VERSION ""

NS_ :

BS_:

BU_: PowertrainControlModule AtmosphericSensor SafetyRestraintSystem2 Aftertreatment_2_GasOutlet Aftertreatment_2_GasIntake DieselParticulateFilterControl Turbocharger SafetyRestraintSystem1 CabDisplay2 Aftertreatment_1_GasOutlet Aftertreatment_1_GasIntake OnBoardDataLogger OffBoardDiagnosticTool2 OffBoardDiagnosticTool1 FileServer ParkingBrakeController SeatController2 FanDriveController SteeringColumnUnit CommunicationUnitRadio CommunicationUnitSatellite CommunicationUnitCellular PropulsionBatteryCharger ChassisController2 ChassisController1 EngineValveControl AuxiliaryHeater2 AuxiliaryHeater1 ClutchUnit RampControl InformationSystem1 SuspensionSystemController2 OilSensor VehicleDynamicStability ExhaustEmissionController TransmissionDisplay2 TransmissionDisplay1 ClimateControl2 WaterPumpController RearAxleSteeringController LightingOperatorControl SeatController1 IgnitionController2 IgnitionController1 TirePressureController CabController2 CabController1 PneumaticSystemController SuspensionSystemController1 HydraulicPumpController EnduranceBrakingSystem RetarderExhaustEngine2 OnBoardDiagnosticUnit HeadwayController RetarderExhaustEngine1 CabDisplay1 ManagementComputer VirtualTerminal OffVehicleGateway PowerTakeOffFront HitchControl AuxiliaryValveControl BodyController TractorTrailerBridge1 StarterSystem ElectricalSystem VehicleSecurity VehicleNavigation AerodynamicControl ElectricalChargingSystem ClimateControl1 TripRecorder InstrumentCluster SuspensionDriveAxle2 SuspensionDriveAxle1 SuspensionSteerAxle SteeringController FuelSystem CruiseControl RetarderDriveline RetarderEngine BrakesDriveAxle2 BrakesDriveAxle1 BrakesSystemController BrakesSteerAxle AxleDrive2 AxleDrive1 AxleSteering PowerTakeOff ShiftConsoleSecondary ShiftConsolePrimary Transmission2 Transmission1 Engine2 Engine1

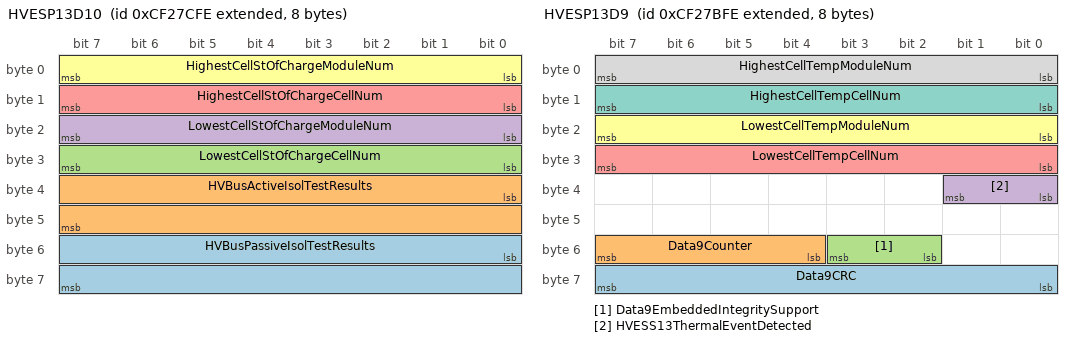
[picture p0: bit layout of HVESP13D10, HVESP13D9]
BO_ 2364701950 HVESP13D10: 8 Vector__XXX
 SG_ HVBusPassiveIsolTestResults : 48|16@1+ (0.1,0) [0|6425.5] "Ohm/V" Vector__XXX
 SG_ HVBusActiveIsolTestResults : 32|16@1+ (0.1,0) [0|6425.5] "Ohm/V" Vector__XXX
 SG_ LowestCellStOfChargeCellNum : 24|8@1+ (1,0) [0|250] "" Vector__XXX
 SG_ LowestCellStOfChargeModuleNum : 16|8@1+ (1,0) [0|250] "" Vector__XXX
 SG_ HighestCellStOfChargeCellNum : 8|8@1+ (1,0) [0|250] "" Vector__XXX
 SG_ HighestCellStOfChargeModuleNum : 0|8@1+ (1,0) [0|250] "" Vector__XXX

BO_ 2364701694 HVESP13D9: 8 Vector__XXX
 SG_ Data9CRC : 56|8@1+ (1,0) [0|255] "" Vector__XXX
 SG_ Data9Counter : 52|4@1+ (1,0) [0|15] "" Vector__XXX
 SG_ Data9EmbeddedIntegritySupport : 50|2@1+ (1,0) [0|3] "" Vector__XXX
 SG_ HVESS13ThermalEventDetected : 32|2@1+ (1,0) [0|3] "" Vector__XXX
 SG_ LowestCellTempCellNum : 24|8@1+ (1,0) [0|250] "" Vector__XXX
 SG_ LowestCellTempModuleNum : 16|8@1+ (1,0) [0|250] "" Vector__XXX
 SG_ HighestCellTempCellNum : 8|8@1+ (1,0) [0|250] "" Vector__XXX
 SG_ HighestCellTempModuleNum : 0|8@1+ (1,0) [0|250] "" Vector__XXX

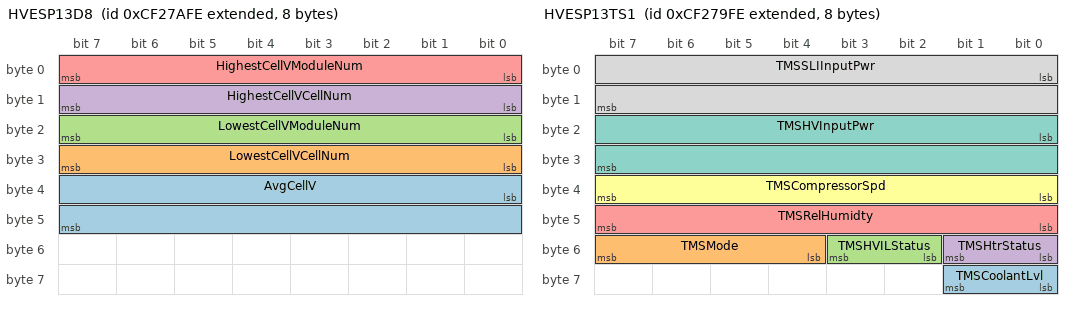
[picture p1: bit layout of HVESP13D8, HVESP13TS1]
BO_ 2364701438 HVESP13D8: 8 Vector__XXX
 SG_ AvgCellV : 32|16@1+ (0.001,0) [0|64.255] "V" Vector__XXX
 SG_ LowestCellVCellNum : 24|8@1+ (1,0) [0|250] "" Vector__XXX
 SG_ LowestCellVModuleNum : 16|8@1+ (1,0) [0|250] "" Vector__XXX
 SG_ HighestCellVCellNum : 8|8@1+ (1,0) [0|250] "" Vector__XXX
 SG_ HighestCellVModuleNum : 0|8@1+ (1,0) [0|250] "" Vector__XXX

BO_ 2364701182 HVESP13TS1: 8 Vector__XXX
 SG_ TMSCoolantLvl : 56|2@1+ (1,0) [0|3] "" Vector__XXX
 SG_ TMSMode : 52|4@1+ (1,0) [0|15] "" Vector__XXX
 SG_ TMSHVILStatus : 50|2@1+ (1,0) [0|3] "" Vector__XXX
 SG_ TMSHtrStatus : 48|2@1+ (1,0) [0|3] "" Vector__XXX
 SG_ TMSRelHumidty : 40|8@1+ (0.4,0) [0|100] "%" Vector__XXX
 SG_ TMSCompressorSpd : 32|8@1+ (32,0) [0|8000] "rpm" Vector__XXX
 SG_ TMSHVInputPwr : 16|16@1+ (0.5,0) [0|32127.5] "W" Vector__XXX
 SG_ TMSSLIInputPwr : 0|16@1+ (0.5,0) [0|32127.5] "W" Vector__XXX

BO_ 2364700926 HVESP13MS1: 8 Vector__XXX
 SG_ Module32OperationalStatus : 62|2@1+ (1,0) [0|3] "" Vector__XXX
 SG_ Module31OperationalStatus : 60|2@1+ (1,0) [0|3] "" Vector__XXX
 SG_ Module30OperationalStatus : 58|2@1+ (1,0) [0|3] "" Vector__XXX
 SG_ Module29OperationalStatus : 56|2@1+ (1,0) [0|3] "" Vector__XXX
 SG_ Module28OperationalStatus : 54|2@1+ (1,0) [0|3] "" Vector__XXX
 SG_ Module27OperationalStatus : 52|2@1+ (1,0) [0|3] "" Vector__XXX
 SG_ Module26OperationalStatus : 50|2@1+ (1,0) [0|3] "" Vector__XXX
 SG_ Module25OperationalStatus : 48|2@1+ (1,0) [0|3] "" Vector__XXX
 SG_ Module24OperationalStatus : 46|2@1+ (1,0) [0|3] "" Vector__XXX
 SG_ Module23OperationalStatus : 44|2@1+ (1,0) [0|3] "" Vector__XXX
 SG_ Module22OperationalStatus : 42|2@1+ (1,0) [0|3] "" Vector__XXX
 SG_ Module21OperationalStatus : 40|2@1+ (1,0) [0|3] "" Vector__XXX
 SG_ Module20OperationalStatus : 38|2@1+ (1,0) [0|3] "" Vector__XXX
 SG_ Module19OperationalStatus : 36|2@1+ (1,0) [0|3] "" Vector__XXX
 SG_ Module18OperationalStatus : 34|2@1+ (1,0) [0|3] "" Vector__XXX
 SG_ Module17OperationalStatus : 32|2@1+ (1,0) [0|3] "" Vector__XXX
 SG_ Module16OperationalStatus : 30|2@1+ (1,0) [0|3] "" Vector__XXX
 SG_ Module15OperationalStatus : 28|2@1+ (1,0) [0|3] "" Vector__XXX
 SG_ Module14OperationalStatus : 26|2@1+ (1,0) [0|3] "" Vector__XXX
 SG_ Module13OperationalStatus : 24|2@1+ (1,0) [0|3] "" Vector__XXX
 SG_ Module12OperationalStatus : 22|2@1+ (1,0) [0|3] "" Vector__XXX
 SG_ Module11OperationalStatus : 20|2@1+ (1,0) [0|3] "" Vector__XXX
 SG_ Module10OperationalStatus : 18|2@1+ (1,0) [0|3] "" Vector__XXX
 SG_ Module9OperationalStatus : 16|2@1+ (1,0) [0|3] "" Vector__XXX
 SG_ Module8OperationalStatus : 14|2@1+ (1,0) [0|3] "" Vector__XXX
 SG_ Module7OperationalStatus : 12|2@1+ (1,0) [0|3] "" Vector__XXX
 SG_ Module6OperationalStatus : 10|2@1+ (1,0) [0|3] "" Vector__XXX
 SG_ Module5OperationalStatus : 8|2@1+ (1,0) [0|3] "" Vector__XXX
 SG_ Module4OperationalStatus : 6|2@1+ (1,0) [0|3] "" Vector__XXX
 SG_ Module3OperationalStatus : 4|2@1+ (1,0) [0|3] "" Vector__XXX
 SG_ Module2OperationalStatus : 2|2@1+ (1,0) [0|3] "" Vector__XXX
 SG_ Module1OperationalStatus : 0|2@1+ (1,0) [0|3] "" Vector__XXX

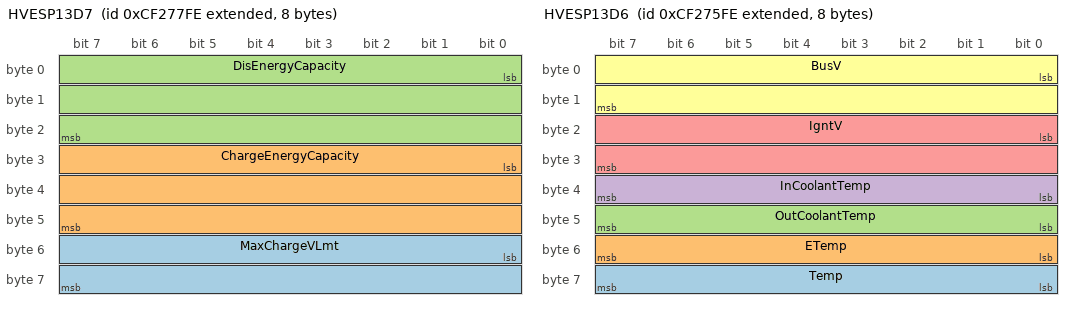
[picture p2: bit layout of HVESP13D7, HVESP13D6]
BO_ 2364700670 HVESP13D7: 8 Vector__XXX
 SG_ MaxChargeVLmt : 48|16@1+ (0.05,0) [0|3212.75] "V" Vector__XXX
 SG_ ChargeEnergyCapacity : 24|24@1+ (0.001,0) [0|16449.535] "kWh" Vector__XXX
 SG_ DisEnergyCapacity : 0|24@1+ (0.001,0) [0|16449.535] "kWh" Vector__XXX

BO_ 2364700414 HVESP13S1: 8 Vector__XXX
 SG_ Status1CRC : 56|8@1+ (1,0) [0|255] "" Vector__XXX
 SG_ Status1Counter : 52|4@1+ (1,0) [0|15] "" Vector__XXX
 SG_ OperationalStatus : 44|4@1+ (1,0) [0|15] "" Vector__XXX
 SG_ HVBusConnectionStatus : 40|4@1+ (1,0) [0|15] "" Vector__XXX
 SG_ InternalChargerStatus : 32|2@1+ (1,0) [0|3] "" Vector__XXX
 SG_ CellBalancingActive : 30|2@1+ (1,0) [0|3] "" Vector__XXX
 SG_ CellBalanceStatus : 28|2@1+ (1,0) [0|3] "" Vector__XXX
 SG_ StOfChargeStatus : 24|4@1+ (1,0) [0|15] "" Vector__XXX
 SG_ InertiaSwStatus : 22|2@1+ (1,0) [0|3] "" Vector__XXX
 SG_ HVILStatus : 20|2@1+ (1,0) [0|3] "" Vector__XXX
 SG_ HVBusPassiveIsolTestStatus : 16|4@1+ (1,0) [0|15] "" Vector__XXX
 SG_ HVBusActiveIsolTestStatus : 12|4@1+ (1,0) [0|15] "" Vector__XXX
 SG_ CenterOfPackContactorSt : 10|2@1+ (1,0) [0|3] "" Vector__XXX
 SG_ HVBusPreChargeRelaySt : 8|2@1+ (1,0) [0|3] "" Vector__XXX
 SG_ HVBusDisconnectForewarning : 4|4@1+ (1,0) [0|15] "" Vector__XXX
 SG_ HVBusContactorSt15602 : 2|2@1+ (1,0) [0|3] "" Vector__XXX
 SG_ HVBusContactorSt : 0|2@1+ (1,0) [0|3] "" Vector__XXX

BO_ 2364700158 HVESP13D6: 8 Vector__XXX
 SG_ Temp : 56|8@1+ (1,-40) [-40|210] "°C" Vector__XXX
 SG_ ETemp : 48|8@1+ (1,-40) [-40|210] "°C" Vector__XXX
 SG_ OutCoolantTemp : 40|8@1+ (1,-40) [-40|210] "°C" Vector__XXX
 SG_ InCoolantTemp : 32|8@1+ (1,-40) [-40|210] "°C" Vector__XXX
 SG_ IgntV : 16|16@1+ (0.01,0) [0|642.55] "V" Vector__XXX
 SG_ BusV : 0|16@1+ (0.05,0) [0|3212.75] "V" Vector__XXX

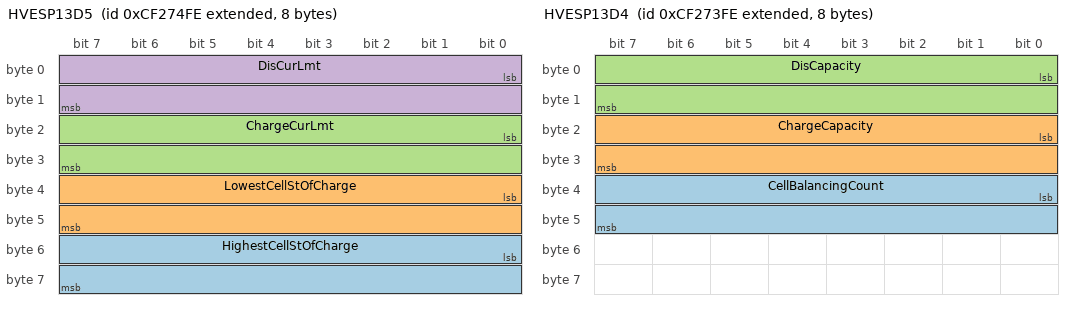
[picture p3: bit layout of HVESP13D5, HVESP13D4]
BO_ 2364699902 HVESP13D5: 8 Vector__XXX
 SG_ HighestCellStOfCharge : 48|16@1+ (0.0015625,0) [0|100.3984375] "%" Vector__XXX
 SG_ LowestCellStOfCharge : 32|16@1+ (0.0015625,0) [0|100.3984375] "%" Vector__XXX
 SG_ ChargeCurLmt : 16|16@1+ (0.05,-1600) [0|1612.75] "A" Vector__XXX
 SG_ DisCurLmt : 0|16@1+ (0.05,-1600) [-1600|0] "A" Vector__XXX

BO_ 2364699646 HVESP13D4: 8 Vector__XXX
 SG_ CellBalancingCount : 32|16@1+ (1,0) [0|64255] "" Vector__XXX
 SG_ ChargeCapacity : 16|16@1+ (0.01,0) [0|642.55] "Ah" Vector__XXX
 SG_ DisCapacity : 0|16@1+ (0.01,0) [0|642.55] "Ah" Vector__XXX

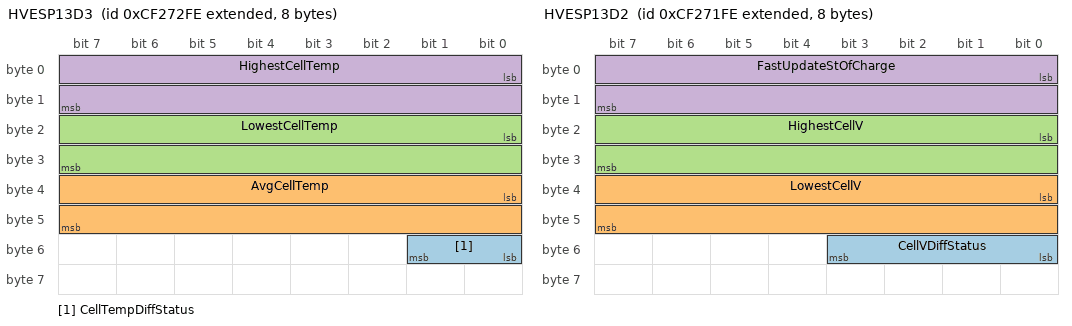
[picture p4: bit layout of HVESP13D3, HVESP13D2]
BO_ 2364699390 HVESP13D3: 8 Vector__XXX
 SG_ CellTempDiffStatus : 48|2@1+ (1,0) [0|3] "" Vector__XXX
 SG_ AvgCellTemp : 32|16@1+ (0.03125,-273) [-273|1734.96875] "°C" Vector__XXX
 SG_ LowestCellTemp : 16|16@1+ (0.03125,-273) [-273|1734.96875] "°C" Vector__XXX
 SG_ HighestCellTemp : 0|16@1+ (0.03125,-273) [-273|1734.96875] "°C" Vector__XXX

BO_ 2364699134 HVESP13D2: 8 Vector__XXX
 SG_ CellVDiffStatus : 48|4@1+ (1,0) [0|15] "" Vector__XXX
 SG_ LowestCellV : 32|16@1+ (0.001,0) [0|64.255] "V" Vector__XXX
 SG_ HighestCellV : 16|16@1+ (0.001,0) [0|64.255] "V" Vector__XXX
 SG_ FastUpdateStOfCharge : 0|16@1+ (0.0015625,0) [0|100.3984375] "%" Vector__XXX

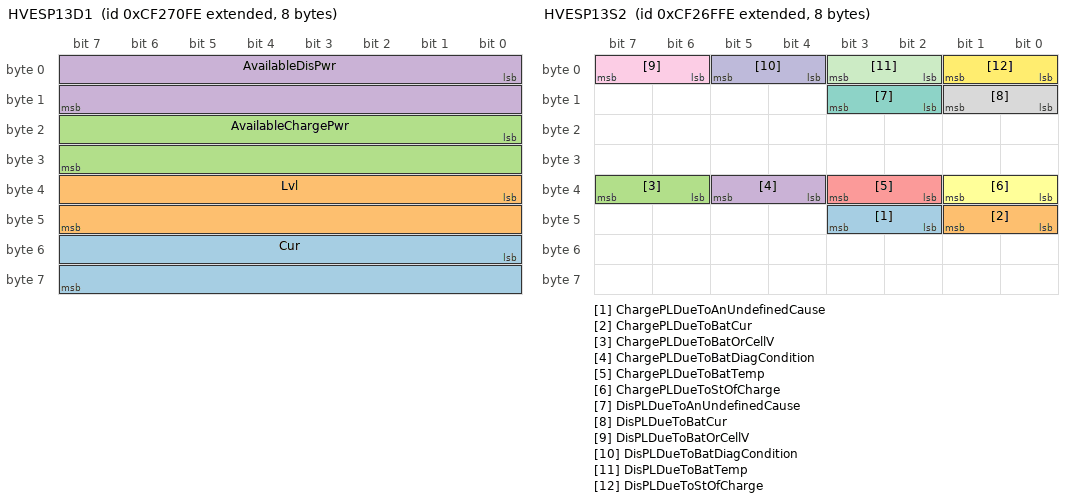
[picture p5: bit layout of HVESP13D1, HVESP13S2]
BO_ 2364698878 HVESP13D1: 8 Vector__XXX
 SG_ Cur : 48|16@1+ (0.05,-1600) [-1600|1612.75] "A" Vector__XXX
 SG_ Lvl : 32|16@1+ (0.05,0) [0|3212.75] "V" Vector__XXX
 SG_ AvailableChargePwr : 16|16@1+ (0.05,0) [0|3212.75] "kW" Vector__XXX
 SG_ AvailableDisPwr : 0|16@1+ (0.05,0) [0|3212.75] "kW" Vector__XXX

BO_ 2364698622 HVESP13S2: 8 Vector__XXX
 SG_ ChargePLDueToAnUndefinedCause : 42|2@1+ (1,0) [0|3] "" Vector__XXX
 SG_ ChargePLDueToBatCur : 40|2@1+ (1,0) [0|3] "" Vector__XXX
 SG_ ChargePLDueToBatOrCellV : 38|2@1+ (1,0) [0|3] "" Vector__XXX
 SG_ ChargePLDueToBatDiagCondition : 36|2@1+ (1,0) [0|3] "" Vector__XXX
 SG_ ChargePLDueToBatTemp : 34|2@1+ (1,0) [0|3] "" Vector__XXX
 SG_ ChargePLDueToStOfCharge : 32|2@1+ (1,0) [0|3] "" Vector__XXX
 SG_ DisPLDueToAnUndefinedCause : 10|2@1+ (1,0) [0|3] "" Vector__XXX
 SG_ DisPLDueToBatCur : 8|2@1+ (1,0) [0|3] "" Vector__XXX
 SG_ DisPLDueToBatOrCellV : 6|2@1+ (1,0) [0|3] "" Vector__XXX
 SG_ DisPLDueToBatDiagCondition : 4|2@1+ (1,0) [0|3] "" Vector__XXX
 SG_ DisPLDueToBatTemp : 2|2@1+ (1,0) [0|3] "" Vector__XXX
 SG_ DisPLDueToStOfCharge : 0|2@1+ (1,0) [0|3] "" Vector__XXX

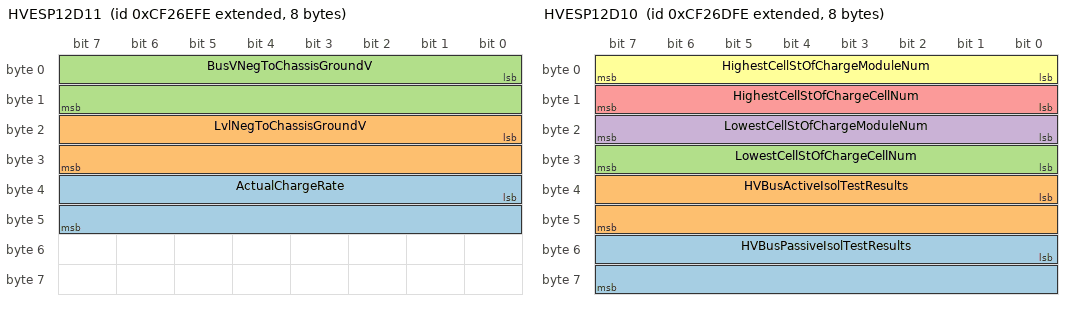
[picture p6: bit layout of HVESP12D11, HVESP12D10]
BO_ 2364698366 HVESP12D11: 8 Vector__XXX
 SG_ ActualChargeRate : 32|16@1+ (0.05,0) [0|3212.75] "kW" Vector__XXX
 SG_ LvlNegToChassisGroundV : 16|16@1+ (0.05,0) [0|3212.75] "V" Vector__XXX
 SG_ BusVNegToChassisGroundV : 0|16@1+ (0.05,0) [0|3212.75] "V" Vector__XXX

BO_ 2364698110 HVESP12D10: 8 Vector__XXX
 SG_ HVBusPassiveIsolTestResults : 48|16@1+ (0.1,0) [0|6425.5] "Ohm/V" Vector__XXX
 SG_ HVBusActiveIsolTestResults : 32|16@1+ (0.1,0) [0|6425.5] "Ohm/V" Vector__XXX
 SG_ LowestCellStOfChargeCellNum : 24|8@1+ (1,0) [0|250] "" Vector__XXX
 SG_ LowestCellStOfChargeModuleNum : 16|8@1+ (1,0) [0|250] "" Vector__XXX
 SG_ HighestCellStOfChargeCellNum : 8|8@1+ (1,0) [0|250] "" Vector__XXX
 SG_ HighestCellStOfChargeModuleNum : 0|8@1+ (1,0) [0|250] "" Vector__XXX

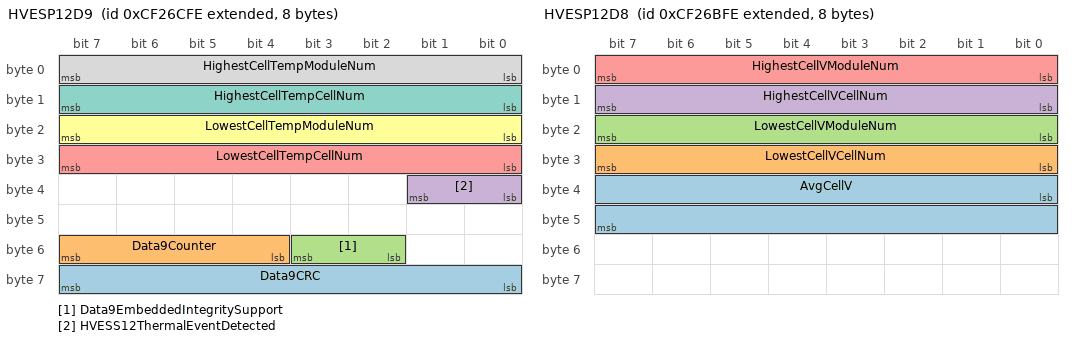
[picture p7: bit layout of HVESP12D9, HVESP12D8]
BO_ 2364697854 HVESP12D9: 8 Vector__XXX
 SG_ Data9CRC : 56|8@1+ (1,0) [0|255] "" Vector__XXX
 SG_ Data9Counter : 52|4@1+ (1,0) [0|15] "" Vector__XXX
 SG_ Data9EmbeddedIntegritySupport : 50|2@1+ (1,0) [0|3] "" Vector__XXX
 SG_ HVESS12ThermalEventDetected : 32|2@1+ (1,0) [0|3] "" Vector__XXX
 SG_ LowestCellTempCellNum : 24|8@1+ (1,0) [0|250] "" Vector__XXX
 SG_ LowestCellTempModuleNum : 16|8@1+ (1,0) [0|250] "" Vector__XXX
 SG_ HighestCellTempCellNum : 8|8@1+ (1,0) [0|250] "" Vector__XXX
 SG_ HighestCellTempModuleNum : 0|8@1+ (1,0) [0|250] "" Vector__XXX

BO_ 2364697598 HVESP12D8: 8 Vector__XXX
 SG_ AvgCellV : 32|16@1+ (0.001,0) [0|64.255] "V" Vector__XXX
 SG_ LowestCellVCellNum : 24|8@1+ (1,0) [0|250] "" Vector__XXX
 SG_ LowestCellVModuleNum : 16|8@1+ (1,0) [0|250] "" Vector__XXX
 SG_ HighestCellVCellNum : 8|8@1+ (1,0) [0|250] "" Vector__XXX
 SG_ HighestCellVModuleNum : 0|8@1+ (1,0) [0|250] "" Vector__XXX

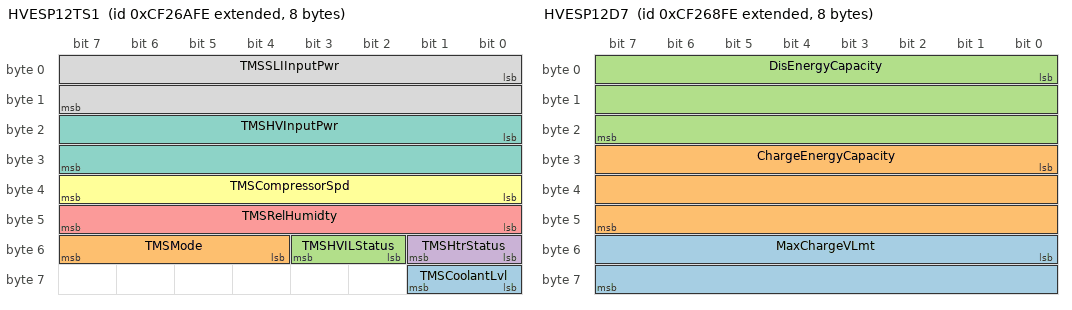
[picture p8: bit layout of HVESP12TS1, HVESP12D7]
BO_ 2364697342 HVESP12TS1: 8 Vector__XXX
 SG_ TMSCoolantLvl : 56|2@1+ (1,0) [0|3] "" Vector__XXX
 SG_ TMSMode : 52|4@1+ (1,0) [0|15] "" Vector__XXX
 SG_ TMSHVILStatus : 50|2@1+ (1,0) [0|3] "" Vector__XXX
 SG_ TMSHtrStatus : 48|2@1+ (1,0) [0|3] "" Vector__XXX
 SG_ TMSRelHumidty : 40|8@1+ (0.4,0) [0|100] "%" Vector__XXX
 SG_ TMSCompressorSpd : 32|8@1+ (32,0) [0|8000] "rpm" Vector__XXX
 SG_ TMSHVInputPwr : 16|16@1+ (0.5,0) [0|32127.5] "W" Vector__XXX
 SG_ TMSSLIInputPwr : 0|16@1+ (0.5,0) [0|32127.5] "W" Vector__XXX

BO_ 2364697086 HVESP12MS1: 8 Vector__XXX
 SG_ Module32OperationalStatus : 62|2@1+ (1,0) [0|3] "" Vector__XXX
 SG_ Module31OperationalStatus : 60|2@1+ (1,0) [0|3] "" Vector__XXX
 SG_ Module30OperationalStatus : 58|2@1+ (1,0) [0|3] "" Vector__XXX
 SG_ Module29OperationalStatus : 56|2@1+ (1,0) [0|3] "" Vector__XXX
 SG_ Module28OperationalStatus : 54|2@1+ (1,0) [0|3] "" Vector__XXX
 SG_ Module27OperationalStatus : 52|2@1+ (1,0) [0|3] "" Vector__XXX
 SG_ Module26OperationalStatus : 50|2@1+ (1,0) [0|3] "" Vector__XXX
 SG_ Module25OperationalStatus : 48|2@1+ (1,0) [0|3] "" Vector__XXX
 SG_ Module24OperationalStatus : 46|2@1+ (1,0) [0|3] "" Vector__XXX
 SG_ Module23OperationalStatus : 44|2@1+ (1,0) [0|3] "" Vector__XXX
 SG_ Module22OperationalStatus : 42|2@1+ (1,0) [0|3] "" Vector__XXX
 SG_ Module21OperationalStatus : 40|2@1+ (1,0) [0|3] "" Vector__XXX
 SG_ Module20OperationalStatus : 38|2@1+ (1,0) [0|3] "" Vector__XXX
 SG_ Module19OperationalStatus : 36|2@1+ (1,0) [0|3] "" Vector__XXX
 SG_ Module18OperationalStatus : 34|2@1+ (1,0) [0|3] "" Vector__XXX
 SG_ Module17OperationalStatus : 32|2@1+ (1,0) [0|3] "" Vector__XXX
 SG_ Module16OperationalStatus : 30|2@1+ (1,0) [0|3] "" Vector__XXX
 SG_ Module15OperationalStatus : 28|2@1+ (1,0) [0|3] "" Vector__XXX
 SG_ Module14OperationalStatus : 26|2@1+ (1,0) [0|3] "" Vector__XXX
 SG_ Module13OperationalStatus : 24|2@1+ (1,0) [0|3] "" Vector__XXX
 SG_ Module12OperationalStatus : 22|2@1+ (1,0) [0|3] "" Vector__XXX
 SG_ Module11OperationalStatus : 20|2@1+ (1,0) [0|3] "" Vector__XXX
 SG_ Module10OperationalStatus : 18|2@1+ (1,0) [0|3] "" Vector__XXX
 SG_ Module9OperationalStatus : 16|2@1+ (1,0) [0|3] "" Vector__XXX
 SG_ Module8OperationalStatus : 14|2@1+ (1,0) [0|3] "" Vector__XXX
 SG_ Module7OperationalStatus : 12|2@1+ (1,0) [0|3] "" Vector__XXX
 SG_ Module6OperationalStatus : 10|2@1+ (1,0) [0|3] "" Vector__XXX
 SG_ Module5OperationalStatus : 8|2@1+ (1,0) [0|3] "" Vector__XXX
 SG_ Module4OperationalStatus : 6|2@1+ (1,0) [0|3] "" Vector__XXX
 SG_ Module3OperationalStatus : 4|2@1+ (1,0) [0|3] "" Vector__XXX
 SG_ Module2OperationalStatus : 2|2@1+ (1,0) [0|3] "" Vector__XXX
 SG_ Module1OperationalStatus : 0|2@1+ (1,0) [0|3] "" Vector__XXX

BO_ 2364696830 HVESP12D7: 8 Vector__XXX
 SG_ MaxChargeVLmt : 48|16@1+ (0.05,0) [0|3212.75] "V" Vector__XXX
 SG_ ChargeEnergyCapacity : 24|24@1+ (0.001,0) [0|16449.535] "kWh" Vector__XXX
 SG_ DisEnergyCapacity : 0|24@1+ (0.001,0) [0|16449.535] "kWh" Vector__XXX

BO_ 2364696574 HVESP12S1: 8 Vector__XXX
 SG_ Status1CRC : 56|8@1+ (1,0) [0|255] "" Vector__XXX
 SG_ Status1Counter : 52|4@1+ (1,0) [0|15] "" Vector__XXX
 SG_ OperationalStatus : 44|4@1+ (1,0) [0|15] "" Vector__XXX
 SG_ HVBusConnectionStatus : 40|4@1+ (1,0) [0|15] "" Vector__XXX
 SG_ InternalChargerStatus : 32|2@1+ (1,0) [0|3] "" Vector__XXX
 SG_ CellBalancingActive : 30|2@1+ (1,0) [0|3] "" Vector__XXX
 SG_ CellBalanceStatus : 28|2@1+ (1,0) [0|3] "" Vector__XXX
 SG_ StOfChargeStatus : 24|4@1+ (1,0) [0|15] "" Vector__XXX
 SG_ InertiaSwStatus : 22|2@1+ (1,0) [0|3] "" Vector__XXX
 SG_ HVILStatus : 20|2@1+ (1,0) [0|3] "" Vector__XXX
 SG_ HVBusPassiveIsolTestStatus : 16|4@1+ (1,0) [0|15] "" Vector__XXX
 SG_ HVBusActiveIsolTestStatus : 12|4@1+ (1,0) [0|15] "" Vector__XXX
 SG_ CenterOfPackContactorSt : 10|2@1+ (1,0) [0|3] "" Vector__XXX
 SG_ HVBusPreChargeRelaySt : 8|2@1+ (1,0) [0|3] "" Vector__XXX
 SG_ HVBusDisconnectForewarning : 4|4@1+ (1,0) [0|15] "" Vector__XXX
 SG_ HVBusContactorSt15460 : 2|2@1+ (1,0) [0|3] "" Vector__XXX
 SG_ HVBusContactorSt : 0|2@1+ (1,0) [0|3] "" Vector__XXX

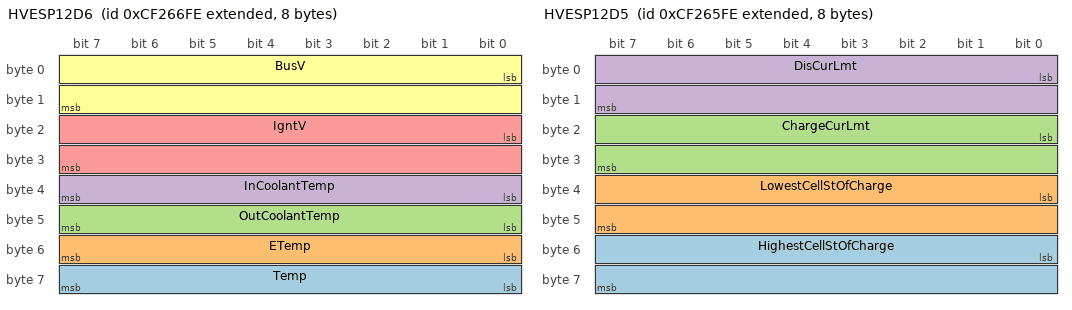
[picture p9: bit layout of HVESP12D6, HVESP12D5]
BO_ 2364696318 HVESP12D6: 8 Vector__XXX
 SG_ Temp : 56|8@1+ (1,-40) [-40|210] "°C" Vector__XXX
 SG_ ETemp : 48|8@1+ (1,-40) [-40|210] "°C" Vector__XXX
 SG_ OutCoolantTemp : 40|8@1+ (1,-40) [-40|210] "°C" Vector__XXX
 SG_ InCoolantTemp : 32|8@1+ (1,-40) [-40|210] "°C" Vector__XXX
 SG_ IgntV : 16|16@1+ (0.01,0) [0|642.55] "V" Vector__XXX
 SG_ BusV : 0|16@1+ (0.05,0) [0|3212.75] "V" Vector__XXX

BO_ 2364696062 HVESP12D5: 8 Vector__XXX
 SG_ HighestCellStOfCharge : 48|16@1+ (0.0015625,0) [0|100.3984375] "%" Vector__XXX
 SG_ LowestCellStOfCharge : 32|16@1+ (0.0015625,0) [0|100.3984375] "%" Vector__XXX
 SG_ ChargeCurLmt : 16|16@1+ (0.05,-1600) [0|1612.75] "A" Vector__XXX
 SG_ DisCurLmt : 0|16@1+ (0.05,-1600) [-1600|0] "A" Vector__XXX

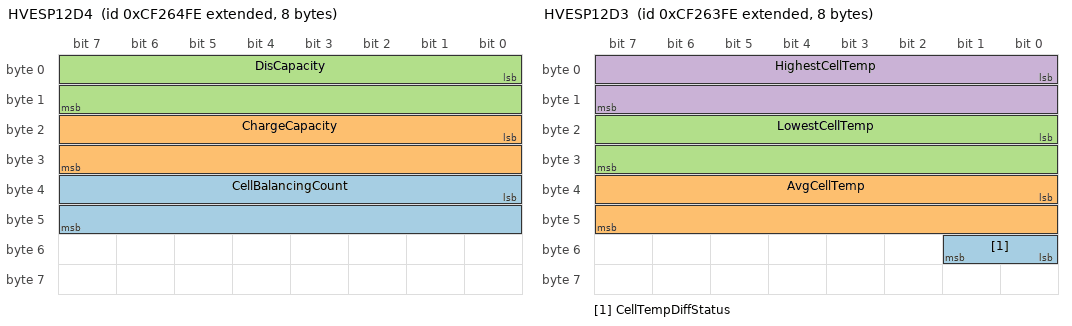
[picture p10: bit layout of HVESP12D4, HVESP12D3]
BO_ 2364695806 HVESP12D4: 8 Vector__XXX
 SG_ CellBalancingCount : 32|16@1+ (1,0) [0|64255] "" Vector__XXX
 SG_ ChargeCapacity : 16|16@1+ (0.01,0) [0|642.55] "Ah" Vector__XXX
 SG_ DisCapacity : 0|16@1+ (0.01,0) [0|642.55] "Ah" Vector__XXX

BO_ 2364695550 HVESP12D3: 8 Vector__XXX
 SG_ CellTempDiffStatus : 48|2@1+ (1,0) [0|3] "" Vector__XXX
 SG_ AvgCellTemp : 32|16@1+ (0.03125,-273) [-273|1734.96875] "°C" Vector__XXX
 SG_ LowestCellTemp : 16|16@1+ (0.03125,-273) [-273|1734.96875] "°C" Vector__XXX
 SG_ HighestCellTemp : 0|16@1+ (0.03125,-273) [-273|1734.96875] "°C" Vector__XXX

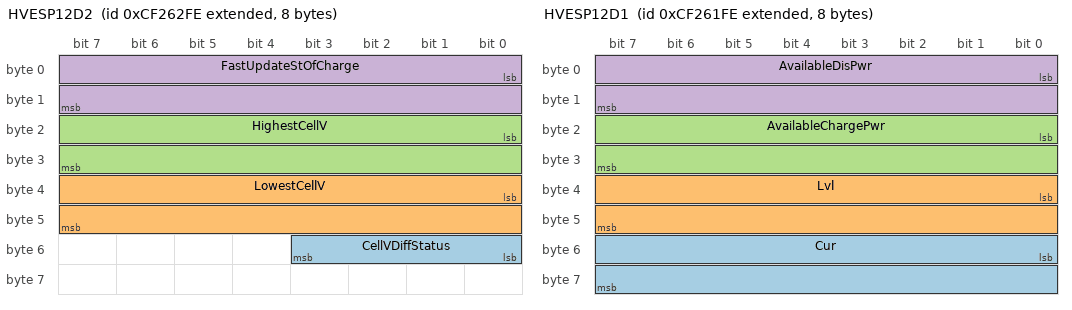
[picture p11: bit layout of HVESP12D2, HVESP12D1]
BO_ 2364695294 HVESP12D2: 8 Vector__XXX
 SG_ CellVDiffStatus : 48|4@1+ (1,0) [0|15] "" Vector__XXX
 SG_ LowestCellV : 32|16@1+ (0.001,0) [0|64.255] "V" Vector__XXX
 SG_ HighestCellV : 16|16@1+ (0.001,0) [0|64.255] "V" Vector__XXX
 SG_ FastUpdateStOfCharge : 0|16@1+ (0.0015625,0) [0|100.3984375] "%" Vector__XXX

BO_ 2364695038 HVESP12D1: 8 Vector__XXX
 SG_ Cur : 48|16@1+ (0.05,-1600) [-1600|1612.75] "A" Vector__XXX
 SG_ Lvl : 32|16@1+ (0.05,0) [0|3212.75] "V" Vector__XXX
 SG_ AvailableChargePwr : 16|16@1+ (0.05,0) [0|3212.75] "kW" Vector__XXX
 SG_ AvailableDisPwr : 0|16@1+ (0.05,0) [0|3212.75] "kW" Vector__XXX

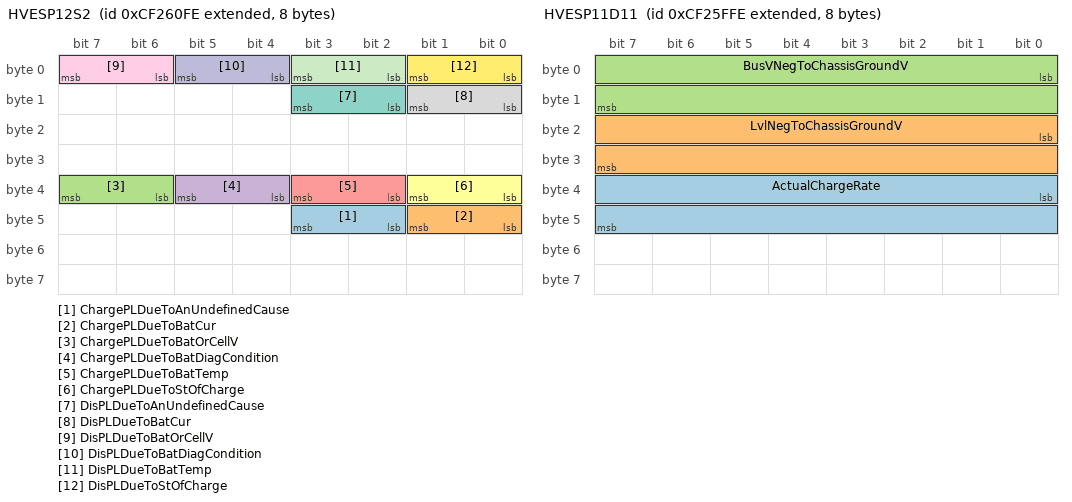
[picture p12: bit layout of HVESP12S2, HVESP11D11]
BO_ 2364694782 HVESP12S2: 8 Vector__XXX
 SG_ ChargePLDueToAnUndefinedCause : 42|2@1+ (1,0) [0|3] "" Vector__XXX
 SG_ ChargePLDueToBatCur : 40|2@1+ (1,0) [0|3] "" Vector__XXX
 SG_ ChargePLDueToBatOrCellV : 38|2@1+ (1,0) [0|3] "" Vector__XXX
 SG_ ChargePLDueToBatDiagCondition : 36|2@1+ (1,0) [0|3] "" Vector__XXX
 SG_ ChargePLDueToBatTemp : 34|2@1+ (1,0) [0|3] "" Vector__XXX
 SG_ ChargePLDueToStOfCharge : 32|2@1+ (1,0) [0|3] "" Vector__XXX
 SG_ DisPLDueToAnUndefinedCause : 10|2@1+ (1,0) [0|3] "" Vector__XXX
 SG_ DisPLDueToBatCur : 8|2@1+ (1,0) [0|3] "" Vector__XXX
 SG_ DisPLDueToBatOrCellV : 6|2@1+ (1,0) [0|3] "" Vector__XXX
 SG_ DisPLDueToBatDiagCondition : 4|2@1+ (1,0) [0|3] "" Vector__XXX
 SG_ DisPLDueToBatTemp : 2|2@1+ (1,0) [0|3] "" Vector__XXX
 SG_ DisPLDueToStOfCharge : 0|2@1+ (1,0) [0|3] "" Vector__XXX

BO_ 2364694526 HVESP11D11: 8 Vector__XXX
 SG_ ActualChargeRate : 32|16@1+ (0.05,0) [0|3212.75] "kW" Vector__XXX
 SG_ LvlNegToChassisGroundV : 16|16@1+ (0.05,0) [0|3212.75] "V" Vector__XXX
 SG_ BusVNegToChassisGroundV : 0|16@1+ (0.05,0) [0|3212.75] "V" Vector__XXX

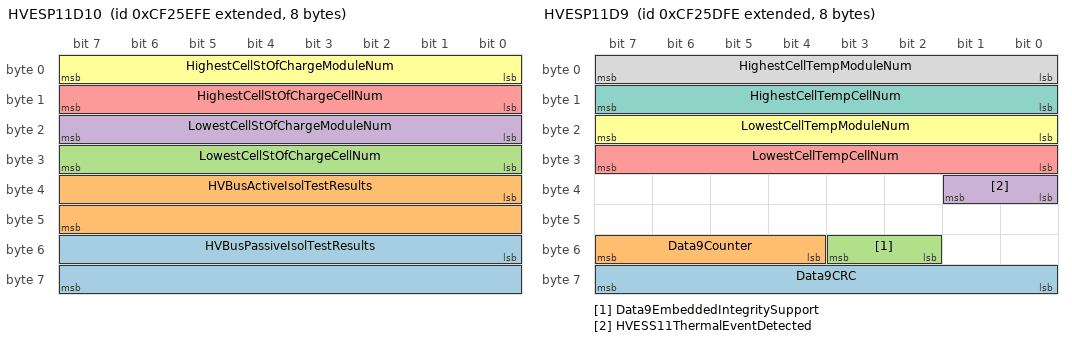
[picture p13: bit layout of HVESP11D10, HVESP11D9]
BO_ 2364694270 HVESP11D10: 8 Vector__XXX
 SG_ HVBusPassiveIsolTestResults : 48|16@1+ (0.1,0) [0|6425.5] "Ohm/V" Vector__XXX
 SG_ HVBusActiveIsolTestResults : 32|16@1+ (0.1,0) [0|6425.5] "Ohm/V" Vector__XXX
 SG_ LowestCellStOfChargeCellNum : 24|8@1+ (1,0) [0|250] "" Vector__XXX
 SG_ LowestCellStOfChargeModuleNum : 16|8@1+ (1,0) [0|250] "" Vector__XXX
 SG_ HighestCellStOfChargeCellNum : 8|8@1+ (1,0) [0|250] "" Vector__XXX
 SG_ HighestCellStOfChargeModuleNum : 0|8@1+ (1,0) [0|250] "" Vector__XXX

BO_ 2364694014 HVESP11D9: 8 Vector__XXX
 SG_ Data9CRC : 56|8@1+ (1,0) [0|255] "" Vector__XXX
 SG_ Data9Counter : 52|4@1+ (1,0) [0|15] "" Vector__XXX
 SG_ Data9EmbeddedIntegritySupport : 50|2@1+ (1,0) [0|3] "" Vector__XXX
 SG_ HVESS11ThermalEventDetected : 32|2@1+ (1,0) [0|3] "" Vector__XXX
 SG_ LowestCellTempCellNum : 24|8@1+ (1,0) [0|250] "" Vector__XXX
 SG_ LowestCellTempModuleNum : 16|8@1+ (1,0) [0|250] "" Vector__XXX
 SG_ HighestCellTempCellNum : 8|8@1+ (1,0) [0|250] "" Vector__XXX
 SG_ HighestCellTempModuleNum : 0|8@1+ (1,0) [0|250] "" Vector__XXX

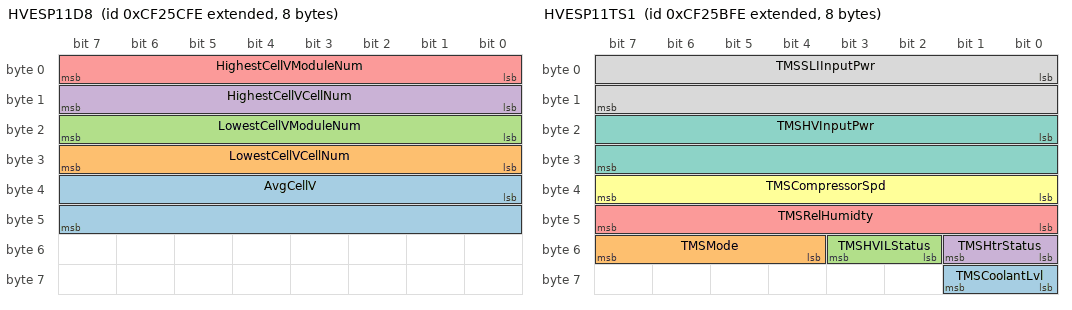
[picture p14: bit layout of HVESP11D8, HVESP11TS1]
BO_ 2364693758 HVESP11D8: 8 Vector__XXX
 SG_ AvgCellV : 32|16@1+ (0.001,0) [0|64.255] "V" Vector__XXX
 SG_ LowestCellVCellNum : 24|8@1+ (1,0) [0|250] "" Vector__XXX
 SG_ LowestCellVModuleNum : 16|8@1+ (1,0) [0|250] "" Vector__XXX
 SG_ HighestCellVCellNum : 8|8@1+ (1,0) [0|250] "" Vector__XXX
 SG_ HighestCellVModuleNum : 0|8@1+ (1,0) [0|250] "" Vector__XXX

BO_ 2364693502 HVESP11TS1: 8 Vector__XXX
 SG_ TMSCoolantLvl : 56|2@1+ (1,0) [0|3] "" Vector__XXX
 SG_ TMSMode : 52|4@1+ (1,0) [0|15] "" Vector__XXX
 SG_ TMSHVILStatus : 50|2@1+ (1,0) [0|3] "" Vector__XXX
 SG_ TMSHtrStatus : 48|2@1+ (1,0) [0|3] "" Vector__XXX
 SG_ TMSRelHumidty : 40|8@1+ (0.4,0) [0|100] "%" Vector__XXX
 SG_ TMSCompressorSpd : 32|8@1+ (32,0) [0|8000] "rpm" Vector__XXX
 SG_ TMSHVInputPwr : 16|16@1+ (0.5,0) [0|32127.5] "W" Vector__XXX
 SG_ TMSSLIInputPwr : 0|16@1+ (0.5,0) [0|32127.5] "W" Vector__XXX

BO_ 2364693246 HVESP11MS1: 8 Vector__XXX
 SG_ Module32OperationalStatus : 62|2@1+ (1,0) [0|3] "" Vector__XXX
 SG_ Module31OperationalStatus : 60|2@1+ (1,0) [0|3] "" Vector__XXX
 SG_ Module30OperationalStatus : 58|2@1+ (1,0) [0|3] "" Vector__XXX
 SG_ Module29OperationalStatus : 56|2@1+ (1,0) [0|3] "" Vector__XXX
 SG_ Module28OperationalStatus : 54|2@1+ (1,0) [0|3] "" Vector__XXX
 SG_ Module27OperationalStatus : 52|2@1+ (1,0) [0|3] "" Vector__XXX
 SG_ Module26OperationalStatus : 50|2@1+ (1,0) [0|3] "" Vector__XXX
 SG_ Module25OperationalStatus : 48|2@1+ (1,0) [0|3] "" Vector__XXX
 SG_ Module24OperationalStatus : 46|2@1+ (1,0) [0|3] "" Vector__XXX
 SG_ Module23OperationalStatus : 44|2@1+ (1,0) [0|3] "" Vector__XXX
 SG_ Module22OperationalStatus : 42|2@1+ (1,0) [0|3] "" Vector__XXX
 SG_ Module21OperationalStatus : 40|2@1+ (1,0) [0|3] "" Vector__XXX
 SG_ Module20OperationalStatus : 38|2@1+ (1,0) [0|3] "" Vector__XXX
 SG_ Module19OperationalStatus : 36|2@1+ (1,0) [0|3] "" Vector__XXX
 SG_ Module18OperationalStatus : 34|2@1+ (1,0) [0|3] "" Vector__XXX
 SG_ Module17OperationalStatus : 32|2@1+ (1,0) [0|3] "" Vector__XXX
 SG_ Module16OperationalStatus : 30|2@1+ (1,0) [0|3] "" Vector__XXX
 SG_ Module15OperationalStatus : 28|2@1+ (1,0) [0|3] "" Vector__XXX
 SG_ Module14OperationalStatus : 26|2@1+ (1,0) [0|3] "" Vector__XXX
 SG_ Module13OperationalStatus : 24|2@1+ (1,0) [0|3] "" Vector__XXX
 SG_ Module12OperationalStatus : 22|2@1+ (1,0) [0|3] "" Vector__XXX
 SG_ Module11OperationalStatus : 20|2@1+ (1,0) [0|3] "" Vector__XXX
 SG_ Module10OperationalStatus : 18|2@1+ (1,0) [0|3] "" Vector__XXX
 SG_ Module9OperationalStatus : 16|2@1+ (1,0) [0|3] "" Vector__XXX
 SG_ Module8OperationalStatus : 14|2@1+ (1,0) [0|3] "" Vector__XXX
 SG_ Module7OperationalStatus : 12|2@1+ (1,0) [0|3] "" Vector__XXX
 SG_ Module6OperationalStatus : 10|2@1+ (1,0) [0|3] "" Vector__XXX
 SG_ Module5OperationalStatus : 8|2@1+ (1,0) [0|3] "" Vector__XXX
 SG_ Module4OperationalStatus : 6|2@1+ (1,0) [0|3] "" Vector__XXX
 SG_ Module3OperationalStatus : 4|2@1+ (1,0) [0|3] "" Vector__XXX
 SG_ Module2OperationalStatus : 2|2@1+ (1,0) [0|3] "" Vector__XXX
 SG_ Module1OperationalStatus : 0|2@1+ (1,0) [0|3] "" Vector__XXX

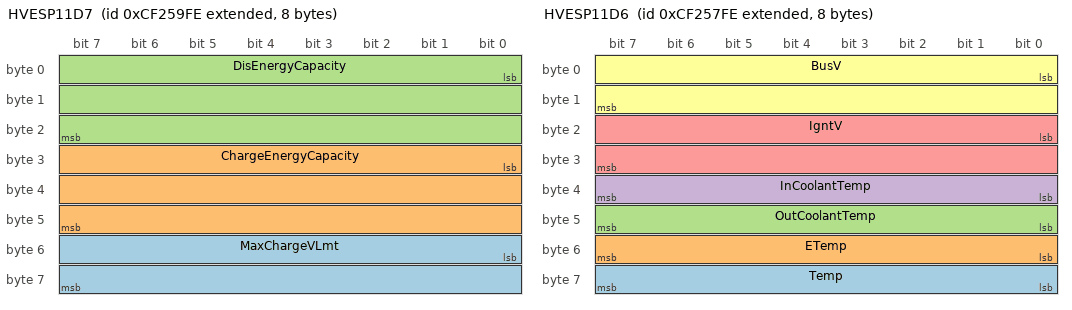
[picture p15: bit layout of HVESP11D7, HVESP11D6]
BO_ 2364692990 HVESP11D7: 8 Vector__XXX
 SG_ MaxChargeVLmt : 48|16@1+ (0.05,0) [0|3212.75] "V" Vector__XXX
 SG_ ChargeEnergyCapacity : 24|24@1+ (0.001,0) [0|16449.535] "kWh" Vector__XXX
 SG_ DisEnergyCapacity : 0|24@1+ (0.001,0) [0|16449.535] "kWh" Vector__XXX

BO_ 2364692734 HVESP11S1: 8 Vector__XXX
 SG_ Status1CRC : 56|8@1+ (1,0) [0|255] "" Vector__XXX
 SG_ Status1Counter : 52|4@1+ (1,0) [0|15] "" Vector__XXX
 SG_ OperationalStatus : 44|4@1+ (1,0) [0|15] "" Vector__XXX
 SG_ HVBusConnectionStatus : 40|4@1+ (1,0) [0|15] "" Vector__XXX
 SG_ InternalChargerStatus : 32|2@1+ (1,0) [0|3] "" Vector__XXX
 SG_ CellBalancingActive : 30|2@1+ (1,0) [0|3] "" Vector__XXX
 SG_ CellBalanceStatus : 28|2@1+ (1,0) [0|3] "" Vector__XXX
 SG_ StOfChargeStatus : 24|4@1+ (1,0) [0|15] "" Vector__XXX
 SG_ InertiaSwStatus : 22|2@1+ (1,0) [0|3] "" Vector__XXX
 SG_ HVILStatus : 20|2@1+ (1,0) [0|3] "" Vector__XXX
 SG_ HVBusPassiveIsolTestStatus : 16|4@1+ (1,0) [0|15] "" Vector__XXX
 SG_ HVBusActiveIsolTestStatus : 12|4@1+ (1,0) [0|15] "" Vector__XXX
 SG_ CenterOfPackContactorSt : 10|2@1+ (1,0) [0|3] "" Vector__XXX
 SG_ HVBusPreChargeRelaySt : 8|2@1+ (1,0) [0|3] "" Vector__XXX
 SG_ HVBusDisconnectForewarning : 4|4@1+ (1,0) [0|15] "" Vector__XXX
 SG_ HVBusContactorSt15318 : 2|2@1+ (1,0) [0|3] "" Vector__XXX
 SG_ HVBusContactorSt : 0|2@1+ (1,0) [0|3] "" Vector__XXX

BO_ 2364692478 HVESP11D6: 8 Vector__XXX
 SG_ Temp : 56|8@1+ (1,-40) [-40|210] "°C" Vector__XXX
 SG_ ETemp : 48|8@1+ (1,-40) [-40|210] "°C" Vector__XXX
 SG_ OutCoolantTemp : 40|8@1+ (1,-40) [-40|210] "°C" Vector__XXX
 SG_ InCoolantTemp : 32|8@1+ (1,-40) [-40|210] "°C" Vector__XXX
 SG_ IgntV : 16|16@1+ (0.01,0) [0|642.55] "V" Vector__XXX
 SG_ BusV : 0|16@1+ (0.05,0) [0|3212.75] "V" Vector__XXX

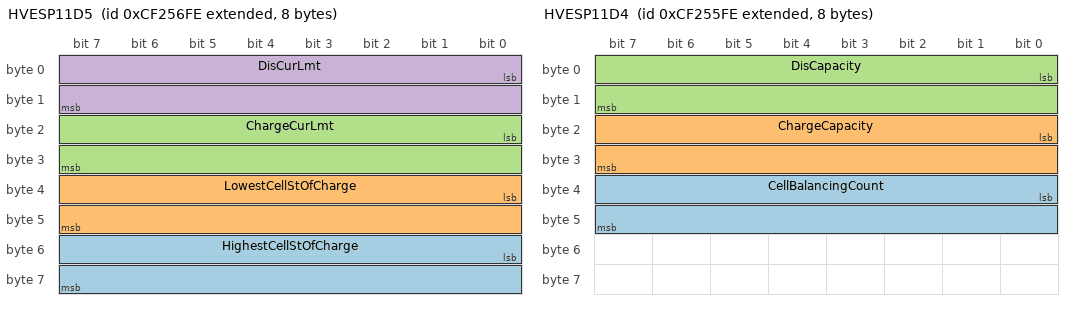
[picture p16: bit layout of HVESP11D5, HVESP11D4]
BO_ 2364692222 HVESP11D5: 8 Vector__XXX
 SG_ HighestCellStOfCharge : 48|16@1+ (0.0015625,0) [0|100.3984375] "%" Vector__XXX
 SG_ LowestCellStOfCharge : 32|16@1+ (0.0015625,0) [0|100.3984375] "%" Vector__XXX
 SG_ ChargeCurLmt : 16|16@1+ (0.05,-1600) [0|1612.75] "A" Vector__XXX
 SG_ DisCurLmt : 0|16@1+ (0.05,-1600) [-1600|0] "A" Vector__XXX

BO_ 2364691966 HVESP11D4: 8 Vector__XXX
 SG_ CellBalancingCount : 32|16@1+ (1,0) [0|64255] "" Vector__XXX
 SG_ ChargeCapacity : 16|16@1+ (0.01,0) [0|642.55] "Ah" Vector__XXX
 SG_ DisCapacity : 0|16@1+ (0.01,0) [0|642.55] "Ah" Vector__XXX

CM_ BO_ 2364701950 "High Voltage Energy Storage Pack 13 Data 10
Data set 10 (electrical) for High Voltage Energy Storage Pack 13.";
CM_ SG_ 2364701950 HVBusPassiveIsolTestResults "The isolation resistance expressed in Ohms per Volt that resulted from the High-Voltage Bus Passive Isolation Test.
See SPN 15607 (HVESP13 High-Voltage Bus Passive Isolation Test Status) for test status and SPN 15556 (HVESP13 High-Voltage Bus ...";
CM_ SG_ 2364701950 HVBusActiveIsolTestResults "The isolation resistance expressed in Ohms per Volt that resulted from the High-Voltage Bus Active Isolation Test.
See SPN 15606 (HVESP13 High-Voltage Bus Active Isolation Test Status) for test status and SPN 15555 (HVESP13 High-Voltage Bus Active ...";
CM_ SG_ 2364701950 LowestCellStOfChargeCellNum "Identifies the location of SPN 15593 (HVESP13 Lowest Cell State of Charge) within SPN 15672 (HVESP13 Lowest Cell State of Charge Module Number).
This parameter is for one of multiple packs in an HVESS. If there is only one pack in the system, the ...";
CM_ SG_ 2364701950 LowestCellStOfChargeModuleNum "Identifies the location of the module containing SPN 15593 (HVESP13 Lowest Cell State of Charge).
This parameter is for one of multiple packs in an HVESS. If there is only one pack in the system, the HVESS parameters should be used. If there are ...";
CM_ SG_ 2364701950 HighestCellStOfChargeCellNum "Identifies the location of SPN 15594 (HVESP13 Highest Cell State of Charge) within SPN 15670 (HVESP13 Highest Cell State of Charge Module Number).
This parameter is for one of multiple packs in an HVESS. If there is only one pack in the system, the ...";
CM_ SG_ 2364701950 HighestCellStOfChargeModuleNum "Identifies the location of the module containing SPN 15594 (HVESP13 Highest Cell State of Charge).
This parameter is for one of multiple packs in an HVESS. If there is only one pack in the system, the HVESS parameters should be used. If there are ...";
CM_ BO_ 2364701694 "High Voltage Energy Storage Pack 13 Data 9
Data set 9 (thermal) for High Voltage Energy Storage Pack 13.";
CM_ SG_ 2364701694 Data9CRC "The CRC is defined as follows:
• Length: 8 bits
• Polynomial: x^8+x^5+x^3+x^2+x+1
• Initial Value: FFh
• Input Data Reflection: Not reflected
• Result Data Reflection: Not reflected
• XOR value: FFh
SAE makes no claim of the functional safety ...";
CM_ SG_ 2364701694 Data9Counter "The message counter is used to detect situations where the transmitting ECU malfunction repeats the same frame all the time. The receiver of the information may use the counter parameter to detect this situation. The transmitting device will ...";
CM_ SG_ 2364701694 Data9EmbeddedIntegritySupport "Indicates SPN 23012 (HVESP13 Data 9 CRC) and SPN 23011 (HVESP13 Data 9 Counter) are supported by the sender.
00b = Embedded CRC and Counter are supported by the sender
01b = Protection is supported using J1939-76 SHM
10b = Reserved
11b = CRC and ...";
CM_ SG_ 2364701694 HVESS13ThermalEventDetected "A sensor has detected the presence of a thermal event at or near High Voltage Energy Storage Pack instance.
00b = No Thermal Event Detected
01b = Thermal Event Detected
10b = Error
11b = Not available
This parameter is for one of multiple packs ...";
CM_ SG_ 2364701694 LowestCellTempCellNum "Identifies the location of SPN 15585 (HVESP13 Lowest Cell Temperature) within SPN 15668 (HVESP13 Lowest Cell Temperature Module Number).
This parameter is for one of multiple packs in an HVESS. If there is only one pack in the system, the HVESS ...";
CM_ SG_ 2364701694 LowestCellTempModuleNum "Identifies the location of the module containing SPN 15585 (HVESP13 Lowest Cell Temperature).
This parameter is for one of multiple packs in an HVESS. If there is only one pack in the system, the HVESS parameters should be used. If there are ...";
CM_ SG_ 2364701694 HighestCellTempCellNum "Identifies the location of SPN 15584 (HVESP13 Highest Cell Temperature) within SPN 15666 (HVESP13 Highest Cell Temperature Module Number).
This parameter is for one of multiple packs in an HVESS. If there is only one pack in the system, the HVESS ...";
CM_ SG_ 2364701694 HighestCellTempModuleNum "Identifies the location of the module containing SPN 15584 (HVESP13 Highest Cell Temperature).
This parameter is for one of multiple packs in an HVESS. If there is only one pack in the system, the HVESS parameters should be used. If there are ...";
CM_ BO_ 2364701438 "High Voltage Energy Storage Pack 13 Data 8
Data set 8 (electrical data) for High Voltage Energy Storage Pack 13.";
CM_ SG_ 2364701438 AvgCellV "The average cell voltage in this High Voltage Energy Storage Pack instance.
This parameter is for one of multiple packs in an HVESS.  If there is only one pack in the system, the HVESS parameters should be used. If there are multiple packs in the ...";
CM_ SG_ 2364701438 LowestCellVCellNum "Identifies the location of SPN 15582 (HVESP13 Lowest Cell Voltage) within SPN 15663 (HVESP13 Lowest Cell Voltage Module Number).
This parameter is for one of multiple packs in an HVESS. If there is only one pack in the system, the HVESS parameters ...";
CM_ SG_ 2364701438 LowestCellVModuleNum "Identifies the location of the module containing SPN 15582 (HVESP13 Lowest Cell Voltage).
This parameter is for one of multiple packs in an HVESS. If there is only one pack in the system, the HVESS parameters should be used. If there are multiple ...";
CM_ SG_ 2364701438 HighestCellVCellNum "Identifies the location of SPN 15581 (HVESP13 Highest Cell Voltage) within SPN 15661 (HVESP13 Highest Cell Voltage Module Number).
This parameter is for one of multiple packs in an HVESS. If there is only one pack in the system, the HVESS ...";
CM_ SG_ 2364701438 HighestCellVModuleNum "Identifies the location of the module containing SPN 15581 (HVESP13 Highest Cell Voltage).
This parameter is for one of multiple packs in an HVESS. If there is only one pack in the system, the HVESS parameters should be used. If there are multiple ...";
CM_ BO_ 2364701182 "High Voltage Energy Storage Pack 13 Thermal Management System Status 1
Collection of data the High Voltage Energy Storage Pack 13 Thermal Management System sends to the Hybrid Controller.";
CM_ SG_ 2364701182 TMSCoolantLvl "Indicates the coolant level in this HVES Thermal Management System (TMS).
This parameter is for one of multiple packs in an HVESS.  If there is only one pack in the system, the HVESS parameters should be used. If there are multiple packs in the ...";
CM_ SG_ 2364701182 TMSMode "Indicates the operating mode of the Thermal Management System.  The heat transfer medium may be (e.g. liquid or air).  The cooling system may be fans, liquid coolant, or a combination of mediums.  The system may include an air and/or liquid ...";
CM_ SG_ 2364701182 TMSHVILStatus "In multiple HVES configurations, this is the status of the High Voltage Interlock Loop from the viewpoint of this Thermal Management System.
00b = HVIL Closed
01b = HVIL Open
10b = Error
11b = Not Available
This parameter is for one of multiple ...";
CM_ SG_ 2364701182 TMSHtrStatus "The state of this High Voltage Energy Storage Pack heater
This parameter is for one of multiple packs in an HVESS.  If there is only one pack in the system, the HVESS parameters should be used. If there are multiple packs in the system, then both ...";
CM_ SG_ 2364701182 TMSRelHumidty "When this High Voltage Energy Storage Pack Thermal Management System is equipped with a relative humidity sensor, this is the  measured Relative Humidity.
This parameter is for one of multiple packs in an HVESS.  If there is only one pack in the ...";
CM_ SG_ 2364701182 TMSCompressorSpd "When this High Voltage Energy Storage Pack Thermal Management System is equipped with an active cooling system (e.g. air conditioner), this is the Compressor Speed.
This parameter is for one of multiple packs in an HVESS.  If there is only one pack ...";
CM_ SG_ 2364701182 TMSHVInputPwr "This is the high-voltage power consumed by this HVES Thermal Management System (TMS).
This parameter is for one of multiple packs in an HVESS.  If there is only one pack in the system, the HVESS parameters should be used. If there are multiple ...";
CM_ SG_ 2364701182 TMSSLIInputPwr "This is the low-voltage power consumed by this HVES Thermal Management System (TMS).
This parameter is for one of multiple packs in an HVESS.  If there is only one pack in the system, the HVESS parameters should be used.  If there are multiple ...";
CM_ BO_ 2364700926 "High Voltage Energy Storage Pack 13 Module Status 1
Module Status message 1 for High Voltage Energy Storage Pack 13.";
CM_ SG_ 2364700926 Module32OperationalStatus "Operational Status of Module 32 in this High Voltage Energy Storage Pack Instance.  Not Operational is used when the module is initializing or not able to function (e.g. internal module level monitors have failed).  Operational indicates that the ...";
CM_ SG_ 2364700926 Module31OperationalStatus "Operational Status of Module 31 in this High Voltage Energy Storage Pack Instance.  Not Operational is used when the module is initializing or not able to function (e.g. internal module level monitors have failed).  Operational indicates that the ...";
CM_ SG_ 2364700926 Module30OperationalStatus "Operational Status of Module 30 in this High Voltage Energy Storage Pack Instance.  Not Operational is used when the module is initializing or not able to function (e.g. internal module level monitors have failed).  Operational indicates that the ...";
CM_ SG_ 2364700926 Module29OperationalStatus "Operational Status of Module 29 in this High Voltage Energy Storage Pack Instance.  Not Operational is used when the module is initializing or not able to function (e.g. internal module level monitors have failed).  Operational indicates that the ...";
CM_ SG_ 2364700926 Module28OperationalStatus "Operational Status of Module 28 in this High Voltage Energy Storage Pack Instance.  Not Operational is used when the module is initializing or not able to function (e.g. internal module level monitors have failed).  Operational indicates that the ...";
CM_ SG_ 2364700926 Module27OperationalStatus "Operational Status of Module 27 in this High Voltage Energy Storage Pack Instance.  Not Operational is used when the module is initializing or not able to function (e.g. internal module level monitors have failed).  Operational indicates that the ...";
CM_ SG_ 2364700926 Module26OperationalStatus "Operational Status of Module 26 in this High Voltage Energy Storage Pack Instance.  Not Operational is used when the module is initializing or not able to function (e.g. internal module level monitors have failed).  Operational indicates that the ...";
CM_ SG_ 2364700926 Module25OperationalStatus "Operational Status of Module 25 in this High Voltage Energy Storage Pack Instance.  Not Operational is used when the module is initializing or not able to function (e.g. internal module level monitors have failed).  Operational indicates that the ...";
CM_ SG_ 2364700926 Module24OperationalStatus "Operational Status of Module 24 in this High Voltage Energy Storage Pack Instance.  Not Operational is used when the module is initializing or not able to function (e.g. internal module level monitors have failed).  Operational indicates that the ...";
CM_ SG_ 2364700926 Module23OperationalStatus "Operational Status of Module 23 in this High Voltage Energy Storage Pack Instance.  Not Operational is used when the module is initializing or not able to function (e.g. internal module level monitors have failed).  Operational indicates that the ...";
CM_ SG_ 2364700926 Module22OperationalStatus "Operational Status of Module 22 in this High Voltage Energy Storage Pack Instance.  Not Operational is used when the module is initializing or not able to function (e.g. internal module level monitors have failed).  Operational indicates that the ...";
CM_ SG_ 2364700926 Module21OperationalStatus "Operational Status of Module 21 in this High Voltage Energy Storage Pack Instance.  Not Operational is used when the module is initializing or not able to function (e.g. internal module level monitors have failed).  Operational indicates that the ...";
CM_ SG_ 2364700926 Module20OperationalStatus "Operational Status of Module 20 in this High Voltage Energy Storage Pack Instance.  Not Operational is used when the module is initializing or not able to function (e.g. internal module level monitors have failed).  Operational indicates that the ...";
CM_ SG_ 2364700926 Module19OperationalStatus "Operational Status of Module 19 in this High Voltage Energy Storage Pack Instance.  Not Operational is used when the module is initializing or not able to function (e.g. internal module level monitors have failed).  Operational indicates that the ...";
CM_ SG_ 2364700926 Module18OperationalStatus "Operational Status of Module 18 in this High Voltage Energy Storage Pack Instance.  Not Operational is used when the module is initializing or not able to function (e.g. internal module level monitors have failed).  Operational indicates that the ...";
CM_ SG_ 2364700926 Module17OperationalStatus "Operational Status of Module 17 in this High Voltage Energy Storage Pack Instance.  Not Operational is used when the module is initializing or not able to function (e.g. internal module level monitors have failed).  Operational indicates that the ...";
CM_ SG_ 2364700926 Module16OperationalStatus "Operational Status of Module 16 in this High Voltage Energy Storage Pack Instance.  Not Operational is used when the module is initializing or not able to function (e.g. internal module level monitors have failed).  Operational indicates that the ...";
CM_ SG_ 2364700926 Module15OperationalStatus "Operational Status of Module 15 in this High Voltage Energy Storage Pack Instance.  Not Operational is used when the module is initializing or not able to function (e.g. internal module level monitors have failed).  Operational indicates that the ...";
CM_ SG_ 2364700926 Module14OperationalStatus "Operational Status of Module 14 in this High Voltage Energy Storage Pack Instance.  Not Operational is used when the module is initializing or not able to function (e.g. internal module level monitors have failed).  Operational indicates that the ...";
CM_ SG_ 2364700926 Module13OperationalStatus "Operational Status of Module 13 in this High Voltage Energy Storage Pack Instance.  Not Operational is used when the module is initializing or not able to function (e.g. internal module level monitors have failed).  Operational indicates that the ...";
CM_ SG_ 2364700926 Module12OperationalStatus "Operational Status of Module 12 in this High Voltage Energy Storage Pack Instance.  Not Operational is used when the module is initializing or not able to function (e.g. internal module level monitors have failed).  Operational indicates that the ...";
CM_ SG_ 2364700926 Module11OperationalStatus "Operational Status of Module 11 in this High Voltage Energy Storage Pack Instance.  Not Operational is used when the module is initializing or not able to function (e.g. internal module level monitors have failed).  Operational indicates that the ...";
CM_ SG_ 2364700926 Module10OperationalStatus "Operational Status of Module 10 in this High Voltage Energy Storage Pack Instance.  Not Operational is used when the module is initializing or not able to function (e.g. internal module level monitors have failed).  Operational indicates that the ...";
CM_ SG_ 2364700926 Module9OperationalStatus "Operational Status of Module 9 in this High Voltage Energy Storage Pack Instance.  Not Operational is used when the module is initializing or not able to function (e.g. internal module level monitors have failed).  Operational indicates that the ...";
CM_ SG_ 2364700926 Module8OperationalStatus "Operational Status of Module 8 in this High Voltage Energy Storage Pack Instance.  Not Operational is used when the module is initializing or not able to function (e.g. internal module level monitors have failed).  Operational indicates that the ...";
CM_ SG_ 2364700926 Module7OperationalStatus "Operational Status of Module 7 in this High Voltage Energy Storage Pack Instance.  Not Operational is used when the module is initializing or not able to function (e.g. internal module level monitors have failed).  Operational indicates that the ...";
CM_ SG_ 2364700926 Module6OperationalStatus "Operational Status of Module 6 in this High Voltage Energy Storage Pack Instance.  Not Operational is used when the module is initializing or not able to function (e.g. internal module level monitors have failed).  Operational indicates that the ...";
CM_ SG_ 2364700926 Module5OperationalStatus "Operational Status of Module 5 in this High Voltage Energy Storage Pack Instance.  Not Operational is used when the module is initializing or not able to function (e.g. internal module level monitors have failed).  Operational indicates that the ...";
CM_ SG_ 2364700926 Module4OperationalStatus "Operational Status of Module 4 in this High Voltage Energy Storage Pack Instance.  Not Operational is used when the module is initializing or not able to function (e.g. internal module level monitors have failed).  Operational indicates that the ...";
CM_ SG_ 2364700926 Module3OperationalStatus "Operational Status of Module 3 in this High Voltage Energy Storage Pack Instance.  Not Operational is used when the module is initializing or not able to function (e.g. internal module level monitors have failed).  Operational indicates that the ...";
CM_ SG_ 2364700926 Module2OperationalStatus "Operational Status of Module 2 in this High Voltage Energy Storage Pack Instance.  Not Operational is used when the module is initializing or not able to function (e.g. internal module level monitors have failed).  Operational indicates that the ...";
CM_ SG_ 2364700926 Module1OperationalStatus "Operational Status of Module 1 in this High Voltage Energy Storage Pack Instance.  Not Operational is used when the module is initializing or not able to function (e.g. internal module level monitors have failed).  Operational indicates that the ...";
CM_ BO_ 2364700670 "High Voltage Energy Storage Pack 13 Data 7
Data set 7 (electrical) for High Voltage Energy Storage Pack 13.";
CM_ SG_ 2364700670 MaxChargeVLmt "The maximum voltage level not to be exceeded while charging this High Voltage Energy Storage Pack instance. If this parameter is not supported, the maximum charge voltage should be limited to SPN 15687 (HVESP13 Recommended Maximum Operating ...";
CM_ SG_ 2364700670 ChargeEnergyCapacity "The amount of unused electrical energy storage available to be filled by charging this High Voltage Energy Storage Pack instance, i.e. “how much empty space is remaining in the tank”. See SPN 15589 (HVESP13 Charge Capacity) for Ampere-hours (Ah).
 ...";
CM_ SG_ 2364700670 DisEnergyCapacity "The amount of stored electrical energy in this High Voltage Energy Storage Pack instance that is available for use by the hybrid system, i.e. “how full is the tank”. See SPN 15588 (HVESP13 Discharge Capacity) for Ampere-hours (Ah).
This parameter ...";
CM_ BO_ 2364700414 "High Voltage Energy Storage Pack 13 Status 1
Status data set 1 for High Voltage Energy Storage Pack 13.";
CM_ SG_ 2364700414 Status1CRC "The CRC is defined as follows:
• Length: 8 bits
• Polynomial: x^8+x^5+x^3+x^2+x+1
• Initial Value: FFh
• Input Data Reflection: Not reflected
• Result Data Reflection: Not reflected
• XOR value: FFh
SAE makes no claim of the functional safety ...";
CM_ SG_ 2364700414 Status1Counter "The message counter is used to detect situations where the transmitting ECU malfunction repeats the same frame all the time. The receiver of the information may use the counter parameter to detect this situation. The transmitting device will ...";
CM_ SG_ 2364700414 OperationalStatus "Provides feedback on where this High Voltage Energy Storage Pack instance is in its operating spectrum, and includes feedback in response to the Operation Consent [i.e. SPN 15559 (HVESP13 Operation Consent)] and Power Down Command [i.e. SPN 15554 ...";
CM_ SG_ 2364700414 HVBusConnectionStatus "This parameter provides high level feedback on this High Voltage Energy Storage Pack instance high voltage bus connection. For specific contactor information, see SPN 15601 (HVESP13 High-Voltage Bus (Positive) Contactor State), SPN 15602 (HVESP13 ...";
CM_ SG_ 2364700414 InternalChargerStatus "Indicates that the charger in this HVES instance is on.  External chargers may use the External Energy Source Connection Status (SPN 7898) and related SPs.
This parameter is for one of multiple packs in an HVESS. If there is only one pack in the ...";
CM_ SG_ 2364700414 CellBalancingActive "Indicates whether or not the cells in this High Voltage Energy Storage Pack instance are currently being balanced.
This parameter is for one of multiple packs in an HVESS.  If there is only one pack in the system, the HVESS parameters should be ...";
CM_ SG_ 2364700414 CellBalanceStatus "Indicates whether or not the cells in this High Voltage Energy Storage Pack instance are balanced.
This parameter is for one of multiple packs in an HVESS.  If there is only one pack in the system, the HVESS parameters should be used. If there are ...";
CM_ SG_ 2364700414 StOfChargeStatus "Status of this High Voltage Energy Storage Pack instance State of Charge (SOC).  Note:  A given HVES controller may not support all of the states.
This parameter is for one of multiple packs in an HVESS.  If there is only one pack in the system, ...";
CM_ SG_ 2364700414 InertiaSwStatus "Switch indicating that an impact has been sensed by this High Voltage Energy Storage Pack instance. The impact indication may require action by another controller, or by this HVES instance itself.  For example, a controller may elect to take this ...";
CM_ SG_ 2364700414 HVILStatus "Status of the High Voltage Interlock Loop from the viewpoint of this High Voltage Energy Storage Pack instance.
This parameter is for one of multiple packs in an HVESS. If there is only one pack in the system, the HVESS parameters should be used ...";
CM_ SG_ 2364700414 HVBusPassiveIsolTestStatus "Status of the high-voltage bus electrical passive isolation test as performed by this High Voltage Energy Storage Pack instance.
This parameter is for one of multiple packs in an HVESS. If there is only one pack in the system, the HVESS parameters ...";
CM_ SG_ 2364700414 HVBusActiveIsolTestStatus "Status of the high-voltage bus electrical active isolation test as performed by this High Voltage Energy Storage Pack instance.
This parameter is for one of multiple packs in an HVESS. If there is only one pack in the system, the HVESS parameters ...";
CM_ SG_ 2364700414 CenterOfPackContactorSt "Position of the center high-voltage contactor. When this contactor is closed, the positive half of this High Voltage Energy Storage Pack instance is connected to the negative half. If a system controls the positive, negative, and center contactors ...";
CM_ SG_ 2364700414 HVBusPreChargeRelaySt "Position of the high-voltage bus contactor pre-charge relay.  When this relay is closed, this High Voltage Energy Storage Pack instance is bringing the high-voltage bus up to its operating level.
This parameter is for one of multiple packs in an ...";
CM_ SG_ 2364700414 HVBusDisconnectForewarning "Indicates that this High Voltage Energy Storage Pack instance is about to disconnect from the high voltage bus due to unacceptable conditions.
This parameter is for one of multiple packs in an HVESS. If there is only one pack in the system, the ...";
CM_ SG_ 2364700414 HVBusContactorSt15602 "Position of this High Voltage Energy Storage Pack instance negative side bus contactor. When this contactor is closed, the negative side of this HVES instance is connected to the negative side of the high-voltage bus. If a system controls the ...";
CM_ SG_ 2364700414 HVBusContactorSt "Position of this High Voltage Energy Storage Pack instance positive side bus contactor.  When this contactor is closed, the positive side of this HVES instance is connected to the positive side of the high-voltage bus.  In systems where all ...";
CM_ BO_ 2364700158 "High Voltage Energy Storage Pack 13 Data 6
Data set 6 (external or interface data) for High Voltage Energy Storage Pack 13.";
CM_ SG_ 2364700158 Temp "The temperature of this High Voltage Energy Storage Pack instance. The value may be determined from a unique sensor specifically for this purpose, or by aggregating various temperature sensor readings within the pack.
This parameter is for one of ...";
CM_ SG_ 2364700158 ETemp "The temperature of the electronics or control modules in this High Voltage Energy Storage Pack instance.  If there are multiple temperature sensors then this parameter would be set to the maximum sensor reading.
This parameter is for one of ...";
CM_ SG_ 2364700158 OutCoolantTemp "The temperature of liquid coolant as it exits this High Voltage Energy Storage Pack instance.
This parameter is for one of multiple packs in an HVESS.  If there is only one pack in the system, the HVESS parameters should be used. If there are ...";
CM_ SG_ 2364700158 InCoolantTemp "The temperature of liquid coolant as it enters this High Voltage Energy Storage Pack instance.
This parameter is for one of multiple packs in an HVESS.  If there is only one pack in the system, the HVESS parameters should be used. If there are ...";
CM_ SG_ 2364700158 IgntV "The voltage level at the ignition input of this High Voltage Energy Storage Pack controller.
This parameter is for one of multiple packs in an HVESS.  If there is only one pack in the system, the HVESS parameters should be used.  If there are ...";
CM_ SG_ 2364700158 BusV "The voltage level of the high voltage bus, as measured by this High Voltage Energy Storage Pack instance on the bus side (not the battery side) of its contactors.
This parameter is for one of multiple packs in an HVESS.  If there is only one pack ...";
CM_ BO_ 2364699902 "High Voltage Energy Storage Pack 13 Data 5
Data set 5 (electrical data) for High Voltage Energy Storage Pack 13.";
CM_ SG_ 2364699902 HighestCellStOfCharge "Indicates the state of charge of the highest-charged cell in this High Voltage Energy Storage Pack instance. 0% means no charge remaining, 100% means the cell is fully charged. If a single state of charge value covers more than one cell, the value ...";
CM_ SG_ 2364699902 LowestCellStOfCharge "Indicates the state of charge of the lowest-charged cell in this High Voltage Energy Storage Pack instance. 0% means no charge remaining, 100% means the cell is fully charged. If a single state of charge value covers more than one cell, the value in ...";
CM_ SG_ 2364699902 ChargeCurLmt "The maximum instantaneous current flow limit into this High Voltage Energy Storage Pack instance. This parameter is defined from the high voltage energy storage pack's point of view and should reflect the instantaneous capability of the pack.  The ...";
CM_ SG_ 2364699902 DisCurLmt "The maximum instantaneous current flow limit out of this High Voltage Energy Storage Pack instance. This parameter is defined from the high voltage energy storage pack's point of view and should reflect the instantaneous capability of the pack.  The ...";
CM_ BO_ 2364699646 "High Voltage Energy Storage Pack 13 Data 4
Data set 4 (electrical data) for High Voltage Energy Storage Pack 13.";
CM_ SG_ 2364699646 CellBalancingCount "The number of cells that are currently being balanced in this High Voltage Energy Storage Pack instance.
This parameter is for one of multiple packs in an HVESS.  If there is only one pack in the system, the HVESS parameters should be used.  If ...";
CM_ SG_ 2364699646 ChargeCapacity "The amount of unused electrical charge storage in this High Voltage Energy Storage Pack instance that is available to be filled by charging, i.e. “how much empty space is remaining in the tank”. See SPN 15619 (HVESP13 Charge Energy Capacity) for ...";
CM_ SG_ 2364699646 DisCapacity "The amount of stored electrical charge in this High Voltage Energy Storage Pack instance that is available for use by the hybrid system, i.e. “how full is the tank”. See SPN 15618 (HVESP13 Discharge Energy Capacity) for kilowatt-hours (kWh).
This ...";
CM_ BO_ 2364699390 "High Voltage Energy Storage Pack 13 Data 3
Data set 3 (thermal data) for High Voltage Energy Storage Pack 13.";
CM_ SG_ 2364699390 CellTempDiffStatus "Indicates whether or not the differential between the highest and lowest cell temperatures are within acceptable limits per this High Voltage Energy Storage Pack instance. The actual temperature differential can be calculated by subtracting SPN ...";
CM_ SG_ 2364699390 AvgCellTemp "The average temperature level of all cells in this High Voltage Energy Storage Pack instance.
This parameter is for one of multiple packs in an HVESS.  If there is only one pack in the system, the HVESS parameters should be used.  If there are ...";
CM_ SG_ 2364699390 LowestCellTemp "The lowest temperature level reported by any cell in this High Voltage Energy Storage Pack instance. If a single temperature sensor covers more than one cell, the value in this parameter is for the smallest group of cells measured. See SPN 15668 ...";
CM_ SG_ 2364699390 HighestCellTemp "The highest temperature level reported by any cell in this High Voltage Energy Storage Pack instance. If a single temperature sensor covers more than one cell, the value in this parameter is for the smallest group of cells measured. See SPN 15666 ...";
CM_ BO_ 2364699134 "High Voltage Energy Storage Pack 13 Data 2
Data set 2 (electrical data) for High Voltage Energy Storage Pack 13.";
CM_ SG_ 2364699134 CellVDiffStatus "Indicates whether or not the differential between the highest and lowest cell voltages are within acceptable limits, according to this High Voltage Energy Storage Pack instance. The actual voltage differential can be calculated by subtracting SPN ...";
CM_ SG_ 2364699134 LowestCellV "The lowest voltage level reported by any cell in this High Voltage Energy Storage Pack instance. If a single voltage sensor covers more than one cell, the value in this parameter is for the smallest group of cells measured. See SPN 15663 (HVESP13 ...";
CM_ SG_ 2364699134 HighestCellV "The highest voltage level reported by any cell in this High Voltage Energy Storage Pack instance. If a single voltage sensor covers more than one cell, the value in this parameter is for the smallest group of cells measured. See SPN 15661 (HVESP13 ...";
CM_ SG_ 2364699134 FastUpdateStOfCharge "Indicates this High Voltage Energy Storage Pack instance state of charge. 0% means no charge remaining, 100% means the system is fully charged in terms of physical limits of this energy storage pack instance. Acceptable state of charge upper and ...";
CM_ BO_ 2364698878 "High Voltage Energy Storage Pack 13 Data 1
Data set 1 (electrical data) for High Voltage Energy Storage Pack 13.";
CM_ SG_ 2364698878 Cur "The current in or out of this High Voltage Energy Storage Pack instance. This parameter should be synchronized with SPN 15578 (HVESP13 Voltage Level) such that a realized power value can be calculated. This parameter is defined from the high voltage ...";
CM_ SG_ 2364698878 Lvl "The voltage level of this High Voltage Energy Storage Pack instance. This parameter should be synchronized with SPN 15579 (HVESP13 Current) such that a realized power value can be calculated. If the HVES component physically contains the contactors ...";
CM_ SG_ 2364698878 AvailableChargePwr "The rate at which this High Voltage Energy Storage Pack instance can currently receive energy from a regenerative or recharging system.
This parameter is for one of multiple packs in an HVESS.  If there is only one pack in the system, the HVESS ...";
CM_ SG_ 2364698878 AvailableDisPwr "The rate at which this High Voltage Energy Storage Pack instance can currently provide energy for propulsion or other uses.
This parameter is for one of multiple packs in an HVESS.  If there is only one pack in the system, the HVESS parameters ...";
CM_ BO_ 2364698622 "High Voltage Energy Storage Pack 13 Status 2
Status data set 2 for High Voltage Energy Storage Pack 13.";
CM_ SG_ 2364698622 ChargePLDueToAnUndefinedCause "Indicates whether or not charge power of this HVES instance is being limited due to an undefined cause.
This parameter is for one of multiple packs in an HVESS.  If there is only one pack in the system, the HVESS parameters should be used. If there ...";
CM_ SG_ 2364698622 ChargePLDueToBatCur "Indicates whether or not charge power of this HVES instance is being limited due to battery current.
This parameter is for one of multiple packs in an HVESS.  If there is only one pack in the system, the HVESS parameters should be used. If there ...";
CM_ SG_ 2364698622 ChargePLDueToBatOrCellV "Indicates whether or not charge power of this HVES instance is being limited due to a battery or cell voltage level.
This parameter is for one of multiple packs in an HVESS.  If there is only one pack in the system, the HVESS parameters should be ...";
CM_ SG_ 2364698622 ChargePLDueToBatDiagCondition "Indicates whether or not charge power of this HVES instance is being limited due to a battery diagnostic condition.
This parameter is for one of multiple packs in an HVESS.  If there is only one pack in the system, the HVESS parameters should be ...";
CM_ SG_ 2364698622 ChargePLDueToBatTemp "Indicates whether or not charge power of this HVES instance is being limited due to battery temperature.
This parameter is for one of multiple packs in an HVESS.  If there is only one pack in the system, the HVESS parameters should be used. If ...";
CM_ SG_ 2364698622 ChargePLDueToStOfCharge "Indicates whether or not charge power of this HVES instance is being limited due to state of charge.
This parameter is for one of multiple packs in an HVESS.  If there is only one pack in the system, the HVESS parameters should be used. If there ...";
CM_ SG_ 2364698622 DisPLDueToAnUndefinedCause "Indicates whether or not discharge power of this HVES instance is being limited due to an undefined cause.
This parameter is for one of multiple packs in an HVESS.  If there is only one pack in the system, the HVESS parameters should be used. If ...";
CM_ SG_ 2364698622 DisPLDueToBatCur "Indicates whether or not discharge power of this HVES instance is being limited due to battery current.
This parameter is for one of multiple packs in an HVESS.  If there is only one pack in the system, the HVESS parameters should be used. If there ...";
CM_ SG_ 2364698622 DisPLDueToBatOrCellV "Indicates whether or not discharge power of this HVES instance is being limited due to a battery or cell voltage level.
This parameter is for one of multiple packs in an HVESS.  If there is only one pack in the system, the HVESS parameters should ...";
CM_ SG_ 2364698622 DisPLDueToBatDiagCondition "Indicates whether or not discharge power of this HVES instance is being limited due to a battery diagnostic condition.
This parameter is for one of multiple packs in an HVESS.  If there is only one pack in the system, the HVESS parameters should be ...";
CM_ SG_ 2364698622 DisPLDueToBatTemp "Indicates whether or not discharge power of this HVES instance is being limited due to battery temperature.
This parameter is for one of multiple packs in an HVESS.  If there is only one pack in the system, the HVESS parameters should be used. If ...";
CM_ SG_ 2364698622 DisPLDueToStOfCharge "Indicates whether or not discharge power of this HVES instance is being limited due to state of charge.
This parameter is for one of multiple packs in an HVESS.  If there is only one pack in the system, the HVESS parameters should be used. If there ...";
CM_ BO_ 2364698366 "High Voltage Energy Storage Pack 12 Data 11
Data set 11 (electrical data) for High Voltage Energy Storage Pack 12.";
CM_ SG_ 2364698366 ActualChargeRate "This signal represents the actual present charge rate of this High Voltage Energy Storage Pack instance.
This parameter is for one of multiple packs in an HVESS. If there is only one pack in the system, the HVESS parameters should be used. If there ...";
CM_ SG_ 2364698366 LvlNegToChassisGroundV "Voltage difference between the most negative terminal of the HVES battery and chassis measured at the battery side of any HVES contained output contactor.  This voltage may be used for system level monitoring of battery shorts to chassis within the ...";
CM_ SG_ 2364698366 BusVNegToChassisGroundV "Voltage difference between the most negative terminal of the HVES battery and chassis measured on the hybrid system bus side (not the battery side) of any HVES contained output contactor.  This voltage may be used for system level monitoring of ...";
CM_ BO_ 2364698110 "High Voltage Energy Storage Pack 12 Data 10
Data set 10 (electrical) for High Voltage Energy Storage Pack 12.";
CM_ SG_ 2364698110 HVBusPassiveIsolTestResults "The isolation resistance expressed in Ohms per Volt that resulted from the High-Voltage Bus Passive Isolation Test.
See SPN 15465 (HVESP12 High-Voltage Bus Passive Isolation Test Status) for test status and SPN 15414 (HVESP12 High-Voltage Bus ...";
CM_ SG_ 2364698110 HVBusActiveIsolTestResults "The isolation resistance expressed in Ohms per Volt that resulted from the High-Voltage Bus Active Isolation Test.
See SPN 15464 (HVESP12 High-Voltage Bus Active Isolation Test Status) for test status and SPN 15413 (HVESP12 High-Voltage Bus Active ...";
CM_ SG_ 2364698110 LowestCellStOfChargeCellNum "Identifies the location of SPN 15451 (HVESP12 Lowest Cell State of Charge) within SPN 15530 (HVESP12 Lowest Cell State of Charge Module Number).
This parameter is for one of multiple packs in an HVESS. If there is only one pack in the system, the ...";
CM_ SG_ 2364698110 LowestCellStOfChargeModuleNum "Identifies the location of the module containing SPN 15451 (HVESP12 Lowest Cell State of Charge).
This parameter is for one of multiple packs in an HVESS. If there is only one pack in the system, the HVESS parameters should be used. If there are ...";
CM_ SG_ 2364698110 HighestCellStOfChargeCellNum "Identifies the location of SPN 15452 (HVESP12 Highest Cell State of Charge) within SPN 15528 (HVESP12 Highest Cell State of Charge Module Number).
This parameter is for one of multiple packs in an HVESS. If there is only one pack in the system, the ...";
CM_ SG_ 2364698110 HighestCellStOfChargeModuleNum "Identifies the location of the module containing SPN 15452 (HVESP12 Highest Cell State of Charge).
This parameter is for one of multiple packs in an HVESS. If there is only one pack in the system, the HVESS parameters should be used. If there are ...";
CM_ BO_ 2364697854 "High Voltage Energy Storage Pack 12 Data 9
Data set 9 (thermal) for High Voltage Energy Storage Pack 12.";
CM_ SG_ 2364697854 Data9CRC "The CRC is defined as follows:
• Length: 8 bits
• Polynomial: x^8+x^5+x^3+x^2+x+1
• Initial Value: FFh
• Input Data Reflection: Not reflected
• Result Data Reflection: Not reflected
• XOR value: FFh
SAE makes no claim of the functional safety ...";
CM_ SG_ 2364697854 Data9Counter "The message counter is used to detect situations where the transmitting ECU malfunction repeats the same frame all the time. The receiver of the information may use the counter parameter to detect this situation. The transmitting device will ...";
CM_ SG_ 2364697854 Data9EmbeddedIntegritySupport "Indicates SPN 23009 (HVESP12 Data 9 CRC) and SPN 23008 (HVESP12 Data 9 Counter) are supported by the sender.
00b = Embedded CRC and Counter are supported by the sender
01b = Protection is supported using J1939-76 SHM
10b = Reserved
11b = CRC and ...";
CM_ SG_ 2364697854 HVESS12ThermalEventDetected "A sensor has detected the presence of a thermal event at or near High Voltage Energy Storage Pack instance.
00b = No Thermal Event Detected
01b = Thermal Event Detected
10b = Error
11b = Not available
This parameter is for one of multiple packs ...";
CM_ SG_ 2364697854 LowestCellTempCellNum "Identifies the location of SPN 15443 (HVESP12 Lowest Cell Temperature) within SPN 15526 (HVESP12 Lowest Cell Temperature Module Number).
This parameter is for one of multiple packs in an HVESS. If there is only one pack in the system, the HVESS ...";
CM_ SG_ 2364697854 LowestCellTempModuleNum "Identifies the location of the module containing SPN 15443 (HVESP12 Lowest Cell Temperature).
This parameter is for one of multiple packs in an HVESS. If there is only one pack in the system, the HVESS parameters should be used. If there are ...";
CM_ SG_ 2364697854 HighestCellTempCellNum "Identifies the location of SPN 15442 (HVESP12 Highest Cell Temperature) within SPN 15524 (HVESP12 Highest Cell Temperature Module Number).
This parameter is for one of multiple packs in an HVESS. If there is only one pack in the system, the HVESS ...";
CM_ SG_ 2364697854 HighestCellTempModuleNum "Identifies the location of the module containing SPN 15442 (HVESP12 Highest Cell Temperature).
This parameter is for one of multiple packs in an HVESS. If there is only one pack in the system, the HVESS parameters should be used. If there are ...";
CM_ BO_ 2364697598 "High Voltage Energy Storage Pack 12 Data 8
Data set 8 (electrical data) for High Voltage Energy Storage Pack 12.";
CM_ SG_ 2364697598 AvgCellV "The average cell voltage in this High Voltage Energy Storage Pack instance.
This parameter is for one of multiple packs in an HVESS.  If there is only one pack in the system, the HVESS parameters should be used. If there are multiple packs in the ...";
CM_ SG_ 2364697598 LowestCellVCellNum "Identifies the location of SPN 15440 (HVESP12 Lowest Cell Voltage) within SPN 15521 (HVESP12 Lowest Cell Voltage Module Number).
This parameter is for one of multiple packs in an HVESS. If there is only one pack in the system, the HVESS parameters ...";
CM_ SG_ 2364697598 LowestCellVModuleNum "Identifies the location of the module containing SPN 15440 (HVESP12 Lowest Cell Voltage).
This parameter is for one of multiple packs in an HVESS. If there is only one pack in the system, the HVESS parameters should be used. If there are multiple ...";
CM_ SG_ 2364697598 HighestCellVCellNum "Identifies the location of SPN 15439 (HVESP12 Highest Cell Voltage) within SPN 15519 (HVESP12 Highest Cell Voltage Module Number).
This parameter is for one of multiple packs in an HVESS. If there is only one pack in the system, the HVESS ...";
CM_ SG_ 2364697598 HighestCellVModuleNum "Identifies the location of the module containing SPN 15439 (HVESP12 Highest Cell Voltage).
This parameter is for one of multiple packs in an HVESS. If there is only one pack in the system, the HVESS parameters should be used. If there are multiple ...";
CM_ BO_ 2364697342 "High Voltage Energy Storage Pack 12 Thermal Management System Status 1
Collection of data the High Voltage Energy Storage Pack 12 Thermal Management System sends to the Hybrid Controller.";
CM_ SG_ 2364697342 TMSCoolantLvl "Indicates the coolant level in this HVES Thermal Management System (TMS).
This parameter is for one of multiple packs in an HVESS.  If there is only one pack in the system, the HVESS parameters should be used. If there are multiple packs in the ...";
CM_ SG_ 2364697342 TMSMode "Indicates the operating mode of the Thermal Management System.  The heat transfer medium may be (e.g. liquid or air).  The cooling system may be fans, liquid coolant, or a combination of mediums.  The system may include an air and/or liquid ...";
CM_ SG_ 2364697342 TMSHVILStatus "In multiple HVES configurations, this is the status of the High Voltage Interlock Loop from the viewpoint of this Thermal Management System.
00b = HVIL Closed
01b = HVIL Open
10b = Error
11b = Not Available
This parameter is for one of multiple ...";
CM_ SG_ 2364697342 TMSHtrStatus "The state of this High Voltage Energy Storage Pack heater
This parameter is for one of multiple packs in an HVESS.  If there is only one pack in the system, the HVESS parameters should be used. If there are multiple packs in the system, then both ...";
CM_ SG_ 2364697342 TMSRelHumidty "When this High Voltage Energy Storage Pack Thermal Management System is equipped with a relative humidity sensor, this is the  measured Relative Humidity.
This parameter is for one of multiple packs in an HVESS.  If there is only one pack in the ...";
CM_ SG_ 2364697342 TMSCompressorSpd "When this High Voltage Energy Storage Pack Thermal Management System is equipped with an active cooling system (e.g. air conditioner), this is the Compressor Speed.
This parameter is for one of multiple packs in an HVESS.  If there is only one pack ...";
CM_ SG_ 2364697342 TMSHVInputPwr "This is the high-voltage power consumed by this HVES Thermal Management System (TMS).
This parameter is for one of multiple packs in an HVESS.  If there is only one pack in the system, the HVESS parameters should be used. If there are multiple ...";
CM_ SG_ 2364697342 TMSSLIInputPwr "This is the low-voltage power consumed by this HVES Thermal Management System (TMS).
This parameter is for one of multiple packs in an HVESS.  If there is only one pack in the system, the HVESS parameters should be used.  If there are multiple ...";
CM_ BO_ 2364697086 "High Voltage Energy Storage Pack 12 Module Status 1
Module Status message 1 for High Voltage Energy Storage Pack 12.";
CM_ SG_ 2364697086 Module32OperationalStatus "Operational Status of Module 32 in this High Voltage Energy Storage Pack Instance.  Not Operational is used when the module is initializing or not able to function (e.g. internal module level monitors have failed).  Operational indicates that the ...";
CM_ SG_ 2364697086 Module31OperationalStatus "Operational Status of Module 31 in this High Voltage Energy Storage Pack Instance.  Not Operational is used when the module is initializing or not able to function (e.g. internal module level monitors have failed).  Operational indicates that the ...";
CM_ SG_ 2364697086 Module30OperationalStatus "Operational Status of Module 30 in this High Voltage Energy Storage Pack Instance.  Not Operational is used when the module is initializing or not able to function (e.g. internal module level monitors have failed).  Operational indicates that the ...";
CM_ SG_ 2364697086 Module29OperationalStatus "Operational Status of Module 29 in this High Voltage Energy Storage Pack Instance.  Not Operational is used when the module is initializing or not able to function (e.g. internal module level monitors have failed).  Operational indicates that the ...";
CM_ SG_ 2364697086 Module28OperationalStatus "Operational Status of Module 28 in this High Voltage Energy Storage Pack Instance.  Not Operational is used when the module is initializing or not able to function (e.g. internal module level monitors have failed).  Operational indicates that the ...";
CM_ SG_ 2364697086 Module27OperationalStatus "Operational Status of Module 27 in this High Voltage Energy Storage Pack Instance.  Not Operational is used when the module is initializing or not able to function (e.g. internal module level monitors have failed).  Operational indicates that the ...";
CM_ SG_ 2364697086 Module26OperationalStatus "Operational Status of Module 26 in this High Voltage Energy Storage Pack Instance.  Not Operational is used when the module is initializing or not able to function (e.g. internal module level monitors have failed).  Operational indicates that the ...";
CM_ SG_ 2364697086 Module25OperationalStatus "Operational Status of Module 25 in this High Voltage Energy Storage Pack Instance.  Not Operational is used when the module is initializing or not able to function (e.g. internal module level monitors have failed).  Operational indicates that the ...";
CM_ SG_ 2364697086 Module24OperationalStatus "Operational Status of Module 24 in this High Voltage Energy Storage Pack Instance.  Not Operational is used when the module is initializing or not able to function (e.g. internal module level monitors have failed).  Operational indicates that the ...";
CM_ SG_ 2364697086 Module23OperationalStatus "Operational Status of Module 23 in this High Voltage Energy Storage Pack Instance.  Not Operational is used when the module is initializing or not able to function (e.g. internal module level monitors have failed).  Operational indicates that the ...";
CM_ SG_ 2364697086 Module22OperationalStatus "Operational Status of Module 22 in this High Voltage Energy Storage Pack Instance.  Not Operational is used when the module is initializing or not able to function (e.g. internal module level monitors have failed).  Operational indicates that the ...";
CM_ SG_ 2364697086 Module21OperationalStatus "Operational Status of Module 21 in this High Voltage Energy Storage Pack Instance.  Not Operational is used when the module is initializing or not able to function (e.g. internal module level monitors have failed).  Operational indicates that the ...";
CM_ SG_ 2364697086 Module20OperationalStatus "Operational Status of Module 20 in this High Voltage Energy Storage Pack Instance.  Not Operational is used when the module is initializing or not able to function (e.g. internal module level monitors have failed).  Operational indicates that the ...";
CM_ SG_ 2364697086 Module19OperationalStatus "Operational Status of Module 19 in this High Voltage Energy Storage Pack Instance.  Not Operational is used when the module is initializing or not able to function (e.g. internal module level monitors have failed).  Operational indicates that the ...";
CM_ SG_ 2364697086 Module18OperationalStatus "Operational Status of Module 18 in this High Voltage Energy Storage Pack Instance.  Not Operational is used when the module is initializing or not able to function (e.g. internal module level monitors have failed).  Operational indicates that the ...";
CM_ SG_ 2364697086 Module17OperationalStatus "Operational Status of Module 17 in this High Voltage Energy Storage Pack Instance.  Not Operational is used when the module is initializing or not able to function (e.g. internal module level monitors have failed).  Operational indicates that the ...";
CM_ SG_ 2364697086 Module16OperationalStatus "Operational Status of Module 16 in this High Voltage Energy Storage Pack Instance.  Not Operational is used when the module is initializing or not able to function (e.g. internal module level monitors have failed).  Operational indicates that the ...";
CM_ SG_ 2364697086 Module15OperationalStatus "Operational Status of Module 15 in this High Voltage Energy Storage Pack Instance.  Not Operational is used when the module is initializing or not able to function (e.g. internal module level monitors have failed).  Operational indicates that the ...";
CM_ SG_ 2364697086 Module14OperationalStatus "Operational Status of Module 14 in this High Voltage Energy Storage Pack Instance.  Not Operational is used when the module is initializing or not able to function (e.g. internal module level monitors have failed).  Operational indicates that the ...";
CM_ SG_ 2364697086 Module13OperationalStatus "Operational Status of Module 13 in this High Voltage Energy Storage Pack Instance.  Not Operational is used when the module is initializing or not able to function (e.g. internal module level monitors have failed).  Operational indicates that the ...";
CM_ SG_ 2364697086 Module12OperationalStatus "Operational Status of Module 12 in this High Voltage Energy Storage Pack Instance.  Not Operational is used when the module is initializing or not able to function (e.g. internal module level monitors have failed).  Operational indicates that the ...";
CM_ SG_ 2364697086 Module11OperationalStatus "Operational Status of Module 11 in this High Voltage Energy Storage Pack Instance.  Not Operational is used when the module is initializing or not able to function (e.g. internal module level monitors have failed).  Operational indicates that the ...";
CM_ SG_ 2364697086 Module10OperationalStatus "Operational Status of Module 10 in this High Voltage Energy Storage Pack Instance.  Not Operational is used when the module is initializing or not able to function (e.g. internal module level monitors have failed).  Operational indicates that the ...";
CM_ SG_ 2364697086 Module9OperationalStatus "Operational Status of Module 9 in this High Voltage Energy Storage Pack Instance.  Not Operational is used when the module is initializing or not able to function (e.g. internal module level monitors have failed).  Operational indicates that the ...";
CM_ SG_ 2364697086 Module8OperationalStatus "Operational Status of Module 8 in this High Voltage Energy Storage Pack Instance.  Not Operational is used when the module is initializing or not able to function (e.g. internal module level monitors have failed).  Operational indicates that the ...";
CM_ SG_ 2364697086 Module7OperationalStatus "Operational Status of Module 7 in this High Voltage Energy Storage Pack Instance.  Not Operational is used when the module is initializing or not able to function (e.g. internal module level monitors have failed).  Operational indicates that the ...";
CM_ SG_ 2364697086 Module6OperationalStatus "Operational Status of Module 6 in this High Voltage Energy Storage Pack Instance.  Not Operational is used when the module is initializing or not able to function (e.g. internal module level monitors have failed).  Operational indicates that the ...";
CM_ SG_ 2364697086 Module5OperationalStatus "Operational Status of Module 5 in this High Voltage Energy Storage Pack Instance.  Not Operational is used when the module is initializing or not able to function (e.g. internal module level monitors have failed).  Operational indicates that the ...";
CM_ SG_ 2364697086 Module4OperationalStatus "Operational Status of Module 4 in this High Voltage Energy Storage Pack Instance.  Not Operational is used when the module is initializing or not able to function (e.g. internal module level monitors have failed).  Operational indicates that the ...";
CM_ SG_ 2364697086 Module3OperationalStatus "Operational Status of Module 3 in this High Voltage Energy Storage Pack Instance.  Not Operational is used when the module is initializing or not able to function (e.g. internal module level monitors have failed).  Operational indicates that the ...";
CM_ SG_ 2364697086 Module2OperationalStatus "Operational Status of Module 2 in this High Voltage Energy Storage Pack Instance.  Not Operational is used when the module is initializing or not able to function (e.g. internal module level monitors have failed).  Operational indicates that the ...";
CM_ SG_ 2364697086 Module1OperationalStatus "Operational Status of Module 1 in this High Voltage Energy Storage Pack Instance.  Not Operational is used when the module is initializing or not able to function (e.g. internal module level monitors have failed).  Operational indicates that the ...";
CM_ BO_ 2364696830 "High Voltage Energy Storage Pack 12 Data 7
Data set 7 (electrical) for High Voltage Energy Storage Pack 12.";
CM_ SG_ 2364696830 MaxChargeVLmt "The maximum voltage level not to be exceeded while charging this High Voltage Energy Storage Pack instance. If this parameter is not supported, the maximum charge voltage should be limited to SPN 15545 (HVESP12 Recommended Maximum Operating ...";
CM_ SG_ 2364696830 ChargeEnergyCapacity "The amount of unused electrical energy storage available to be filled by charging this High Voltage Energy Storage Pack instance, i.e. “how much empty space is remaining in the tank”. See SPN 15447 (HVESP12 Charge Capacity) for Ampere-hours (Ah).
 ...";
CM_ SG_ 2364696830 DisEnergyCapacity "The amount of stored electrical energy in this High Voltage Energy Storage Pack instance that is available for use by the hybrid system, i.e. “how full is the tank”. See SPN 15446 (HVESP12 Discharge Capacity) for Ampere-hours (Ah).
This parameter ...";
CM_ BO_ 2364696574 "High Voltage Energy Storage Pack 12 Status 1
Status data set 1 for High Voltage Energy Storage Pack 12.";
CM_ SG_ 2364696574 Status1CRC "The CRC is defined as follows:
• Length: 8 bits
• Polynomial: x^8+x^5+x^3+x^2+x+1
• Initial Value: FFh
• Input Data Reflection: Not reflected
• Result Data Reflection: Not reflected
• XOR value: FFh
SAE makes no claim of the functional safety ...";
CM_ SG_ 2364696574 Status1Counter "The message counter is used to detect situations where the transmitting ECU malfunction repeats the same frame all the time. The receiver of the information may use the counter parameter to detect this situation. The transmitting device will ...";
CM_ SG_ 2364696574 OperationalStatus "Provides feedback on where this High Voltage Energy Storage Pack instance is in its operating spectrum, and includes feedback in response to the Operation Consent [i.e. SPN 15417 (HVESP12 Operation Consent)] and Power Down Command [i.e. SPN 15412 ...";
CM_ SG_ 2364696574 HVBusConnectionStatus "This parameter provides high level feedback on this High Voltage Energy Storage Pack instance high voltage bus connection. For specific contactor information, see SPN 15459 (HVESP12 High-Voltage Bus (Positive) Contactor State), SPN 15460 (HVESP12 ...";
CM_ SG_ 2364696574 InternalChargerStatus "Indicates that the charger in this HVES instance is on.  External chargers may use the External Energy Source Connection Status (SPN 7898) and related SPs.
This parameter is for one of multiple packs in an HVESS. If there is only one pack in the ...";
CM_ SG_ 2364696574 CellBalancingActive "Indicates whether or not the cells in this High Voltage Energy Storage Pack instance are currently being balanced.
This parameter is for one of multiple packs in an HVESS.  If there is only one pack in the system, the HVESS parameters should be ...";
CM_ SG_ 2364696574 CellBalanceStatus "Indicates whether or not the cells in this High Voltage Energy Storage Pack instance are balanced.
This parameter is for one of multiple packs in an HVESS.  If there is only one pack in the system, the HVESS parameters should be used. If there are ...";
CM_ SG_ 2364696574 StOfChargeStatus "Status of this High Voltage Energy Storage Pack instance State of Charge (SOC).  Note:  A given HVES controller may not support all of the states.
This parameter is for one of multiple packs in an HVESS.  If there is only one pack in the system, ...";
CM_ SG_ 2364696574 InertiaSwStatus "Switch indicating that an impact has been sensed by this High Voltage Energy Storage Pack instance. The impact indication may require action by another controller, or by this HVES instance itself.  For example, a controller may elect to take this ...";
CM_ SG_ 2364696574 HVILStatus "Status of the High Voltage Interlock Loop from the viewpoint of this High Voltage Energy Storage Pack instance.
This parameter is for one of multiple packs in an HVESS. If there is only one pack in the system, the HVESS parameters should be used ...";
CM_ SG_ 2364696574 HVBusPassiveIsolTestStatus "Status of the high-voltage bus electrical passive isolation test as performed by this High Voltage Energy Storage Pack instance.
This parameter is for one of multiple packs in an HVESS. If there is only one pack in the system, the HVESS parameters ...";
CM_ SG_ 2364696574 HVBusActiveIsolTestStatus "Status of the high-voltage bus electrical active isolation test as performed by this High Voltage Energy Storage Pack instance.
This parameter is for one of multiple packs in an HVESS. If there is only one pack in the system, the HVESS parameters ...";
CM_ SG_ 2364696574 CenterOfPackContactorSt "Position of the center high-voltage contactor. When this contactor is closed, the positive half of this High Voltage Energy Storage Pack instance is connected to the negative half. If a system controls the positive, negative, and center contactors ...";
CM_ SG_ 2364696574 HVBusPreChargeRelaySt "Position of the high-voltage bus contactor pre-charge relay.  When this relay is closed, this High Voltage Energy Storage Pack instance is bringing the high-voltage bus up to its operating level.
This parameter is for one of multiple packs in an ...";
CM_ SG_ 2364696574 HVBusDisconnectForewarning "Indicates that this High Voltage Energy Storage Pack instance is about to disconnect from the high voltage bus due to unacceptable conditions.
This parameter is for one of multiple packs in an HVESS. If there is only one pack in the system, the ...";
CM_ SG_ 2364696574 HVBusContactorSt15460 "Position of this High Voltage Energy Storage Pack instance negative side bus contactor. When this contactor is closed, the negative side of this HVES instance is connected to the negative side of the high-voltage bus. If a system controls the ...";
CM_ SG_ 2364696574 HVBusContactorSt "Position of this High Voltage Energy Storage Pack instance positive side bus contactor.  When this contactor is closed, the positive side of this HVES instance is connected to the positive side of the high-voltage bus.  In systems where all ...";
CM_ BO_ 2364696318 "High Voltage Energy Storage Pack 12 Data 6
Data set 6 (external or interface data) for High Voltage Energy Storage Pack 12.";
CM_ SG_ 2364696318 Temp "The temperature of this High Voltage Energy Storage Pack instance. The value may be determined from a unique sensor specifically for this purpose, or by aggregating various temperature sensor readings within the pack.
This parameter is for one of ...";
CM_ SG_ 2364696318 ETemp "The temperature of the electronics or control modules in this High Voltage Energy Storage Pack instance.  If there are multiple temperature sensors then this parameter would be set to the maximum sensor reading.
This parameter is for one of ...";
CM_ SG_ 2364696318 OutCoolantTemp "The temperature of liquid coolant as it exits this High Voltage Energy Storage Pack instance.
This parameter is for one of multiple packs in an HVESS.  If there is only one pack in the system, the HVESS parameters should be used. If there are ...";
CM_ SG_ 2364696318 InCoolantTemp "The temperature of liquid coolant as it enters this High Voltage Energy Storage Pack instance.
This parameter is for one of multiple packs in an HVESS.  If there is only one pack in the system, the HVESS parameters should be used. If there are ...";
CM_ SG_ 2364696318 IgntV "The voltage level at the ignition input of this High Voltage Energy Storage Pack controller.
This parameter is for one of multiple packs in an HVESS.  If there is only one pack in the system, the HVESS parameters should be used.  If there are ...";
CM_ SG_ 2364696318 BusV "The voltage level of the high voltage bus, as measured by this High Voltage Energy Storage Pack instance on the bus side (not the battery side) of its contactors.
This parameter is for one of multiple packs in an HVESS.  If there is only one pack ...";
CM_ BO_ 2364696062 "High Voltage Energy Storage Pack 12 Data 5
Data set 5 (electrical data) for High Voltage Energy Storage Pack 12.";
CM_ SG_ 2364696062 HighestCellStOfCharge "Indicates the state of charge of the highest-charged cell in this High Voltage Energy Storage Pack instance. 0% means no charge remaining, 100% means the cell is fully charged. If a single state of charge value covers more than one cell, the value ...";
CM_ SG_ 2364696062 LowestCellStOfCharge "Indicates the state of charge of the lowest-charged cell in this High Voltage Energy Storage Pack instance. 0% means no charge remaining, 100% means the cell is fully charged. If a single state of charge value covers more than one cell, the value in ...";
CM_ SG_ 2364696062 ChargeCurLmt "The maximum instantaneous current flow limit into this High Voltage Energy Storage Pack instance. This parameter is defined from the high voltage energy storage pack's point of view and should reflect the instantaneous capability of the pack.  The ...";
CM_ SG_ 2364696062 DisCurLmt "The maximum instantaneous current flow limit out of this High Voltage Energy Storage Pack instance. This parameter is defined from the high voltage energy storage pack's point of view and should reflect the instantaneous capability of the pack.  The ...";
CM_ BO_ 2364695806 "High Voltage Energy Storage Pack 12 Data 4
Data set 4 (electrical data) for High Voltage Energy Storage Pack 12.";
CM_ SG_ 2364695806 CellBalancingCount "The number of cells that are currently being balanced in this High Voltage Energy Storage Pack instance.
This parameter is for one of multiple packs in an HVESS.  If there is only one pack in the system, the HVESS parameters should be used.  If ...";
CM_ SG_ 2364695806 ChargeCapacity "The amount of unused electrical charge storage in this High Voltage Energy Storage Pack instance that is available to be filled by charging, i.e. “how much empty space is remaining in the tank”. See SPN 15477 (HVESP12 Charge Energy Capacity) for ...";
CM_ SG_ 2364695806 DisCapacity "The amount of stored electrical charge in this High Voltage Energy Storage Pack instance that is available for use by the hybrid system, i.e. “how full is the tank”. See SPN 15476 (HVESP12 Discharge Energy Capacity) for kilowatt-hours (kWh).
This ...";
CM_ BO_ 2364695550 "High Voltage Energy Storage Pack 12 Data 3
Data set 3 (thermal data) for High Voltage Energy Storage Pack 12.";
CM_ SG_ 2364695550 CellTempDiffStatus "Indicates whether or not the differential between the highest and lowest cell temperatures are within acceptable limits per this High Voltage Energy Storage Pack instance. The actual temperature differential can be calculated by subtracting SPN ...";
CM_ SG_ 2364695550 AvgCellTemp "The average temperature level of all cells in this High Voltage Energy Storage Pack instance.
This parameter is for one of multiple packs in an HVESS.  If there is only one pack in the system, the HVESS parameters should be used.  If there are ...";
CM_ SG_ 2364695550 LowestCellTemp "The lowest temperature level reported by any cell in this High Voltage Energy Storage Pack instance. If a single temperature sensor covers more than one cell, the value in this parameter is for the smallest group of cells measured. See SPN 15526 ...";
CM_ SG_ 2364695550 HighestCellTemp "The highest temperature level reported by any cell in this High Voltage Energy Storage Pack instance. If a single temperature sensor covers more than one cell, the value in this parameter is for the smallest group of cells measured. See SPN 15524 ...";
CM_ BO_ 2364695294 "High Voltage Energy Storage Pack 12 Data 2
Data set 2 (electrical data) for High Voltage Energy Storage Pack 12.";
CM_ SG_ 2364695294 CellVDiffStatus "Indicates whether or not the differential between the highest and lowest cell voltages are within acceptable limits, according to this High Voltage Energy Storage Pack instance. The actual voltage differential can be calculated by subtracting SPN ...";
CM_ SG_ 2364695294 LowestCellV "The lowest voltage level reported by any cell in this High Voltage Energy Storage Pack instance. If a single voltage sensor covers more than one cell, the value in this parameter is for the smallest group of cells measured. See SPN 15521 (HVESP12 ...";
CM_ SG_ 2364695294 HighestCellV "The highest voltage level reported by any cell in this High Voltage Energy Storage Pack instance. If a single voltage sensor covers more than one cell, the value in this parameter is for the smallest group of cells measured. See SPN 15519 (HVESP12 ...";
CM_ SG_ 2364695294 FastUpdateStOfCharge "Indicates this High Voltage Energy Storage Pack instance state of charge. 0% means no charge remaining, 100% means the system is fully charged in terms of physical limits of this energy storage pack instance. Acceptable state of charge upper and ...";
CM_ BO_ 2364695038 "High Voltage Energy Storage Pack 12 Data 1
Data set 1 (electrical data) for High Voltage Energy Storage Pack 12.";
CM_ SG_ 2364695038 Cur "The current in or out of this High Voltage Energy Storage Pack instance. This parameter should be synchronized with SPN 15436 (HVESP12 Voltage Level) such that a realized power value can be calculated. This parameter is defined from the high voltage ...";
CM_ SG_ 2364695038 Lvl "The voltage level of this High Voltage Energy Storage Pack instance. This parameter should be synchronized with SPN 15437 (HVESP12 Current) such that a realized power value can be calculated. If the HVES component physically contains the contactors ...";
CM_ SG_ 2364695038 AvailableChargePwr "The rate at which this High Voltage Energy Storage Pack instance can currently receive energy from a regenerative or recharging system.
This parameter is for one of multiple packs in an HVESS.  If there is only one pack in the system, the HVESS ...";
CM_ SG_ 2364695038 AvailableDisPwr "The rate at which this High Voltage Energy Storage Pack instance can currently provide energy for propulsion or other uses.
This parameter is for one of multiple packs in an HVESS.  If there is only one pack in the system, the HVESS parameters ...";
CM_ BO_ 2364694782 "High Voltage Energy Storage Pack 12 Status 2
Status data set 2 for High Voltage Energy Storage Pack 12.";
CM_ SG_ 2364694782 ChargePLDueToAnUndefinedCause "Indicates whether or not charge power of this HVES instance is being limited due to an undefined cause.
This parameter is for one of multiple packs in an HVESS.  If there is only one pack in the system, the HVESS parameters should be used. If there ...";
CM_ SG_ 2364694782 ChargePLDueToBatCur "Indicates whether or not charge power of this HVES instance is being limited due to battery current.
This parameter is for one of multiple packs in an HVESS.  If there is only one pack in the system, the HVESS parameters should be used. If there ...";
CM_ SG_ 2364694782 ChargePLDueToBatOrCellV "Indicates whether or not charge power of this HVES instance is being limited due to a battery or cell voltage level.
This parameter is for one of multiple packs in an HVESS.  If there is only one pack in the system, the HVESS parameters should be ...";
CM_ SG_ 2364694782 ChargePLDueToBatDiagCondition "Indicates whether or not charge power of this HVES instance is being limited due to a battery diagnostic condition.
This parameter is for one of multiple packs in an HVESS.  If there is only one pack in the system, the HVESS parameters should be ...";
CM_ SG_ 2364694782 ChargePLDueToBatTemp "Indicates whether or not charge power of this HVES instance is being limited due to battery temperature.
This parameter is for one of multiple packs in an HVESS.  If there is only one pack in the system, the HVESS parameters should be used. If ...";
CM_ SG_ 2364694782 ChargePLDueToStOfCharge "Indicates whether or not charge power of this HVES instance is being limited due to state of charge.
This parameter is for one of multiple packs in an HVESS.  If there is only one pack in the system, the HVESS parameters should be used. If there ...";
CM_ SG_ 2364694782 DisPLDueToAnUndefinedCause "Indicates whether or not discharge power of this HVES instance is being limited due to an undefined cause.
This parameter is for one of multiple packs in an HVESS.  If there is only one pack in the system, the HVESS parameters should be used. If ...";
CM_ SG_ 2364694782 DisPLDueToBatCur "Indicates whether or not discharge power of this HVES instance is being limited due to battery current.
This parameter is for one of multiple packs in an HVESS.  If there is only one pack in the system, the HVESS parameters should be used. If there ...";
CM_ SG_ 2364694782 DisPLDueToBatOrCellV "Indicates whether or not discharge power of this HVES instance is being limited due to a battery or cell voltage level.
This parameter is for one of multiple packs in an HVESS.  If there is only one pack in the system, the HVESS parameters should ...";
CM_ SG_ 2364694782 DisPLDueToBatDiagCondition "Indicates whether or not discharge power of this HVES instance is being limited due to a battery diagnostic condition.
This parameter is for one of multiple packs in an HVESS.  If there is only one pack in the system, the HVESS parameters should be ...";
CM_ SG_ 2364694782 DisPLDueToBatTemp "Indicates whether or not discharge power of this HVES instance is being limited due to battery temperature.
This parameter is for one of multiple packs in an HVESS.  If there is only one pack in the system, the HVESS parameters should be used. If ...";
CM_ SG_ 2364694782 DisPLDueToStOfCharge "Indicates whether or not discharge power of this HVES instance is being limited due to state of charge.
This parameter is for one of multiple packs in an HVESS.  If there is only one pack in the system, the HVESS parameters should be used. If there ...";
CM_ BO_ 2364694526 "High Voltage Energy Storage Pack 11 Data 11
Data set 11 (electrical data) for High Voltage Energy Storage Pack 11.";
CM_ SG_ 2364694526 ActualChargeRate "This signal represents the actual present charge rate of this High Voltage Energy Storage Pack instance.
This parameter is for one of multiple packs in an HVESS. If there is only one pack in the system, the HVESS parameters should be used. If there ...";
CM_ SG_ 2364694526 LvlNegToChassisGroundV "Voltage difference between the most negative terminal of the HVES battery and chassis measured at the battery side of any HVES contained output contactor.  This voltage may be used for system level monitoring of battery shorts to chassis within the ...";
CM_ SG_ 2364694526 BusVNegToChassisGroundV "Voltage difference between the most negative terminal of the HVES battery and chassis measured on the hybrid system bus side (not the battery side) of any HVES contained output contactor.  This voltage may be used for system level monitoring of ...";
CM_ BO_ 2364694270 "High Voltage Energy Storage Pack 11 Data 10
Data set 10 (electrical) for High Voltage Energy Storage Pack 11.";
CM_ SG_ 2364694270 HVBusPassiveIsolTestResults "The isolation resistance expressed in Ohms per Volt that resulted from the High-Voltage Bus Passive Isolation Test.
See SPN 15323 (HVESP11 High-Voltage Bus Passive Isolation Test Status) for test status and SPN 15272 (HVESP11 High-Voltage Bus ...";
CM_ SG_ 2364694270 HVBusActiveIsolTestResults "The isolation resistance expressed in Ohms per Volt that resulted from the High-Voltage Bus Active Isolation Test.
See SPN 15322 (HVESP11 High-Voltage Bus Active Isolation Test Status) for test status and SPN 15271 (HVESP11 High-Voltage Bus Active ...";
CM_ SG_ 2364694270 LowestCellStOfChargeCellNum "Identifies the location of SPN 15309 (HVESP11 Lowest Cell State of Charge) within SPN 15388 (HVESP11 Lowest Cell State of Charge Module Number).
This parameter is for one of multiple packs in an HVESS. If there is only one pack in the system, the ...";
CM_ SG_ 2364694270 LowestCellStOfChargeModuleNum "Identifies the location of the module containing SPN 15309 (HVESP11 Lowest Cell State of Charge).
This parameter is for one of multiple packs in an HVESS. If there is only one pack in the system, the HVESS parameters should be used. If there are ...";
CM_ SG_ 2364694270 HighestCellStOfChargeCellNum "Identifies the location of SPN 15310 (HVESP11 Highest Cell State of Charge) within SPN 15386 (HVESP11 Highest Cell State of Charge Module Number).
This parameter is for one of multiple packs in an HVESS. If there is only one pack in the system, the ...";
CM_ SG_ 2364694270 HighestCellStOfChargeModuleNum "Identifies the location of the module containing SPN 15310 (HVESP11 Highest Cell State of Charge).
This parameter is for one of multiple packs in an HVESS. If there is only one pack in the system, the HVESS parameters should be used. If there are ...";
CM_ BO_ 2364694014 "High Voltage Energy Storage Pack 11 Data 9
Data set 9 (thermal) for High Voltage Energy Storage Pack 11.";
CM_ SG_ 2364694014 Data9CRC "The CRC is defined as follows:
• Length: 8 bits
• Polynomial: x^8+x^5+x^3+x^2+x+1
• Initial Value: FFh
• Input Data Reflection: Not reflected
• Result Data Reflection: Not reflected
• XOR value: FFh
SAE makes no claim of the functional safety ...";
CM_ SG_ 2364694014 Data9Counter "The message counter is used to detect situations where the transmitting ECU malfunction repeats the same frame all the time. The receiver of the information may use the counter parameter to detect this situation. The transmitting device will ...";
CM_ SG_ 2364694014 Data9EmbeddedIntegritySupport "Indicates SPN 23006 (HVESP11 Data 9 CRC) and SPN 23005 (HVESP11 Data 9 Counter) are supported by the sender.
00b = Embedded CRC and Counter are supported by the sender
01b = Protection is supported using J1939-76 SHM
10b = Reserved
11b = CRC and ...";
CM_ SG_ 2364694014 HVESS11ThermalEventDetected "A sensor has detected the presence of a thermal event at or near High Voltage Energy Storage Pack instance.
00b = No Thermal Event Detected
01b = Thermal Event Detected
10b = Error
11b = Not available
This parameter is for one of multiple packs ...";
CM_ SG_ 2364694014 LowestCellTempCellNum "Identifies the location of SPN 15301 (HVESP11 Lowest Cell Temperature) within SPN 15384 (HVESP11 Lowest Cell Temperature Module Number).
This parameter is for one of multiple packs in an HVESS. If there is only one pack in the system, the HVESS ...";
CM_ SG_ 2364694014 LowestCellTempModuleNum "Identifies the location of the module containing SPN 15301 (HVESP11 Lowest Cell Temperature).
This parameter is for one of multiple packs in an HVESS. If there is only one pack in the system, the HVESS parameters should be used. If there are ...";
CM_ SG_ 2364694014 HighestCellTempCellNum "Identifies the location of SPN 15300 (HVESP11 Highest Cell Temperature) within SPN 15382 (HVESP11 Highest Cell Temperature Module Number).
This parameter is for one of multiple packs in an HVESS. If there is only one pack in the system, the HVESS ...";
CM_ SG_ 2364694014 HighestCellTempModuleNum "Identifies the location of the module containing SPN 15300 (HVESP11 Highest Cell Temperature).
This parameter is for one of multiple packs in an HVESS. If there is only one pack in the system, the HVESS parameters should be used. If there are ...";
CM_ BO_ 2364693758 "High Voltage Energy Storage Pack 11 Data 8
Data set 8 (electrical data) for High Voltage Energy Storage Pack 11.";
CM_ SG_ 2364693758 AvgCellV "The average cell voltage in this High Voltage Energy Storage Pack instance.
This parameter is for one of multiple packs in an HVESS.  If there is only one pack in the system, the HVESS parameters should be used. If there are multiple packs in the ...";
CM_ SG_ 2364693758 LowestCellVCellNum "Identifies the location of SPN 15298 (HVESP11 Lowest Cell Voltage) within SPN 15379 (HVESP11 Lowest Cell Voltage Module Number).
This parameter is for one of multiple packs in an HVESS. If there is only one pack in the system, the HVESS parameters ...";
CM_ SG_ 2364693758 LowestCellVModuleNum "Identifies the location of the module containing SPN 15298 (HVESP11 Lowest Cell Voltage).
This parameter is for one of multiple packs in an HVESS. If there is only one pack in the system, the HVESS parameters should be used. If there are multiple ...";
CM_ SG_ 2364693758 HighestCellVCellNum "Identifies the location of SPN 15297 (HVESP11 Highest Cell Voltage) within SPN 15377 (HVESP11 Highest Cell Voltage Module Number).
This parameter is for one of multiple packs in an HVESS. If there is only one pack in the system, the HVESS ...";
CM_ SG_ 2364693758 HighestCellVModuleNum "Identifies the location of the module containing SPN 15297 (HVESP11 Highest Cell Voltage).
This parameter is for one of multiple packs in an HVESS. If there is only one pack in the system, the HVESS parameters should be used. If there are multiple ...";
CM_ BO_ 2364693502 "High Voltage Energy Storage Pack 11 Thermal Management System Status 1
Collection of data the High Voltage Energy Storage Pack 11 Thermal Management System sends to the Hybrid Controller.";
CM_ SG_ 2364693502 TMSCoolantLvl "Indicates the coolant level in this HVES Thermal Management System (TMS).
This parameter is for one of multiple packs in an HVESS.  If there is only one pack in the system, the HVESS parameters should be used. If there are multiple packs in the ...";
CM_ SG_ 2364693502 TMSMode "Indicates the operating mode of the Thermal Management System.  The heat transfer medium may be (e.g. liquid or air).  The cooling system may be fans, liquid coolant, or a combination of mediums.  The system may include an air and/or liquid ...";
CM_ SG_ 2364693502 TMSHVILStatus "In multiple HVES configurations, this is the status of the High Voltage Interlock Loop from the viewpoint of this Thermal Management System.
00b = HVIL Closed
01b = HVIL Open
10b = Error
11b = Not Available
This parameter is for one of multiple ...";
CM_ SG_ 2364693502 TMSHtrStatus "The state of this High Voltage Energy Storage Pack heater
This parameter is for one of multiple packs in an HVESS.  If there is only one pack in the system, the HVESS parameters should be used. If there are multiple packs in the system, then both ...";
CM_ SG_ 2364693502 TMSRelHumidty "When this High Voltage Energy Storage Pack Thermal Management System is equipped with a relative humidity sensor, this is the  measured Relative Humidity.
This parameter is for one of multiple packs in an HVESS.  If there is only one pack in the ...";
CM_ SG_ 2364693502 TMSCompressorSpd "When this High Voltage Energy Storage Pack Thermal Management System is equipped with an active cooling system (e.g. air conditioner), this is the Compressor Speed.
This parameter is for one of multiple packs in an HVESS.  If there is only one pack ...";
CM_ SG_ 2364693502 TMSHVInputPwr "This is the high-voltage power consumed by this HVES Thermal Management System (TMS).
This parameter is for one of multiple packs in an HVESS.  If there is only one pack in the system, the HVESS parameters should be used. If there are multiple ...";
CM_ SG_ 2364693502 TMSSLIInputPwr "This is the low-voltage power consumed by this HVES Thermal Management System (TMS).
This parameter is for one of multiple packs in an HVESS.  If there is only one pack in the system, the HVESS parameters should be used.  If there are multiple ...";
CM_ BO_ 2364693246 "High Voltage Energy Storage Pack 11 Module Status 1
Module Status message 1 for High Voltage Energy Storage Pack 11.";
CM_ SG_ 2364693246 Module32OperationalStatus "Operational Status of Module 32 in this High Voltage Energy Storage Pack Instance.  Not Operational is used when the module is initializing or not able to function (e.g. internal module level monitors have failed).  Operational indicates that the ...";
CM_ SG_ 2364693246 Module31OperationalStatus "Operational Status of Module 31 in this High Voltage Energy Storage Pack Instance.  Not Operational is used when the module is initializing or not able to function (e.g. internal module level monitors have failed).  Operational indicates that the ...";
CM_ SG_ 2364693246 Module30OperationalStatus "Operational Status of Module 30 in this High Voltage Energy Storage Pack Instance.  Not Operational is used when the module is initializing or not able to function (e.g. internal module level monitors have failed).  Operational indicates that the ...";
CM_ SG_ 2364693246 Module29OperationalStatus "Operational Status of Module 29 in this High Voltage Energy Storage Pack Instance.  Not Operational is used when the module is initializing or not able to function (e.g. internal module level monitors have failed).  Operational indicates that the ...";
CM_ SG_ 2364693246 Module28OperationalStatus "Operational Status of Module 28 in this High Voltage Energy Storage Pack Instance.  Not Operational is used when the module is initializing or not able to function (e.g. internal module level monitors have failed).  Operational indicates that the ...";
CM_ SG_ 2364693246 Module27OperationalStatus "Operational Status of Module 27 in this High Voltage Energy Storage Pack Instance.  Not Operational is used when the module is initializing or not able to function (e.g. internal module level monitors have failed).  Operational indicates that the ...";
CM_ SG_ 2364693246 Module26OperationalStatus "Operational Status of Module 26 in this High Voltage Energy Storage Pack Instance.  Not Operational is used when the module is initializing or not able to function (e.g. internal module level monitors have failed).  Operational indicates that the ...";
CM_ SG_ 2364693246 Module25OperationalStatus "Operational Status of Module 25 in this High Voltage Energy Storage Pack Instance.  Not Operational is used when the module is initializing or not able to function (e.g. internal module level monitors have failed).  Operational indicates that the ...";
CM_ SG_ 2364693246 Module24OperationalStatus "Operational Status of Module 24 in this High Voltage Energy Storage Pack Instance.  Not Operational is used when the module is initializing or not able to function (e.g. internal module level monitors have failed).  Operational indicates that the ...";
CM_ SG_ 2364693246 Module23OperationalStatus "Operational Status of Module 23 in this High Voltage Energy Storage Pack Instance.  Not Operational is used when the module is initializing or not able to function (e.g. internal module level monitors have failed).  Operational indicates that the ...";
CM_ SG_ 2364693246 Module22OperationalStatus "Operational Status of Module 22 in this High Voltage Energy Storage Pack Instance.  Not Operational is used when the module is initializing or not able to function (e.g. internal module level monitors have failed).  Operational indicates that the ...";
CM_ SG_ 2364693246 Module21OperationalStatus "Operational Status of Module 21 in this High Voltage Energy Storage Pack Instance.  Not Operational is used when the module is initializing or not able to function (e.g. internal module level monitors have failed).  Operational indicates that the ...";
CM_ SG_ 2364693246 Module20OperationalStatus "Operational Status of Module 20 in this High Voltage Energy Storage Pack Instance.  Not Operational is used when the module is initializing or not able to function (e.g. internal module level monitors have failed).  Operational indicates that the ...";
CM_ SG_ 2364693246 Module19OperationalStatus "Operational Status of Module 19 in this High Voltage Energy Storage Pack Instance.  Not Operational is used when the module is initializing or not able to function (e.g. internal module level monitors have failed).  Operational indicates that the ...";
CM_ SG_ 2364693246 Module18OperationalStatus "Operational Status of Module 18 in this High Voltage Energy Storage Pack Instance.  Not Operational is used when the module is initializing or not able to function (e.g. internal module level monitors have failed).  Operational indicates that the ...";
CM_ SG_ 2364693246 Module17OperationalStatus "Operational Status of Module 17 in this High Voltage Energy Storage Pack Instance.  Not Operational is used when the module is initializing or not able to function (e.g. internal module level monitors have failed).  Operational indicates that the ...";
CM_ SG_ 2364693246 Module16OperationalStatus "Operational Status of Module 16 in this High Voltage Energy Storage Pack Instance.  Not Operational is used when the module is initializing or not able to function (e.g. internal module level monitors have failed).  Operational indicates that the ...";
CM_ SG_ 2364693246 Module15OperationalStatus "Operational Status of Module 15 in this High Voltage Energy Storage Pack Instance.  Not Operational is used when the module is initializing or not able to function (e.g. internal module level monitors have failed).  Operational indicates that the ...";
CM_ SG_ 2364693246 Module14OperationalStatus "Operational Status of Module 14 in this High Voltage Energy Storage Pack Instance.  Not Operational is used when the module is initializing or not able to function (e.g. internal module level monitors have failed).  Operational indicates that the ...";
CM_ SG_ 2364693246 Module13OperationalStatus "Operational Status of Module 13 in this High Voltage Energy Storage Pack Instance.  Not Operational is used when the module is initializing or not able to function (e.g. internal module level monitors have failed).  Operational indicates that the ...";
CM_ SG_ 2364693246 Module12OperationalStatus "Operational Status of Module 12 in this High Voltage Energy Storage Pack Instance.  Not Operational is used when the module is initializing or not able to function (e.g. internal module level monitors have failed).  Operational indicates that the ...";
CM_ SG_ 2364693246 Module11OperationalStatus "Operational Status of Module 11 in this High Voltage Energy Storage Pack Instance.  Not Operational is used when the module is initializing or not able to function (e.g. internal module level monitors have failed).  Operational indicates that the ...";
CM_ SG_ 2364693246 Module10OperationalStatus "Operational Status of Module 10 in this High Voltage Energy Storage Pack Instance.  Not Operational is used when the module is initializing or not able to function (e.g. internal module level monitors have failed).  Operational indicates that the ...";
CM_ SG_ 2364693246 Module9OperationalStatus "Operational Status of Module 9 in this High Voltage Energy Storage Pack Instance.  Not Operational is used when the module is initializing or not able to function (e.g. internal module level monitors have failed).  Operational indicates that the ...";
CM_ SG_ 2364693246 Module8OperationalStatus "Operational Status of Module 8 in this High Voltage Energy Storage Pack Instance.  Not Operational is used when the module is initializing or not able to function (e.g. internal module level monitors have failed).  Operational indicates that the ...";
CM_ SG_ 2364693246 Module7OperationalStatus "Operational Status of Module 7 in this High Voltage Energy Storage Pack Instance.  Not Operational is used when the module is initializing or not able to function (e.g. internal module level monitors have failed).  Operational indicates that the ...";
CM_ SG_ 2364693246 Module6OperationalStatus "Operational Status of Module 6 in this High Voltage Energy Storage Pack Instance.  Not Operational is used when the module is initializing or not able to function (e.g. internal module level monitors have failed).  Operational indicates that the ...";
CM_ SG_ 2364693246 Module5OperationalStatus "Operational Status of Module 5 in this High Voltage Energy Storage Pack Instance.  Not Operational is used when the module is initializing or not able to function (e.g. internal module level monitors have failed).  Operational indicates that the ...";
CM_ SG_ 2364693246 Module4OperationalStatus "Operational Status of Module 4 in this High Voltage Energy Storage Pack Instance.  Not Operational is used when the module is initializing or not able to function (e.g. internal module level monitors have failed).  Operational indicates that the ...";
CM_ SG_ 2364693246 Module3OperationalStatus "Operational Status of Module 3 in this High Voltage Energy Storage Pack Instance.  Not Operational is used when the module is initializing or not able to function (e.g. internal module level monitors have failed).  Operational indicates that the ...";
CM_ SG_ 2364693246 Module2OperationalStatus "Operational Status of Module 2 in this High Voltage Energy Storage Pack Instance.  Not Operational is used when the module is initializing or not able to function (e.g. internal module level monitors have failed).  Operational indicates that the ...";
CM_ SG_ 2364693246 Module1OperationalStatus "Operational Status of Module 1 in this High Voltage Energy Storage Pack Instance.  Not Operational is used when the module is initializing or not able to function (e.g. internal module level monitors have failed).  Operational indicates that the ...";
CM_ BO_ 2364692990 "High Voltage Energy Storage Pack 11 Data 7
Data set 7 (electrical) for High Voltage Energy Storage Pack 11.";
CM_ SG_ 2364692990 MaxChargeVLmt "The maximum voltage level not to be exceeded while charging this High Voltage Energy Storage Pack instance. If this parameter is not supported, the maximum charge voltage should be limited to SPN 15403 (HVESP11 Recommended Maximum Operating ...";
CM_ SG_ 2364692990 ChargeEnergyCapacity "The amount of unused electrical energy storage available to be filled by charging this High Voltage Energy Storage Pack instance, i.e. “how much empty space is remaining in the tank”. See SPN 15305 (HVESP11 Charge Capacity) for Ampere-hours (Ah).
 ...";
CM_ SG_ 2364692990 DisEnergyCapacity "The amount of stored electrical energy in this High Voltage Energy Storage Pack instance that is available for use by the hybrid system, i.e. “how full is the tank”. See SPN 15304 (HVESP11 Discharge Capacity) for Ampere-hours (Ah).
This parameter ...";
CM_ BO_ 2364692734 "High Voltage Energy Storage Pack 11 Status 1
Status data set 1 for High Voltage Energy Storage Pack 11.";
CM_ SG_ 2364692734 Status1CRC "The CRC is defined as follows:
• Length: 8 bits
• Polynomial: x^8+x^5+x^3+x^2+x+1
• Initial Value: FFh
• Input Data Reflection: Not reflected
• Result Data Reflection: Not reflected
• XOR value: FFh
SAE makes no claim of the functional safety ...";
CM_ SG_ 2364692734 Status1Counter "The message counter is used to detect situations where the transmitting ECU malfunction repeats the same frame all the time. The receiver of the information may use the counter parameter to detect this situation. The transmitting device will ...";
CM_ SG_ 2364692734 OperationalStatus "Provides feedback on where this High Voltage Energy Storage Pack instance is in its operating spectrum, and includes feedback in response to the Operation Consent [i.e. SPN 15275 (HVESP11 Operation Consent)] and Power Down Command [i.e. SPN 15270 ...";
CM_ SG_ 2364692734 HVBusConnectionStatus "This parameter provides high level feedback on this High Voltage Energy Storage Pack instance high voltage bus connection. For specific contactor information, see SPN 15317 (HVESP11 High-Voltage Bus (Positive) Contactor State), SPN 15318 (HVESP11 ...";
CM_ SG_ 2364692734 InternalChargerStatus "Indicates that the charger in this HVES instance is on.  External chargers may use the External Energy Source Connection Status (SPN 7898) and related SPs.
This parameter is for one of multiple packs in an HVESS. If there is only one pack in the ...";
CM_ SG_ 2364692734 CellBalancingActive "Indicates whether or not the cells in this High Voltage Energy Storage Pack instance are currently being balanced.
This parameter is for one of multiple packs in an HVESS.  If there is only one pack in the system, the HVESS parameters should be ...";
CM_ SG_ 2364692734 CellBalanceStatus "Indicates whether or not the cells in this High Voltage Energy Storage Pack instance are balanced.
This parameter is for one of multiple packs in an HVESS.  If there is only one pack in the system, the HVESS parameters should be used. If there are ...";
CM_ SG_ 2364692734 StOfChargeStatus "Status of this High Voltage Energy Storage Pack instance State of Charge (SOC).  Note:  A given HVES controller may not support all of the states.
This parameter is for one of multiple packs in an HVESS.  If there is only one pack in the system, ...";
CM_ SG_ 2364692734 InertiaSwStatus "Switch indicating that an impact has been sensed by this High Voltage Energy Storage Pack instance. The impact indication may require action by another controller, or by this HVES instance itself.  For example, a controller may elect to take this ...";
CM_ SG_ 2364692734 HVILStatus "Status of the High Voltage Interlock Loop from the viewpoint of this High Voltage Energy Storage Pack instance.
This parameter is for one of multiple packs in an HVESS. If there is only one pack in the system, the HVESS parameters should be used ...";
CM_ SG_ 2364692734 HVBusPassiveIsolTestStatus "Status of the high-voltage bus electrical passive isolation test as performed by this High Voltage Energy Storage Pack instance.
This parameter is for one of multiple packs in an HVESS. If there is only one pack in the system, the HVESS parameters ...";
CM_ SG_ 2364692734 HVBusActiveIsolTestStatus "Status of the high-voltage bus electrical active isolation test as performed by this High Voltage Energy Storage Pack instance.
This parameter is for one of multiple packs in an HVESS. If there is only one pack in the system, the HVESS parameters ...";
CM_ SG_ 2364692734 CenterOfPackContactorSt "Position of the center high-voltage contactor. When this contactor is closed, the positive half of this High Voltage Energy Storage Pack instance is connected to the negative half. If a system controls the positive, negative, and center contactors ...";
CM_ SG_ 2364692734 HVBusPreChargeRelaySt "Position of the high-voltage bus contactor pre-charge relay.  When this relay is closed, this High Voltage Energy Storage Pack instance is bringing the high-voltage bus up to its operating level.
This parameter is for one of multiple packs in an ...";
CM_ SG_ 2364692734 HVBusDisconnectForewarning "Indicates that this High Voltage Energy Storage Pack instance is about to disconnect from the high voltage bus due to unacceptable conditions.
This parameter is for one of multiple packs in an HVESS. If there is only one pack in the system, the ...";
CM_ SG_ 2364692734 HVBusContactorSt15318 "Position of this High Voltage Energy Storage Pack instance negative side bus contactor. When this contactor is closed, the negative side of this HVES instance is connected to the negative side of the high-voltage bus. If a system controls the ...";
CM_ SG_ 2364692734 HVBusContactorSt "Position of this High Voltage Energy Storage Pack instance positive side bus contactor.  When this contactor is closed, the positive side of this HVES instance is connected to the positive side of the high-voltage bus.  In systems where all ...";
CM_ BO_ 2364692478 "High Voltage Energy Storage Pack 11 Data 6
Data set 6 (external or interface data) for High Voltage Energy Storage Pack 11.";
CM_ SG_ 2364692478 Temp "The temperature of this High Voltage Energy Storage Pack instance. The value may be determined from a unique sensor specifically for this purpose, or by aggregating various temperature sensor readings within the pack.
This parameter is for one of ...";
CM_ SG_ 2364692478 ETemp "The temperature of the electronics or control modules in this High Voltage Energy Storage Pack instance.  If there are multiple temperature sensors then this parameter would be set to the maximum sensor reading.
This parameter is for one of ...";
CM_ SG_ 2364692478 OutCoolantTemp "The temperature of liquid coolant as it exits this High Voltage Energy Storage Pack instance.
This parameter is for one of multiple packs in an HVESS.  If there is only one pack in the system, the HVESS parameters should be used. If there are ...";
CM_ SG_ 2364692478 InCoolantTemp "The temperature of liquid coolant as it enters this High Voltage Energy Storage Pack instance.
This parameter is for one of multiple packs in an HVESS.  If there is only one pack in the system, the HVESS parameters should be used. If there are ...";
CM_ SG_ 2364692478 IgntV "The voltage level at the ignition input of this High Voltage Energy Storage Pack controller.
This parameter is for one of multiple packs in an HVESS.  If there is only one pack in the system, the HVESS parameters should be used.  If there are ...";
CM_ SG_ 2364692478 BusV "The voltage level of the high voltage bus, as measured by this High Voltage Energy Storage Pack instance on the bus side (not the battery side) of its contactors.
This parameter is for one of multiple packs in an HVESS.  If there is only one pack ...";
CM_ BO_ 2364692222 "High Voltage Energy Storage Pack 11 Data 5
Data set 5 (electrical data) for High Voltage Energy Storage Pack 11.";
CM_ SG_ 2364692222 HighestCellStOfCharge "Indicates the state of charge of the highest-charged cell in this High Voltage Energy Storage Pack instance. 0% means no charge remaining, 100% means the cell is fully charged. If a single state of charge value covers more than one cell, the value ...";
CM_ SG_ 2364692222 LowestCellStOfCharge "Indicates the state of charge of the lowest-charged cell in this High Voltage Energy Storage Pack instance. 0% means no charge remaining, 100% means the cell is fully charged. If a single state of charge value covers more than one cell, the value in ...";
CM_ SG_ 2364692222 ChargeCurLmt "The maximum instantaneous current flow limit into this High Voltage Energy Storage Pack instance. This parameter is defined from the high voltage energy storage pack's point of view and should reflect the instantaneous capability of the pack.  The ...";
CM_ SG_ 2364692222 DisCurLmt "The maximum instantaneous current flow limit out of this High Voltage Energy Storage Pack instance. This parameter is defined from the high voltage energy storage pack's point of view and should reflect the instantaneous capability of the pack.  The ...";
CM_ BO_ 2364691966 "High Voltage Energy Storage Pack 11 Data 4
Data set 4 (electrical data) for High Voltage Energy Storage Pack 11.";
CM_ SG_ 2364691966 CellBalancingCount "The number of cells that are currently being balanced in this High Voltage Energy Storage Pack instance.
This parameter is for one of multiple packs in an HVESS.  If there is only one pack in the system, the HVESS parameters should be used.  If ...";
CM_ SG_ 2364691966 ChargeCapacity "The amount of unused electrical charge storage in this High Voltage Energy Storage Pack instance that is available to be filled by charging, i.e. “how much empty space is remaining in the tank”. See SPN 15335 (HVESP11 Charge Energy Capacity) for ...";
CM_ SG_ 2364691966 DisCapacity "The amount of stored electrical charge in this High Voltage Energy Storage Pack instance that is available for use by the hybrid system, i.e. “how full is the tank”. See SPN 15334 (HVESP11 Discharge Energy Capacity) for kilowatt-hours (kWh).
This ...";
BA_DEF_ SG_  "GenSigInactiveValue" INT 0 0;
BA_DEF_ SG_  "SigType" ENUM  "Default","Range","RangeSigned","ASCII","Discrete","Control","ReferencePGN","DTC","StringDelimiter","StringLength","StringLengthControl","MessageCounter","MessageChecksum";
BA_DEF_ SG_  "GenSigStartValue" INT 0 2147483647;
BA_DEF_ SG_  "GenSigSendType" ENUM  "Cyclic","OnWrite","OnWriteWithRepetition","OnChange","OnChangeWithRepetition","IfActive","IfActiveWithRepetition","NoSigSendType";
BA_DEF_ SG_  "GenSigILSupport" ENUM  "No","Yes";
BA_DEF_ SG_  "SPN" INT 0 524287;
BA_DEF_ BO_  "J1939CPgSendTimeout" INT -1 3600000;
BA_DEF_ BO_  "J1939CPgTOS" INT 0 7;
BA_DEF_ BO_  "J1939PgAppearanceOnBus" ENUM  "Default","CAN_Extended","CANFD_Extended";
BA_DEF_ BO_  "FsJ1939UseCrcAndCounter" STRING ;
BA_DEF_ BO_  "TpJ1939VarDlc" ENUM  "No","Yes";
BA_DEF_ BO_  "GenMsgNrOfRepetition" INT 0 1000000;
BA_DEF_ BO_  "GenMsgCycleTimeFast" INT 0 3600000;
BA_DEF_ BO_  "GenMsgFastOnStart" INT 0 100000;
BA_DEF_ BO_  "GenMsgStartDelayTime" INT 0 100000;
BA_DEF_ BO_  "GenMsgILSupport" ENUM  "No","Yes";
BA_DEF_ BO_  "GenMsgDelayTime" INT 0 1000;
BA_DEF_ BO_  "GenMsgRequestable" INT 0 1;
BA_DEF_ BO_  "GenMsgSendType" ENUM  "cyclic","NotUsed","NotUsed","NotUsed","NotUsed","NotUsed","NotUsed","IfActive","noMsgSendType";
BA_DEF_ BO_  "VFrameFormat" ENUM  "StandardCAN","ExtendedCAN","reserved","J1939PG","reserved","reserved","reserved","reserved","reserved","reserved","reserved","reserved","reserved","reserved","StandardCAN_FD","ExtendedCAN_FD";
BA_DEF_ BO_  "SingleFrame" INT 0 1;
BA_DEF_ BO_  "GenMsgCycleTime" INT 0 3600000;
BA_DEF_ SG_  "SystemSignalLongSymbol" STRING ;
BA_DEF_DEF_  "GenSigInactiveValue" 0;
BA_DEF_DEF_  "SigType" "Default";
BA_DEF_DEF_  "GenSigStartValue" 0;
BA_DEF_DEF_  "GenSigSendType" "NoSigSendType";
BA_DEF_DEF_  "GenSigILSupport" "Yes";
BA_DEF_DEF_  "SPN" 0;
BA_DEF_DEF_  "J1939CPgSendTimeout" -1;
BA_DEF_DEF_  "J1939CPgTOS" 2;
BA_DEF_DEF_  "J1939PgAppearanceOnBus" "Default";
BA_DEF_DEF_  "FsJ1939UseCrcAndCounter" "";
BA_DEF_DEF_  "TpJ1939VarDlc" "No";
BA_DEF_DEF_  "GenMsgNrOfRepetition" 0;
BA_DEF_DEF_  "GenMsgCycleTimeFast" 0;
BA_DEF_DEF_  "GenMsgFastOnStart" 0;
BA_DEF_DEF_  "GenMsgStartDelayTime" 0;
BA_DEF_DEF_  "GenMsgILSupport" "Yes";
BA_DEF_DEF_  "GenMsgDelayTime" 0;
BA_DEF_DEF_  "GenMsgRequestable" 1;
BA_DEF_DEF_  "GenMsgSendType" "noMsgSendType";
BA_DEF_DEF_  "VFrameFormat" "J1939PG";
BA_DEF_DEF_  "SingleFrame" 1;
BA_DEF_DEF_  "GenMsgCycleTime" 0;
BA_DEF_DEF_  "SystemSignalLongSymbol" "";
BA_ "GenMsgSendType" BO_ 2364701950 0;
BA_ "GenMsgCycleTime" BO_ 2364701950 100;
BA_ "FsJ1939UseCrcAndCounter" BO_ 2364701694 "Aa";
BA_ "GenMsgSendType" BO_ 2364701694 0;
BA_ "GenMsgCycleTime" BO_ 2364701694 100;
BA_ "GenMsgSendType" BO_ 2364701438 0;
BA_ "GenMsgCycleTime" BO_ 2364701438 100;
BA_ "GenMsgSendType" BO_ 2364701182 0;
BA_ "GenMsgCycleTime" BO_ 2364701182 100;
BA_ "GenMsgSendType" BO_ 2364700926 0;
BA_ "GenMsgCycleTime" BO_ 2364700926 100;
BA_ "GenMsgSendType" BO_ 2364700670 0;
BA_ "GenMsgCycleTime" BO_ 2364700670 100;
BA_ "FsJ1939UseCrcAndCounter" BO_ 2364700414 "Aa";
BA_ "GenMsgDelayTime" BO_ 2364700414 20;
BA_ "GenMsgSendType" BO_ 2364700414 0;
BA_ "GenMsgCycleTime" BO_ 2364700414 100;
BA_ "GenMsgSendType" BO_ 2364700158 0;
BA_ "GenMsgCycleTime" BO_ 2364700158 100;
BA_ "GenMsgSendType" BO_ 2364699902 0;
BA_ "GenMsgCycleTime" BO_ 2364699902 20;
BA_ "GenMsgSendType" BO_ 2364699646 0;
BA_ "GenMsgCycleTime" BO_ 2364699646 100;
BA_ "GenMsgSendType" BO_ 2364699390 0;
BA_ "GenMsgCycleTime" BO_ 2364699390 20;
BA_ "GenMsgSendType" BO_ 2364699134 0;
BA_ "GenMsgCycleTime" BO_ 2364699134 20;
BA_ "GenMsgSendType" BO_ 2364698878 0;
BA_ "GenMsgCycleTime" BO_ 2364698878 20;
BA_ "GenMsgSendType" BO_ 2364698622 0;
BA_ "GenMsgCycleTime" BO_ 2364698622 100;
BA_ "GenMsgSendType" BO_ 2364698366 0;
BA_ "GenMsgCycleTime" BO_ 2364698366 100;
BA_ "GenMsgSendType" BO_ 2364698110 0;
BA_ "GenMsgCycleTime" BO_ 2364698110 100;
BA_ "FsJ1939UseCrcAndCounter" BO_ 2364697854 "Aa";
BA_ "GenMsgSendType" BO_ 2364697854 0;
BA_ "GenMsgCycleTime" BO_ 2364697854 100;
BA_ "GenMsgSendType" BO_ 2364697598 0;
BA_ "GenMsgCycleTime" BO_ 2364697598 100;
BA_ "GenMsgSendType" BO_ 2364697342 0;
BA_ "GenMsgCycleTime" BO_ 2364697342 100;
BA_ "GenMsgSendType" BO_ 2364697086 0;
BA_ "GenMsgCycleTime" BO_ 2364697086 100;
BA_ "GenMsgSendType" BO_ 2364696830 0;
BA_ "GenMsgCycleTime" BO_ 2364696830 100;
BA_ "FsJ1939UseCrcAndCounter" BO_ 2364696574 "Aa";
BA_ "GenMsgDelayTime" BO_ 2364696574 20;
BA_ "GenMsgSendType" BO_ 2364696574 0;
BA_ "GenMsgCycleTime" BO_ 2364696574 100;
BA_ "GenMsgSendType" BO_ 2364696318 0;
BA_ "GenMsgCycleTime" BO_ 2364696318 100;
BA_ "GenMsgSendType" BO_ 2364696062 0;
BA_ "GenMsgCycleTime" BO_ 2364696062 20;
BA_ "GenMsgSendType" BO_ 2364695806 0;
BA_ "GenMsgCycleTime" BO_ 2364695806 100;
BA_ "GenMsgSendType" BO_ 2364695550 0;
BA_ "GenMsgCycleTime" BO_ 2364695550 20;
BA_ "GenMsgSendType" BO_ 2364695294 0;
BA_ "GenMsgCycleTime" BO_ 2364695294 20;
BA_ "GenMsgSendType" BO_ 2364695038 0;
BA_ "GenMsgCycleTime" BO_ 2364695038 20;
BA_ "GenMsgSendType" BO_ 2364694782 0;
BA_ "GenMsgCycleTime" BO_ 2364694782 100;
BA_ "GenMsgSendType" BO_ 2364694526 0;
BA_ "GenMsgCycleTime" BO_ 2364694526 100;
BA_ "GenMsgSendType" BO_ 2364694270 0;
BA_ "GenMsgCycleTime" BO_ 2364694270 100;
BA_ "FsJ1939UseCrcAndCounter" BO_ 2364694014 "Aa";
BA_ "GenMsgSendType" BO_ 2364694014 0;
BA_ "GenMsgCycleTime" BO_ 2364694014 100;
BA_ "GenMsgSendType" BO_ 2364693758 0;
BA_ "GenMsgCycleTime" BO_ 2364693758 100;
BA_ "GenMsgSendType" BO_ 2364693502 0;
BA_ "GenMsgCycleTime" BO_ 2364693502 100;
BA_ "GenMsgSendType" BO_ 2364693246 0;
BA_ "GenMsgCycleTime" BO_ 2364693246 100;
BA_ "GenMsgSendType" BO_ 2364692990 0;
BA_ "GenMsgCycleTime" BO_ 2364692990 100;
BA_ "FsJ1939UseCrcAndCounter" BO_ 2364692734 "Aa";
BA_ "GenMsgDelayTime" BO_ 2364692734 20;
BA_ "GenMsgSendType" BO_ 2364692734 0;
BA_ "GenMsgCycleTime" BO_ 2364692734 100;
BA_ "GenMsgSendType" BO_ 2364692478 0;
BA_ "GenMsgCycleTime" BO_ 2364692478 100;
BA_ "GenMsgSendType" BO_ 2364692222 0;
BA_ "GenMsgCycleTime" BO_ 2364692222 20;
BA_ "GenMsgSendType" BO_ 2364691966 0;
BA_ "GenMsgCycleTime" BO_ 2364691966 100;
BA_ "SigType" SG_ 2364701950 HVBusPassiveIsolTestResults 1;
BA_ "SPN" SG_ 2364701950 HVBusPassiveIsolTestResults 15675;
BA_ "SigType" SG_ 2364701950 HVBusActiveIsolTestResults 1;
BA_ "SPN" SG_ 2364701950 HVBusActiveIsolTestResults 15674;
BA_ "SigType" SG_ 2364701950 LowestCellStOfChargeCellNum 1;
BA_ "SPN" SG_ 2364701950 LowestCellStOfChargeCellNum 15673;
BA_ "SigType" SG_ 2364701950 LowestCellStOfChargeModuleNum 1;
BA_ "SPN" SG_ 2364701950 LowestCellStOfChargeModuleNum 15672;
BA_ "SigType" SG_ 2364701950 HighestCellStOfChargeCellNum 1;
BA_ "SPN" SG_ 2364701950 HighestCellStOfChargeCellNum 15671;
BA_ "SigType" SG_ 2364701950 HighestCellStOfChargeModuleNum 1;
BA_ "SPN" SG_ 2364701950 HighestCellStOfChargeModuleNum 15670;
BA_ "SigType" SG_ 2364701694 Data9CRC 12;
BA_ "SPN" SG_ 2364701694 Data9CRC 23012;
BA_ "SigType" SG_ 2364701694 Data9Counter 11;
BA_ "SPN" SG_ 2364701694 Data9Counter 23011;
BA_ "SigType" SG_ 2364701694 Data9EmbeddedIntegritySupport 5;
BA_ "SPN" SG_ 2364701694 Data9EmbeddedIntegritySupport 23010;
BA_ "SigType" SG_ 2364701694 HVESS13ThermalEventDetected 4;
BA_ "SPN" SG_ 2364701694 HVESS13ThermalEventDetected 21300;
BA_ "SigType" SG_ 2364701694 LowestCellTempCellNum 1;
BA_ "SPN" SG_ 2364701694 LowestCellTempCellNum 15669;
BA_ "SigType" SG_ 2364701694 LowestCellTempModuleNum 1;
BA_ "SPN" SG_ 2364701694 LowestCellTempModuleNum 15668;
BA_ "SigType" SG_ 2364701694 HighestCellTempCellNum 1;
BA_ "SPN" SG_ 2364701694 HighestCellTempCellNum 15667;
BA_ "SigType" SG_ 2364701694 HighestCellTempModuleNum 1;
BA_ "SPN" SG_ 2364701694 HighestCellTempModuleNum 15666;
BA_ "SigType" SG_ 2364701438 AvgCellV 1;
BA_ "SPN" SG_ 2364701438 AvgCellV 15665;
BA_ "SigType" SG_ 2364701438 LowestCellVCellNum 1;
BA_ "SPN" SG_ 2364701438 LowestCellVCellNum 15664;
BA_ "SigType" SG_ 2364701438 LowestCellVModuleNum 1;
BA_ "SPN" SG_ 2364701438 LowestCellVModuleNum 15663;
BA_ "SigType" SG_ 2364701438 HighestCellVCellNum 1;
BA_ "SPN" SG_ 2364701438 HighestCellVCellNum 15662;
BA_ "SigType" SG_ 2364701438 HighestCellVModuleNum 1;
BA_ "SPN" SG_ 2364701438 HighestCellVModuleNum 15661;
BA_ "SigType" SG_ 2364701182 TMSCoolantLvl 4;
BA_ "SPN" SG_ 2364701182 TMSCoolantLvl 15660;
BA_ "SPN" SG_ 2364701182 TMSMode 15659;
BA_ "SigType" SG_ 2364701182 TMSHVILStatus 4;
BA_ "SPN" SG_ 2364701182 TMSHVILStatus 15658;
BA_ "SigType" SG_ 2364701182 TMSHtrStatus 5;
BA_ "SPN" SG_ 2364701182 TMSHtrStatus 15657;
BA_ "SigType" SG_ 2364701182 TMSRelHumidty 1;
BA_ "SPN" SG_ 2364701182 TMSRelHumidty 15656;
BA_ "SigType" SG_ 2364701182 TMSCompressorSpd 1;
BA_ "SPN" SG_ 2364701182 TMSCompressorSpd 15655;
BA_ "SigType" SG_ 2364701182 TMSHVInputPwr 1;
BA_ "SPN" SG_ 2364701182 TMSHVInputPwr 15654;
BA_ "SigType" SG_ 2364701182 TMSSLIInputPwr 1;
BA_ "SPN" SG_ 2364701182 TMSSLIInputPwr 15653;
BA_ "SigType" SG_ 2364700926 Module32OperationalStatus 5;
BA_ "SPN" SG_ 2364700926 Module32OperationalStatus 15652;
BA_ "SigType" SG_ 2364700926 Module31OperationalStatus 5;
BA_ "SPN" SG_ 2364700926 Module31OperationalStatus 15651;
BA_ "SigType" SG_ 2364700926 Module30OperationalStatus 5;
BA_ "SPN" SG_ 2364700926 Module30OperationalStatus 15650;
BA_ "SigType" SG_ 2364700926 Module29OperationalStatus 5;
BA_ "SPN" SG_ 2364700926 Module29OperationalStatus 15649;
BA_ "SigType" SG_ 2364700926 Module28OperationalStatus 5;
BA_ "SPN" SG_ 2364700926 Module28OperationalStatus 15648;
BA_ "SigType" SG_ 2364700926 Module27OperationalStatus 5;
BA_ "SPN" SG_ 2364700926 Module27OperationalStatus 15647;
BA_ "SigType" SG_ 2364700926 Module26OperationalStatus 5;
BA_ "SPN" SG_ 2364700926 Module26OperationalStatus 15646;
BA_ "SigType" SG_ 2364700926 Module25OperationalStatus 5;
BA_ "SPN" SG_ 2364700926 Module25OperationalStatus 15645;
BA_ "SigType" SG_ 2364700926 Module24OperationalStatus 5;
BA_ "SPN" SG_ 2364700926 Module24OperationalStatus 15644;
BA_ "SigType" SG_ 2364700926 Module23OperationalStatus 5;
BA_ "SPN" SG_ 2364700926 Module23OperationalStatus 15643;
BA_ "SigType" SG_ 2364700926 Module22OperationalStatus 5;
BA_ "SPN" SG_ 2364700926 Module22OperationalStatus 15642;
BA_ "SigType" SG_ 2364700926 Module21OperationalStatus 5;
BA_ "SPN" SG_ 2364700926 Module21OperationalStatus 15641;
BA_ "SigType" SG_ 2364700926 Module20OperationalStatus 5;
BA_ "SPN" SG_ 2364700926 Module20OperationalStatus 15640;
BA_ "SigType" SG_ 2364700926 Module19OperationalStatus 5;
BA_ "SPN" SG_ 2364700926 Module19OperationalStatus 15639;
BA_ "SigType" SG_ 2364700926 Module18OperationalStatus 5;
BA_ "SPN" SG_ 2364700926 Module18OperationalStatus 15638;
BA_ "SigType" SG_ 2364700926 Module17OperationalStatus 5;
BA_ "SPN" SG_ 2364700926 Module17OperationalStatus 15637;
BA_ "SigType" SG_ 2364700926 Module16OperationalStatus 5;
BA_ "SPN" SG_ 2364700926 Module16OperationalStatus 15636;
BA_ "SigType" SG_ 2364700926 Module15OperationalStatus 5;
BA_ "SPN" SG_ 2364700926 Module15OperationalStatus 15635;
BA_ "SigType" SG_ 2364700926 Module14OperationalStatus 5;
BA_ "SPN" SG_ 2364700926 Module14OperationalStatus 15634;
BA_ "SigType" SG_ 2364700926 Module13OperationalStatus 5;
BA_ "SPN" SG_ 2364700926 Module13OperationalStatus 15633;
BA_ "SigType" SG_ 2364700926 Module12OperationalStatus 5;
BA_ "SPN" SG_ 2364700926 Module12OperationalStatus 15632;
BA_ "SigType" SG_ 2364700926 Module11OperationalStatus 5;
BA_ "SPN" SG_ 2364700926 Module11OperationalStatus 15631;
BA_ "SigType" SG_ 2364700926 Module10OperationalStatus 5;
BA_ "SPN" SG_ 2364700926 Module10OperationalStatus 15630;
BA_ "SigType" SG_ 2364700926 Module9OperationalStatus 5;
BA_ "SPN" SG_ 2364700926 Module9OperationalStatus 15629;
BA_ "SigType" SG_ 2364700926 Module8OperationalStatus 5;
BA_ "SPN" SG_ 2364700926 Module8OperationalStatus 15628;
BA_ "SigType" SG_ 2364700926 Module7OperationalStatus 5;
BA_ "SPN" SG_ 2364700926 Module7OperationalStatus 15627;
BA_ "SigType" SG_ 2364700926 Module6OperationalStatus 5;
BA_ "SPN" SG_ 2364700926 Module6OperationalStatus 15626;
BA_ "SigType" SG_ 2364700926 Module5OperationalStatus 5;
BA_ "SPN" SG_ 2364700926 Module5OperationalStatus 15625;
BA_ "SigType" SG_ 2364700926 Module4OperationalStatus 5;
BA_ "SPN" SG_ 2364700926 Module4OperationalStatus 15624;
BA_ "SigType" SG_ 2364700926 Module3OperationalStatus 5;
BA_ "SPN" SG_ 2364700926 Module3OperationalStatus 15623;
BA_ "SigType" SG_ 2364700926 Module2OperationalStatus 5;
BA_ "SPN" SG_ 2364700926 Module2OperationalStatus 15622;
BA_ "SigType" SG_ 2364700926 Module1OperationalStatus 5;
BA_ "SPN" SG_ 2364700926 Module1OperationalStatus 15621;
BA_ "SigType" SG_ 2364700670 MaxChargeVLmt 1;
BA_ "SPN" SG_ 2364700670 MaxChargeVLmt 15620;
BA_ "SPN" SG_ 2364700670 ChargeEnergyCapacity 15619;
BA_ "SPN" SG_ 2364700670 DisEnergyCapacity 15618;
BA_ "SigType" SG_ 2364700414 Status1CRC 12;
BA_ "SPN" SG_ 2364700414 Status1CRC 15617;
BA_ "SigType" SG_ 2364700414 Status1Counter 11;
BA_ "SPN" SG_ 2364700414 Status1Counter 15616;
BA_ "SPN" SG_ 2364700414 OperationalStatus 15615;
BA_ "SPN" SG_ 2364700414 HVBusConnectionStatus 15614;
BA_ "SigType" SG_ 2364700414 InternalChargerStatus 5;
BA_ "SPN" SG_ 2364700414 InternalChargerStatus 15613;
BA_ "SigType" SG_ 2364700414 CellBalancingActive 4;
BA_ "SPN" SG_ 2364700414 CellBalancingActive 15612;
BA_ "SigType" SG_ 2364700414 CellBalanceStatus 4;
BA_ "SPN" SG_ 2364700414 CellBalanceStatus 15611;
BA_ "SPN" SG_ 2364700414 StOfChargeStatus 15610;
BA_ "SigType" SG_ 2364700414 InertiaSwStatus 4;
BA_ "SPN" SG_ 2364700414 InertiaSwStatus 15609;
BA_ "SigType" SG_ 2364700414 HVILStatus 4;
BA_ "SPN" SG_ 2364700414 HVILStatus 15608;
BA_ "SPN" SG_ 2364700414 HVBusPassiveIsolTestStatus 15607;
BA_ "SPN" SG_ 2364700414 HVBusActiveIsolTestStatus 15606;
BA_ "SigType" SG_ 2364700414 CenterOfPackContactorSt 4;
BA_ "SPN" SG_ 2364700414 CenterOfPackContactorSt 15605;
BA_ "SigType" SG_ 2364700414 HVBusPreChargeRelaySt 4;
BA_ "SPN" SG_ 2364700414 HVBusPreChargeRelaySt 15604;
BA_ "SPN" SG_ 2364700414 HVBusDisconnectForewarning 15603;
BA_ "SigType" SG_ 2364700414 HVBusContactorSt15602 4;
BA_ "SPN" SG_ 2364700414 HVBusContactorSt15602 15602;
BA_ "SigType" SG_ 2364700414 HVBusContactorSt 4;
BA_ "SPN" SG_ 2364700414 HVBusContactorSt 15601;
BA_ "SigType" SG_ 2364700158 Temp 1;
BA_ "SPN" SG_ 2364700158 Temp 15600;
BA_ "SigType" SG_ 2364700158 ETemp 1;
BA_ "SPN" SG_ 2364700158 ETemp 15599;
BA_ "SigType" SG_ 2364700158 OutCoolantTemp 1;
BA_ "SPN" SG_ 2364700158 OutCoolantTemp 15598;
BA_ "SigType" SG_ 2364700158 InCoolantTemp 1;
BA_ "SPN" SG_ 2364700158 InCoolantTemp 15597;
BA_ "SigType" SG_ 2364700158 IgntV 1;
BA_ "SPN" SG_ 2364700158 IgntV 15596;
BA_ "SigType" SG_ 2364700158 BusV 1;
BA_ "SPN" SG_ 2364700158 BusV 15595;
BA_ "SigType" SG_ 2364699902 HighestCellStOfCharge 1;
BA_ "SPN" SG_ 2364699902 HighestCellStOfCharge 15594;
BA_ "SigType" SG_ 2364699902 LowestCellStOfCharge 1;
BA_ "SPN" SG_ 2364699902 LowestCellStOfCharge 15593;
BA_ "SigType" SG_ 2364699902 ChargeCurLmt 1;
BA_ "GenSigStartValue" SG_ 2364699902 ChargeCurLmt 32000;
BA_ "SPN" SG_ 2364699902 ChargeCurLmt 15592;
BA_ "SigType" SG_ 2364699902 DisCurLmt 1;
BA_ "SPN" SG_ 2364699902 DisCurLmt 15591;
BA_ "SigType" SG_ 2364699646 CellBalancingCount 1;
BA_ "SPN" SG_ 2364699646 CellBalancingCount 15590;
BA_ "SigType" SG_ 2364699646 ChargeCapacity 1;
BA_ "SPN" SG_ 2364699646 ChargeCapacity 15589;
BA_ "SigType" SG_ 2364699646 DisCapacity 1;
BA_ "SPN" SG_ 2364699646 DisCapacity 15588;
BA_ "SigType" SG_ 2364699390 CellTempDiffStatus 4;
BA_ "SPN" SG_ 2364699390 CellTempDiffStatus 15587;
BA_ "SigType" SG_ 2364699390 AvgCellTemp 1;
BA_ "SPN" SG_ 2364699390 AvgCellTemp 15586;
BA_ "SigType" SG_ 2364699390 LowestCellTemp 1;
BA_ "SPN" SG_ 2364699390 LowestCellTemp 15585;
BA_ "SigType" SG_ 2364699390 HighestCellTemp 1;
BA_ "SPN" SG_ 2364699390 HighestCellTemp 15584;
BA_ "SPN" SG_ 2364699134 CellVDiffStatus 15583;
BA_ "SigType" SG_ 2364699134 LowestCellV 1;
BA_ "SPN" SG_ 2364699134 LowestCellV 15582;
BA_ "SigType" SG_ 2364699134 HighestCellV 1;
BA_ "SPN" SG_ 2364699134 HighestCellV 15581;
BA_ "SigType" SG_ 2364699134 FastUpdateStOfCharge 1;
BA_ "SPN" SG_ 2364699134 FastUpdateStOfCharge 15580;
BA_ "SigType" SG_ 2364698878 Cur 1;
BA_ "SPN" SG_ 2364698878 Cur 15579;
BA_ "SigType" SG_ 2364698878 Lvl 1;
BA_ "SPN" SG_ 2364698878 Lvl 15578;
BA_ "SigType" SG_ 2364698878 AvailableChargePwr 1;
BA_ "SPN" SG_ 2364698878 AvailableChargePwr 15577;
BA_ "SigType" SG_ 2364698878 AvailableDisPwr 1;
BA_ "SPN" SG_ 2364698878 AvailableDisPwr 15576;
BA_ "SigType" SG_ 2364698622 ChargePLDueToAnUndefinedCause 4;
BA_ "SPN" SG_ 2364698622 ChargePLDueToAnUndefinedCause 15575;
BA_ "SigType" SG_ 2364698622 ChargePLDueToBatCur 4;
BA_ "SPN" SG_ 2364698622 ChargePLDueToBatCur 15574;
BA_ "SigType" SG_ 2364698622 ChargePLDueToBatOrCellV 4;
BA_ "SPN" SG_ 2364698622 ChargePLDueToBatOrCellV 15573;
BA_ "SigType" SG_ 2364698622 ChargePLDueToBatDiagCondition 4;
BA_ "SPN" SG_ 2364698622 ChargePLDueToBatDiagCondition 15572;
BA_ "SigType" SG_ 2364698622 ChargePLDueToBatTemp 4;
BA_ "SPN" SG_ 2364698622 ChargePLDueToBatTemp 15571;
BA_ "SigType" SG_ 2364698622 ChargePLDueToStOfCharge 4;
BA_ "SPN" SG_ 2364698622 ChargePLDueToStOfCharge 15570;
BA_ "SigType" SG_ 2364698622 DisPLDueToAnUndefinedCause 4;
BA_ "SPN" SG_ 2364698622 DisPLDueToAnUndefinedCause 15569;
BA_ "SigType" SG_ 2364698622 DisPLDueToBatCur 4;
BA_ "SPN" SG_ 2364698622 DisPLDueToBatCur 15568;
BA_ "SigType" SG_ 2364698622 DisPLDueToBatOrCellV 4;
BA_ "SPN" SG_ 2364698622 DisPLDueToBatOrCellV 15567;
BA_ "SigType" SG_ 2364698622 DisPLDueToBatDiagCondition 4;
BA_ "SPN" SG_ 2364698622 DisPLDueToBatDiagCondition 15566;
BA_ "SigType" SG_ 2364698622 DisPLDueToBatTemp 4;
BA_ "SPN" SG_ 2364698622 DisPLDueToBatTemp 15565;
BA_ "SigType" SG_ 2364698622 DisPLDueToStOfCharge 4;
BA_ "SPN" SG_ 2364698622 DisPLDueToStOfCharge 15564;
BA_ "SigType" SG_ 2364698366 ActualChargeRate 1;
BA_ "SPN" SG_ 2364698366 ActualChargeRate 15536;
BA_ "SigType" SG_ 2364698366 LvlNegToChassisGroundV 1;
BA_ "SPN" SG_ 2364698366 LvlNegToChassisGroundV 15535;
BA_ "SigType" SG_ 2364698366 BusVNegToChassisGroundV 1;
BA_ "SPN" SG_ 2364698366 BusVNegToChassisGroundV 15534;
BA_ "SigType" SG_ 2364698110 HVBusPassiveIsolTestResults 1;
BA_ "SPN" SG_ 2364698110 HVBusPassiveIsolTestResults 15533;
BA_ "SigType" SG_ 2364698110 HVBusActiveIsolTestResults 1;
BA_ "SPN" SG_ 2364698110 HVBusActiveIsolTestResults 15532;
BA_ "SigType" SG_ 2364698110 LowestCellStOfChargeCellNum 1;
BA_ "SPN" SG_ 2364698110 LowestCellStOfChargeCellNum 15531;
BA_ "SigType" SG_ 2364698110 LowestCellStOfChargeModuleNum 1;
BA_ "SPN" SG_ 2364698110 LowestCellStOfChargeModuleNum 15530;
BA_ "SigType" SG_ 2364698110 HighestCellStOfChargeCellNum 1;
BA_ "SPN" SG_ 2364698110 HighestCellStOfChargeCellNum 15529;
BA_ "SigType" SG_ 2364698110 HighestCellStOfChargeModuleNum 1;
BA_ "SPN" SG_ 2364698110 HighestCellStOfChargeModuleNum 15528;
BA_ "SigType" SG_ 2364697854 Data9CRC 12;
BA_ "SPN" SG_ 2364697854 Data9CRC 23009;
BA_ "SigType" SG_ 2364697854 Data9Counter 11;
BA_ "SPN" SG_ 2364697854 Data9Counter 23008;
BA_ "SigType" SG_ 2364697854 Data9EmbeddedIntegritySupport 5;
BA_ "SPN" SG_ 2364697854 Data9EmbeddedIntegritySupport 23007;
BA_ "SigType" SG_ 2364697854 HVESS12ThermalEventDetected 4;
BA_ "SPN" SG_ 2364697854 HVESS12ThermalEventDetected 21299;
BA_ "SigType" SG_ 2364697854 LowestCellTempCellNum 1;
BA_ "SPN" SG_ 2364697854 LowestCellTempCellNum 15527;
BA_ "SigType" SG_ 2364697854 LowestCellTempModuleNum 1;
BA_ "SPN" SG_ 2364697854 LowestCellTempModuleNum 15526;
BA_ "SigType" SG_ 2364697854 HighestCellTempCellNum 1;
BA_ "SPN" SG_ 2364697854 HighestCellTempCellNum 15525;
BA_ "SigType" SG_ 2364697854 HighestCellTempModuleNum 1;
BA_ "SPN" SG_ 2364697854 HighestCellTempModuleNum 15524;
BA_ "SigType" SG_ 2364697598 AvgCellV 1;
BA_ "SPN" SG_ 2364697598 AvgCellV 15523;
BA_ "SigType" SG_ 2364697598 LowestCellVCellNum 1;
BA_ "SPN" SG_ 2364697598 LowestCellVCellNum 15522;
BA_ "SigType" SG_ 2364697598 LowestCellVModuleNum 1;
BA_ "SPN" SG_ 2364697598 LowestCellVModuleNum 15521;
BA_ "SigType" SG_ 2364697598 HighestCellVCellNum 1;
BA_ "SPN" SG_ 2364697598 HighestCellVCellNum 15520;
BA_ "SigType" SG_ 2364697598 HighestCellVModuleNum 1;
BA_ "SPN" SG_ 2364697598 HighestCellVModuleNum 15519;
BA_ "SigType" SG_ 2364697342 TMSCoolantLvl 4;
BA_ "SPN" SG_ 2364697342 TMSCoolantLvl 15518;
BA_ "SPN" SG_ 2364697342 TMSMode 15517;
BA_ "SigType" SG_ 2364697342 TMSHVILStatus 4;
BA_ "SPN" SG_ 2364697342 TMSHVILStatus 15516;
BA_ "SigType" SG_ 2364697342 TMSHtrStatus 5;
BA_ "SPN" SG_ 2364697342 TMSHtrStatus 15515;
BA_ "SigType" SG_ 2364697342 TMSRelHumidty 1;
BA_ "SPN" SG_ 2364697342 TMSRelHumidty 15514;
BA_ "SigType" SG_ 2364697342 TMSCompressorSpd 1;
BA_ "SPN" SG_ 2364697342 TMSCompressorSpd 15513;
BA_ "SigType" SG_ 2364697342 TMSHVInputPwr 1;
BA_ "SPN" SG_ 2364697342 TMSHVInputPwr 15512;
BA_ "SigType" SG_ 2364697342 TMSSLIInputPwr 1;
BA_ "SPN" SG_ 2364697342 TMSSLIInputPwr 15511;
BA_ "SigType" SG_ 2364697086 Module32OperationalStatus 5;
BA_ "SPN" SG_ 2364697086 Module32OperationalStatus 15510;
BA_ "SigType" SG_ 2364697086 Module31OperationalStatus 5;
BA_ "SPN" SG_ 2364697086 Module31OperationalStatus 15509;
BA_ "SigType" SG_ 2364697086 Module30OperationalStatus 5;
BA_ "SPN" SG_ 2364697086 Module30OperationalStatus 15508;
BA_ "SigType" SG_ 2364697086 Module29OperationalStatus 5;
BA_ "SPN" SG_ 2364697086 Module29OperationalStatus 15507;
BA_ "SigType" SG_ 2364697086 Module28OperationalStatus 5;
BA_ "SPN" SG_ 2364697086 Module28OperationalStatus 15506;
BA_ "SigType" SG_ 2364697086 Module27OperationalStatus 5;
BA_ "SPN" SG_ 2364697086 Module27OperationalStatus 15505;
BA_ "SigType" SG_ 2364697086 Module26OperationalStatus 5;
BA_ "SPN" SG_ 2364697086 Module26OperationalStatus 15504;
BA_ "SigType" SG_ 2364697086 Module25OperationalStatus 5;
BA_ "SPN" SG_ 2364697086 Module25OperationalStatus 15503;
BA_ "SigType" SG_ 2364697086 Module24OperationalStatus 5;
BA_ "SPN" SG_ 2364697086 Module24OperationalStatus 15502;
BA_ "SigType" SG_ 2364697086 Module23OperationalStatus 5;
BA_ "SPN" SG_ 2364697086 Module23OperationalStatus 15501;
BA_ "SigType" SG_ 2364697086 Module22OperationalStatus 5;
BA_ "SPN" SG_ 2364697086 Module22OperationalStatus 15500;
BA_ "SigType" SG_ 2364697086 Module21OperationalStatus 5;
BA_ "SPN" SG_ 2364697086 Module21OperationalStatus 15499;
BA_ "SigType" SG_ 2364697086 Module20OperationalStatus 5;
BA_ "SPN" SG_ 2364697086 Module20OperationalStatus 15498;
BA_ "SigType" SG_ 2364697086 Module19OperationalStatus 5;
BA_ "SPN" SG_ 2364697086 Module19OperationalStatus 15497;
BA_ "SigType" SG_ 2364697086 Module18OperationalStatus 5;
BA_ "SPN" SG_ 2364697086 Module18OperationalStatus 15496;
BA_ "SigType" SG_ 2364697086 Module17OperationalStatus 5;
BA_ "SPN" SG_ 2364697086 Module17OperationalStatus 15495;
BA_ "SigType" SG_ 2364697086 Module16OperationalStatus 5;
BA_ "SPN" SG_ 2364697086 Module16OperationalStatus 15494;
BA_ "SigType" SG_ 2364697086 Module15OperationalStatus 5;
BA_ "SPN" SG_ 2364697086 Module15OperationalStatus 15493;
BA_ "SigType" SG_ 2364697086 Module14OperationalStatus 5;
BA_ "SPN" SG_ 2364697086 Module14OperationalStatus 15492;
BA_ "SigType" SG_ 2364697086 Module13OperationalStatus 5;
BA_ "SPN" SG_ 2364697086 Module13OperationalStatus 15491;
BA_ "SigType" SG_ 2364697086 Module12OperationalStatus 5;
BA_ "SPN" SG_ 2364697086 Module12OperationalStatus 15490;
BA_ "SigType" SG_ 2364697086 Module11OperationalStatus 5;
BA_ "SPN" SG_ 2364697086 Module11OperationalStatus 15489;
BA_ "SigType" SG_ 2364697086 Module10OperationalStatus 5;
BA_ "SPN" SG_ 2364697086 Module10OperationalStatus 15488;
BA_ "SigType" SG_ 2364697086 Module9OperationalStatus 5;
BA_ "SPN" SG_ 2364697086 Module9OperationalStatus 15487;
BA_ "SigType" SG_ 2364697086 Module8OperationalStatus 5;
BA_ "SPN" SG_ 2364697086 Module8OperationalStatus 15486;
BA_ "SigType" SG_ 2364697086 Module7OperationalStatus 5;
BA_ "SPN" SG_ 2364697086 Module7OperationalStatus 15485;
BA_ "SigType" SG_ 2364697086 Module6OperationalStatus 5;
BA_ "SPN" SG_ 2364697086 Module6OperationalStatus 15484;
BA_ "SigType" SG_ 2364697086 Module5OperationalStatus 5;
BA_ "SPN" SG_ 2364697086 Module5OperationalStatus 15483;
BA_ "SigType" SG_ 2364697086 Module4OperationalStatus 5;
BA_ "SPN" SG_ 2364697086 Module4OperationalStatus 15482;
BA_ "SigType" SG_ 2364697086 Module3OperationalStatus 5;
BA_ "SPN" SG_ 2364697086 Module3OperationalStatus 15481;
BA_ "SigType" SG_ 2364697086 Module2OperationalStatus 5;
BA_ "SPN" SG_ 2364697086 Module2OperationalStatus 15480;
BA_ "SigType" SG_ 2364697086 Module1OperationalStatus 5;
BA_ "SPN" SG_ 2364697086 Module1OperationalStatus 15479;
BA_ "SigType" SG_ 2364696830 MaxChargeVLmt 1;
BA_ "SPN" SG_ 2364696830 MaxChargeVLmt 15478;
BA_ "SPN" SG_ 2364696830 ChargeEnergyCapacity 15477;
BA_ "SPN" SG_ 2364696830 DisEnergyCapacity 15476;
BA_ "SigType" SG_ 2364696574 Status1CRC 12;
BA_ "SPN" SG_ 2364696574 Status1CRC 15475;
BA_ "SigType" SG_ 2364696574 Status1Counter 11;
BA_ "SPN" SG_ 2364696574 Status1Counter 15474;
BA_ "SPN" SG_ 2364696574 OperationalStatus 15473;
BA_ "SPN" SG_ 2364696574 HVBusConnectionStatus 15472;
BA_ "SigType" SG_ 2364696574 InternalChargerStatus 5;
BA_ "SPN" SG_ 2364696574 InternalChargerStatus 15471;
BA_ "SigType" SG_ 2364696574 CellBalancingActive 4;
BA_ "SPN" SG_ 2364696574 CellBalancingActive 15470;
BA_ "SigType" SG_ 2364696574 CellBalanceStatus 4;
BA_ "SPN" SG_ 2364696574 CellBalanceStatus 15469;
BA_ "SPN" SG_ 2364696574 StOfChargeStatus 15468;
BA_ "SigType" SG_ 2364696574 InertiaSwStatus 4;
BA_ "SPN" SG_ 2364696574 InertiaSwStatus 15467;
BA_ "SigType" SG_ 2364696574 HVILStatus 4;
BA_ "SPN" SG_ 2364696574 HVILStatus 15466;
BA_ "SPN" SG_ 2364696574 HVBusPassiveIsolTestStatus 15465;
BA_ "SPN" SG_ 2364696574 HVBusActiveIsolTestStatus 15464;
BA_ "SigType" SG_ 2364696574 CenterOfPackContactorSt 4;
BA_ "SPN" SG_ 2364696574 CenterOfPackContactorSt 15463;
BA_ "SigType" SG_ 2364696574 HVBusPreChargeRelaySt 4;
BA_ "SPN" SG_ 2364696574 HVBusPreChargeRelaySt 15462;
BA_ "SPN" SG_ 2364696574 HVBusDisconnectForewarning 15461;
BA_ "SigType" SG_ 2364696574 HVBusContactorSt15460 4;
BA_ "SPN" SG_ 2364696574 HVBusContactorSt15460 15460;
BA_ "SigType" SG_ 2364696574 HVBusContactorSt 4;
BA_ "SPN" SG_ 2364696574 HVBusContactorSt 15459;
BA_ "SigType" SG_ 2364696318 Temp 1;
BA_ "SPN" SG_ 2364696318 Temp 15458;
BA_ "SigType" SG_ 2364696318 ETemp 1;
BA_ "SPN" SG_ 2364696318 ETemp 15457;
BA_ "SigType" SG_ 2364696318 OutCoolantTemp 1;
BA_ "SPN" SG_ 2364696318 OutCoolantTemp 15456;
BA_ "SigType" SG_ 2364696318 InCoolantTemp 1;
BA_ "SPN" SG_ 2364696318 InCoolantTemp 15455;
BA_ "SigType" SG_ 2364696318 IgntV 1;
BA_ "SPN" SG_ 2364696318 IgntV 15454;
BA_ "SigType" SG_ 2364696318 BusV 1;
BA_ "SPN" SG_ 2364696318 BusV 15453;
BA_ "SigType" SG_ 2364696062 HighestCellStOfCharge 1;
BA_ "SPN" SG_ 2364696062 HighestCellStOfCharge 15452;
BA_ "SigType" SG_ 2364696062 LowestCellStOfCharge 1;
BA_ "SPN" SG_ 2364696062 LowestCellStOfCharge 15451;
BA_ "SigType" SG_ 2364696062 ChargeCurLmt 1;
BA_ "GenSigStartValue" SG_ 2364696062 ChargeCurLmt 32000;
BA_ "SPN" SG_ 2364696062 ChargeCurLmt 15450;
BA_ "SigType" SG_ 2364696062 DisCurLmt 1;
BA_ "SPN" SG_ 2364696062 DisCurLmt 15449;
BA_ "SigType" SG_ 2364695806 CellBalancingCount 1;
BA_ "SPN" SG_ 2364695806 CellBalancingCount 15448;
BA_ "SigType" SG_ 2364695806 ChargeCapacity 1;
BA_ "SPN" SG_ 2364695806 ChargeCapacity 15447;
BA_ "SigType" SG_ 2364695806 DisCapacity 1;
BA_ "SPN" SG_ 2364695806 DisCapacity 15446;
BA_ "SigType" SG_ 2364695550 CellTempDiffStatus 4;
BA_ "SPN" SG_ 2364695550 CellTempDiffStatus 15445;
BA_ "SigType" SG_ 2364695550 AvgCellTemp 1;
BA_ "SPN" SG_ 2364695550 AvgCellTemp 15444;
BA_ "SigType" SG_ 2364695550 LowestCellTemp 1;
BA_ "SPN" SG_ 2364695550 LowestCellTemp 15443;
BA_ "SigType" SG_ 2364695550 HighestCellTemp 1;
BA_ "SPN" SG_ 2364695550 HighestCellTemp 15442;
BA_ "SPN" SG_ 2364695294 CellVDiffStatus 15441;
BA_ "SigType" SG_ 2364695294 LowestCellV 1;
BA_ "SPN" SG_ 2364695294 LowestCellV 15440;
BA_ "SigType" SG_ 2364695294 HighestCellV 1;
BA_ "SPN" SG_ 2364695294 HighestCellV 15439;
BA_ "SigType" SG_ 2364695294 FastUpdateStOfCharge 1;
BA_ "SPN" SG_ 2364695294 FastUpdateStOfCharge 15438;
BA_ "SigType" SG_ 2364695038 Cur 1;
BA_ "SPN" SG_ 2364695038 Cur 15437;
BA_ "SigType" SG_ 2364695038 Lvl 1;
BA_ "SPN" SG_ 2364695038 Lvl 15436;
BA_ "SigType" SG_ 2364695038 AvailableChargePwr 1;
BA_ "SPN" SG_ 2364695038 AvailableChargePwr 15435;
BA_ "SigType" SG_ 2364695038 AvailableDisPwr 1;
BA_ "SPN" SG_ 2364695038 AvailableDisPwr 15434;
BA_ "SigType" SG_ 2364694782 ChargePLDueToAnUndefinedCause 4;
BA_ "SPN" SG_ 2364694782 ChargePLDueToAnUndefinedCause 15433;
BA_ "SigType" SG_ 2364694782 ChargePLDueToBatCur 4;
BA_ "SPN" SG_ 2364694782 ChargePLDueToBatCur 15432;
BA_ "SigType" SG_ 2364694782 ChargePLDueToBatOrCellV 4;
BA_ "SPN" SG_ 2364694782 ChargePLDueToBatOrCellV 15431;
BA_ "SigType" SG_ 2364694782 ChargePLDueToBatDiagCondition 4;
BA_ "SPN" SG_ 2364694782 ChargePLDueToBatDiagCondition 15430;
BA_ "SigType" SG_ 2364694782 ChargePLDueToBatTemp 4;
BA_ "SPN" SG_ 2364694782 ChargePLDueToBatTemp 15429;
BA_ "SigType" SG_ 2364694782 ChargePLDueToStOfCharge 4;
BA_ "SPN" SG_ 2364694782 ChargePLDueToStOfCharge 15428;
BA_ "SigType" SG_ 2364694782 DisPLDueToAnUndefinedCause 4;
BA_ "SPN" SG_ 2364694782 DisPLDueToAnUndefinedCause 15427;
BA_ "SigType" SG_ 2364694782 DisPLDueToBatCur 4;
BA_ "SPN" SG_ 2364694782 DisPLDueToBatCur 15426;
BA_ "SigType" SG_ 2364694782 DisPLDueToBatOrCellV 4;
BA_ "SPN" SG_ 2364694782 DisPLDueToBatOrCellV 15425;
BA_ "SigType" SG_ 2364694782 DisPLDueToBatDiagCondition 4;
BA_ "SPN" SG_ 2364694782 DisPLDueToBatDiagCondition 15424;
BA_ "SigType" SG_ 2364694782 DisPLDueToBatTemp 4;
BA_ "SPN" SG_ 2364694782 DisPLDueToBatTemp 15423;
BA_ "SigType" SG_ 2364694782 DisPLDueToStOfCharge 4;
BA_ "SPN" SG_ 2364694782 DisPLDueToStOfCharge 15422;
BA_ "SigType" SG_ 2364694526 ActualChargeRate 1;
BA_ "SPN" SG_ 2364694526 ActualChargeRate 15394;
BA_ "SigType" SG_ 2364694526 LvlNegToChassisGroundV 1;
BA_ "SPN" SG_ 2364694526 LvlNegToChassisGroundV 15393;
BA_ "SigType" SG_ 2364694526 BusVNegToChassisGroundV 1;
BA_ "SPN" SG_ 2364694526 BusVNegToChassisGroundV 15392;
BA_ "SigType" SG_ 2364694270 HVBusPassiveIsolTestResults 1;
BA_ "SPN" SG_ 2364694270 HVBusPassiveIsolTestResults 15391;
BA_ "SigType" SG_ 2364694270 HVBusActiveIsolTestResults 1;
BA_ "SPN" SG_ 2364694270 HVBusActiveIsolTestResults 15390;
BA_ "SigType" SG_ 2364694270 LowestCellStOfChargeCellNum 1;
BA_ "SPN" SG_ 2364694270 LowestCellStOfChargeCellNum 15389;
BA_ "SigType" SG_ 2364694270 LowestCellStOfChargeModuleNum 1;
BA_ "SPN" SG_ 2364694270 LowestCellStOfChargeModuleNum 15388;
BA_ "SigType" SG_ 2364694270 HighestCellStOfChargeCellNum 1;
BA_ "SPN" SG_ 2364694270 HighestCellStOfChargeCellNum 15387;
BA_ "SigType" SG_ 2364694270 HighestCellStOfChargeModuleNum 1;
BA_ "SPN" SG_ 2364694270 HighestCellStOfChargeModuleNum 15386;
BA_ "SigType" SG_ 2364694014 Data9CRC 12;
BA_ "SPN" SG_ 2364694014 Data9CRC 23006;
BA_ "SigType" SG_ 2364694014 Data9Counter 11;
BA_ "SPN" SG_ 2364694014 Data9Counter 23005;
BA_ "SigType" SG_ 2364694014 Data9EmbeddedIntegritySupport 5;
BA_ "SPN" SG_ 2364694014 Data9EmbeddedIntegritySupport 23004;
BA_ "SigType" SG_ 2364694014 HVESS11ThermalEventDetected 4;
BA_ "SPN" SG_ 2364694014 HVESS11ThermalEventDetected 21298;
BA_ "SigType" SG_ 2364694014 LowestCellTempCellNum 1;
BA_ "SPN" SG_ 2364694014 LowestCellTempCellNum 15385;
BA_ "SigType" SG_ 2364694014 LowestCellTempModuleNum 1;
BA_ "SPN" SG_ 2364694014 LowestCellTempModuleNum 15384;
BA_ "SigType" SG_ 2364694014 HighestCellTempCellNum 1;
BA_ "SPN" SG_ 2364694014 HighestCellTempCellNum 15383;
BA_ "SigType" SG_ 2364694014 HighestCellTempModuleNum 1;
BA_ "SPN" SG_ 2364694014 HighestCellTempModuleNum 15382;
BA_ "SigType" SG_ 2364693758 AvgCellV 1;
BA_ "SPN" SG_ 2364693758 AvgCellV 15381;
BA_ "SigType" SG_ 2364693758 LowestCellVCellNum 1;
BA_ "SPN" SG_ 2364693758 LowestCellVCellNum 15380;
BA_ "SigType" SG_ 2364693758 LowestCellVModuleNum 1;
BA_ "SPN" SG_ 2364693758 LowestCellVModuleNum 15379;
BA_ "SigType" SG_ 2364693758 HighestCellVCellNum 1;
BA_ "SPN" SG_ 2364693758 HighestCellVCellNum 15378;
BA_ "SigType" SG_ 2364693758 HighestCellVModuleNum 1;
BA_ "SPN" SG_ 2364693758 HighestCellVModuleNum 15377;
BA_ "SigType" SG_ 2364693502 TMSCoolantLvl 4;
BA_ "SPN" SG_ 2364693502 TMSCoolantLvl 15376;
BA_ "SPN" SG_ 2364693502 TMSMode 15375;
BA_ "SigType" SG_ 2364693502 TMSHVILStatus 4;
BA_ "SPN" SG_ 2364693502 TMSHVILStatus 15374;
BA_ "SigType" SG_ 2364693502 TMSHtrStatus 5;
BA_ "SPN" SG_ 2364693502 TMSHtrStatus 15373;
BA_ "SigType" SG_ 2364693502 TMSRelHumidty 1;
BA_ "SPN" SG_ 2364693502 TMSRelHumidty 15372;
BA_ "SigType" SG_ 2364693502 TMSCompressorSpd 1;
BA_ "SPN" SG_ 2364693502 TMSCompressorSpd 15371;
BA_ "SigType" SG_ 2364693502 TMSHVInputPwr 1;
BA_ "SPN" SG_ 2364693502 TMSHVInputPwr 15370;
BA_ "SigType" SG_ 2364693502 TMSSLIInputPwr 1;
BA_ "SPN" SG_ 2364693502 TMSSLIInputPwr 15369;
BA_ "SigType" SG_ 2364693246 Module32OperationalStatus 5;
BA_ "SPN" SG_ 2364693246 Module32OperationalStatus 15368;
BA_ "SigType" SG_ 2364693246 Module31OperationalStatus 5;
BA_ "SPN" SG_ 2364693246 Module31OperationalStatus 15367;
BA_ "SigType" SG_ 2364693246 Module30OperationalStatus 5;
BA_ "SPN" SG_ 2364693246 Module30OperationalStatus 15366;
BA_ "SigType" SG_ 2364693246 Module29OperationalStatus 5;
BA_ "SPN" SG_ 2364693246 Module29OperationalStatus 15365;
BA_ "SigType" SG_ 2364693246 Module28OperationalStatus 5;
BA_ "SPN" SG_ 2364693246 Module28OperationalStatus 15364;
BA_ "SigType" SG_ 2364693246 Module27OperationalStatus 5;
BA_ "SPN" SG_ 2364693246 Module27OperationalStatus 15363;
BA_ "SigType" SG_ 2364693246 Module26OperationalStatus 5;
BA_ "SPN" SG_ 2364693246 Module26OperationalStatus 15362;
BA_ "SigType" SG_ 2364693246 Module25OperationalStatus 5;
BA_ "SPN" SG_ 2364693246 Module25OperationalStatus 15361;
BA_ "SigType" SG_ 2364693246 Module24OperationalStatus 5;
BA_ "SPN" SG_ 2364693246 Module24OperationalStatus 15360;
BA_ "SigType" SG_ 2364693246 Module23OperationalStatus 5;
BA_ "SPN" SG_ 2364693246 Module23OperationalStatus 15359;
BA_ "SigType" SG_ 2364693246 Module22OperationalStatus 5;
BA_ "SPN" SG_ 2364693246 Module22OperationalStatus 15358;
BA_ "SigType" SG_ 2364693246 Module21OperationalStatus 5;
BA_ "SPN" SG_ 2364693246 Module21OperationalStatus 15357;
BA_ "SigType" SG_ 2364693246 Module20OperationalStatus 5;
BA_ "SPN" SG_ 2364693246 Module20OperationalStatus 15356;
BA_ "SigType" SG_ 2364693246 Module19OperationalStatus 5;
BA_ "SPN" SG_ 2364693246 Module19OperationalStatus 15355;
BA_ "SigType" SG_ 2364693246 Module18OperationalStatus 5;
BA_ "SPN" SG_ 2364693246 Module18OperationalStatus 15354;
BA_ "SigType" SG_ 2364693246 Module17OperationalStatus 5;
BA_ "SPN" SG_ 2364693246 Module17OperationalStatus 15353;
BA_ "SigType" SG_ 2364693246 Module16OperationalStatus 5;
BA_ "SPN" SG_ 2364693246 Module16OperationalStatus 15352;
BA_ "SigType" SG_ 2364693246 Module15OperationalStatus 5;
BA_ "SPN" SG_ 2364693246 Module15OperationalStatus 15351;
BA_ "SigType" SG_ 2364693246 Module14OperationalStatus 5;
BA_ "SPN" SG_ 2364693246 Module14OperationalStatus 15350;
BA_ "SigType" SG_ 2364693246 Module13OperationalStatus 5;
BA_ "SPN" SG_ 2364693246 Module13OperationalStatus 15349;
BA_ "SigType" SG_ 2364693246 Module12OperationalStatus 5;
BA_ "SPN" SG_ 2364693246 Module12OperationalStatus 15348;
BA_ "SigType" SG_ 2364693246 Module11OperationalStatus 5;
BA_ "SPN" SG_ 2364693246 Module11OperationalStatus 15347;
BA_ "SigType" SG_ 2364693246 Module10OperationalStatus 5;
BA_ "SPN" SG_ 2364693246 Module10OperationalStatus 15346;
BA_ "SigType" SG_ 2364693246 Module9OperationalStatus 5;
BA_ "SPN" SG_ 2364693246 Module9OperationalStatus 15345;
BA_ "SigType" SG_ 2364693246 Module8OperationalStatus 5;
BA_ "SPN" SG_ 2364693246 Module8OperationalStatus 15344;
BA_ "SigType" SG_ 2364693246 Module7OperationalStatus 5;
BA_ "SPN" SG_ 2364693246 Module7OperationalStatus 15343;
BA_ "SigType" SG_ 2364693246 Module6OperationalStatus 5;
BA_ "SPN" SG_ 2364693246 Module6OperationalStatus 15342;
BA_ "SigType" SG_ 2364693246 Module5OperationalStatus 5;
BA_ "SPN" SG_ 2364693246 Module5OperationalStatus 15341;
BA_ "SigType" SG_ 2364693246 Module4OperationalStatus 5;
BA_ "SPN" SG_ 2364693246 Module4OperationalStatus 15340;
BA_ "SigType" SG_ 2364693246 Module3OperationalStatus 5;
BA_ "SPN" SG_ 2364693246 Module3OperationalStatus 15339;
BA_ "SigType" SG_ 2364693246 Module2OperationalStatus 5;
BA_ "SPN" SG_ 2364693246 Module2OperationalStatus 15338;
BA_ "SigType" SG_ 2364693246 Module1OperationalStatus 5;
BA_ "SPN" SG_ 2364693246 Module1OperationalStatus 15337;
BA_ "SigType" SG_ 2364692990 MaxChargeVLmt 1;
BA_ "SPN" SG_ 2364692990 MaxChargeVLmt 15336;
BA_ "SPN" SG_ 2364692990 ChargeEnergyCapacity 15335;
BA_ "SPN" SG_ 2364692990 DisEnergyCapacity 15334;
BA_ "SigType" SG_ 2364692734 Status1CRC 12;
BA_ "SPN" SG_ 2364692734 Status1CRC 15333;
BA_ "SigType" SG_ 2364692734 Status1Counter 11;
BA_ "SPN" SG_ 2364692734 Status1Counter 15332;
BA_ "SPN" SG_ 2364692734 OperationalStatus 15331;
BA_ "SPN" SG_ 2364692734 HVBusConnectionStatus 15330;
BA_ "SigType" SG_ 2364692734 InternalChargerStatus 5;
BA_ "SPN" SG_ 2364692734 InternalChargerStatus 15329;
BA_ "SigType" SG_ 2364692734 CellBalancingActive 4;
BA_ "SPN" SG_ 2364692734 CellBalancingActive 15328;
BA_ "SigType" SG_ 2364692734 CellBalanceStatus 4;
BA_ "SPN" SG_ 2364692734 CellBalanceStatus 15327;
BA_ "SPN" SG_ 2364692734 StOfChargeStatus 15326;
BA_ "SigType" SG_ 2364692734 InertiaSwStatus 4;
BA_ "SPN" SG_ 2364692734 InertiaSwStatus 15325;
BA_ "SigType" SG_ 2364692734 HVILStatus 4;
BA_ "SPN" SG_ 2364692734 HVILStatus 15324;
BA_ "SPN" SG_ 2364692734 HVBusPassiveIsolTestStatus 15323;
BA_ "SPN" SG_ 2364692734 HVBusActiveIsolTestStatus 15322;
BA_ "SigType" SG_ 2364692734 CenterOfPackContactorSt 4;
BA_ "SPN" SG_ 2364692734 CenterOfPackContactorSt 15321;
BA_ "SigType" SG_ 2364692734 HVBusPreChargeRelaySt 4;
BA_ "SPN" SG_ 2364692734 HVBusPreChargeRelaySt 15320;
BA_ "SPN" SG_ 2364692734 HVBusDisconnectForewarning 15319;
BA_ "SigType" SG_ 2364692734 HVBusContactorSt15318 4;
BA_ "SPN" SG_ 2364692734 HVBusContactorSt15318 15318;
BA_ "SigType" SG_ 2364692734 HVBusContactorSt 4;
BA_ "SPN" SG_ 2364692734 HVBusContactorSt 15317;
BA_ "SigType" SG_ 2364692478 Temp 1;
BA_ "SPN" SG_ 2364692478 Temp 15316;
BA_ "SigType" SG_ 2364692478 ETemp 1;
BA_ "SPN" SG_ 2364692478 ETemp 15315;
BA_ "SigType" SG_ 2364692478 OutCoolantTemp 1;
BA_ "SPN" SG_ 2364692478 OutCoolantTemp 15314;
BA_ "SigType" SG_ 2364692478 InCoolantTemp 1;
BA_ "SPN" SG_ 2364692478 InCoolantTemp 15313;
BA_ "SigType" SG_ 2364692478 IgntV 1;
BA_ "SPN" SG_ 2364692478 IgntV 15312;
BA_ "SigType" SG_ 2364692478 BusV 1;
BA_ "SPN" SG_ 2364692478 BusV 15311;
BA_ "SigType" SG_ 2364692222 HighestCellStOfCharge 1;
BA_ "SPN" SG_ 2364692222 HighestCellStOfCharge 15310;
BA_ "SigType" SG_ 2364692222 LowestCellStOfCharge 1;
BA_ "SPN" SG_ 2364692222 LowestCellStOfCharge 15309;
BA_ "SigType" SG_ 2364692222 ChargeCurLmt 1;
BA_ "GenSigStartValue" SG_ 2364692222 ChargeCurLmt 32000;
BA_ "SPN" SG_ 2364692222 ChargeCurLmt 15308;
BA_ "SigType" SG_ 2364692222 DisCurLmt 1;
BA_ "SPN" SG_ 2364692222 DisCurLmt 15307;
BA_ "SigType" SG_ 2364691966 CellBalancingCount 1;
BA_ "SPN" SG_ 2364691966 CellBalancingCount 15306;
BA_ "SigType" SG_ 2364691966 ChargeCapacity 1;
BA_ "SPN" SG_ 2364691966 ChargeCapacity 15305;
BA_ "SigType" SG_ 2364691966 DisCapacity 1;
BA_ "SPN" SG_ 2364691966 DisCapacity 15304;
VAL_ 2364701694 Data9EmbeddedIntegritySupport 3 "CRC and Counter are not supported by the sender" 2 "Reserved" 1 "Protection is supported using J1939-76 SHM" 0 "Embedded CRC and Counter are supported by the sender" ;
VAL_ 2364701694 HVESS13ThermalEventDetected 3 "Not available" 2 "Error" 1 "Thermal Event Detected" 0 "No Thermal Event Detected" ;
VAL_ 2364701182 TMSCoolantLvl 3 "Not Available" 2 "Error" 1 "Coolant Level is sufficient" 0 "Coolant Level is not sufficient" ;
VAL_ 2364701182 TMSMode 15 "Not Available" 14 "Faulted" 13 "Reserved" 12 "Reserved" 11 "Reserved" 10 "Reserved" 9 "Reserved" 8 "Reserved" 7 "Reserved" 6 "Reserved" 5 "Maintaining" 4 "Drying" 3 "Heating" 2 "Cooling" 1 "Circulating" 0 "Off" ;
VAL_ 2364701182 TMSHVILStatus 3 "Not Available" 2 "Error" 1 "HVIL Open" 0 "HVIL Closed" ;
VAL_ 2364701182 TMSHtrStatus 3 "Not Available" 2 "Error" 1 "Heater On" 0 "Heater Off" ;
VAL_ 2364700926 Module32OperationalStatus 3 "Not Available" 2 "Error" 1 "Operational" 0 "Not Operational" ;
VAL_ 2364700926 Module31OperationalStatus 3 "Not Available" 2 "Error" 1 "Operational" 0 "Not Operational" ;
VAL_ 2364700926 Module30OperationalStatus 3 "Not Available" 2 "Error" 1 "Operational" 0 "Not Operational" ;
VAL_ 2364700926 Module29OperationalStatus 3 "Not Available" 2 "Error" 1 "Operational" 0 "Not Operational" ;
VAL_ 2364700926 Module28OperationalStatus 3 "Not Available" 2 "Error" 1 "Operational" 0 "Not Operational" ;
VAL_ 2364700926 Module27OperationalStatus 3 "Not Available" 2 "Error" 1 "Operational" 0 "Not Operational" ;
VAL_ 2364700926 Module26OperationalStatus 3 "Not Available" 2 "Error" 1 "Operational" 0 "Not Operational" ;
VAL_ 2364700926 Module25OperationalStatus 3 "Not Available" 2 "Error" 1 "Operational" 0 "Not Operational" ;
VAL_ 2364700926 Module24OperationalStatus 3 "Not Available" 2 "Error" 1 "Operational" 0 "Not Operational" ;
VAL_ 2364700926 Module23OperationalStatus 3 "Not Available" 2 "Error" 1 "Operational" 0 "Not Operational" ;
VAL_ 2364700926 Module22OperationalStatus 3 "Not Available" 2 "Error" 1 "Operational" 0 "Not Operational" ;
VAL_ 2364700926 Module21OperationalStatus 3 "Not Available" 2 "Error" 1 "Operational" 0 "Not Operational" ;
VAL_ 2364700926 Module20OperationalStatus 3 "Not Available" 2 "Error" 1 "Operational" 0 "Not Operational" ;
VAL_ 2364700926 Module19OperationalStatus 3 "Not Available" 2 "Error" 1 "Operational" 0 "Not Operational" ;
VAL_ 2364700926 Module18OperationalStatus 3 "Not Available" 2 "Error" 1 "Operational" 0 "Not Operational" ;
VAL_ 2364700926 Module17OperationalStatus 3 "Not Available" 2 "Error" 1 "Operational" 0 "Not Operational" ;
VAL_ 2364700926 Module16OperationalStatus 3 "Not Available" 2 "Error" 1 "Operational" 0 "Not Operational" ;
VAL_ 2364700926 Module15OperationalStatus 3 "Not Available" 2 "Error" 1 "Operational" 0 "Not Operational" ;
VAL_ 2364700926 Module14OperationalStatus 3 "Not Available" 2 "Error" 1 "Operational" 0 "Not Operational" ;
VAL_ 2364700926 Module13OperationalStatus 3 "Not Available" 2 "Error" 1 "Operational" 0 "Not Operational" ;
VAL_ 2364700926 Module12OperationalStatus 3 "Not Available" 2 "Error" 1 "Operational" 0 "Not Operational" ;
VAL_ 2364700926 Module11OperationalStatus 3 "Not Available" 2 "Error" 1 "Operational" 0 "Not Operational" ;
VAL_ 2364700926 Module10OperationalStatus 3 "Not Available" 2 "Error" 1 "Operational" 0 "Not Operational" ;
VAL_ 2364700926 Module9OperationalStatus 3 "Not Available" 2 "Error" 1 "Operational" 0 "Not Operational" ;
VAL_ 2364700926 Module8OperationalStatus 3 "Not Available" 2 "Error" 1 "Operational" 0 "Not Operational" ;
VAL_ 2364700926 Module7OperationalStatus 3 "Not Available" 2 "Error" 1 "Operational" 0 "Not Operational" ;
VAL_ 2364700926 Module6OperationalStatus 3 "Not Available" 2 "Error" 1 "Operational" 0 "Not Operational" ;
VAL_ 2364700926 Module5OperationalStatus 3 "Not Available" 2 "Error" 1 "Operational" 0 "Not Operational" ;
VAL_ 2364700926 Module4OperationalStatus 3 "Not Available" 2 "Error" 1 "Operational" 0 "Not Operational" ;
VAL_ 2364700926 Module3OperationalStatus 3 "Not Available" 2 "Error" 1 "Operational" 0 "Not Operational" ;
VAL_ 2364700926 Module2OperationalStatus 3 "Not Available" 2 "Error" 1 "Operational" 0 "Not Operational" ;
VAL_ 2364700926 Module1OperationalStatus 3 "Not Available" 2 "Error" 1 "Operational" 0 "Not Operational" ;
VAL_ 2364700414 OperationalStatus 15 "Not Available" 14 "Error" 13 "Reserved" 12 "Reserved" 11 "Reserved" 10 "Reserved" 9 "Reserved" 8 "Reserved" 7 "Reserved" 6 "Disabled by internal decision of HVES controller" 5 "Disabled by external command" 4 "Emergency Power-Down In Process" 3 "Normal Power-Down in Process" 2 "Operational." 1 "Initialization Complete" 0 "Initialization in process" ;
VAL_ 2364700414 HVBusConnectionStatus 15 "Not Available" 14 "Error" 13 "Reserved" 12 "Reserved" 11 "Reserved" 10 "Reserved" 9 "Reserved" 8 "Reserved" 7 "Reserved" 6 "Reserved" 5 "Reserved" 4 "Disconnected,  Precharge Failed" 3 "Disconnection in Process" 2 "Connection in Process" 1 "Connected" 0 "Disconnected, One or more contactors are open" ;
VAL_ 2364700414 InternalChargerStatus 3 "Not Available" 2 "Error" 1 "Charging on" 0 "Charging off" ;
VAL_ 2364700414 CellBalancingActive 3 "Not Available" 2 "Error" 1 "Cell balancing is active" 0 "Cell balancing is not active" ;
VAL_ 2364700414 CellBalanceStatus 3 "Not Available" 2 "Error" 1 "Cells are unbalanced" 0 "Cells are balanced" ;
VAL_ 2364700414 StOfChargeStatus 15 "Not  Available" 14 "Error" 13 "Reserved" 12 "Reserved" 11 "Reserved" 10 "Reserved" 9 "Reserved" 8 "Reserved" 7 "Reserved" 6 "SOC is above its recommended upper limit" 5 "SOC is at its recommended upper limit" 4 "SOC is approaching its recommended upper limit" 3 "SOC is below its recommended lower limit" 2 "SOC is at its recommended lower limit" 1 "SOC is approaching its recommended lower limit" 0 "SOC level is acceptable" ;
VAL_ 2364700414 InertiaSwStatus 3 "Not Available" 2 "Error" 1 "Impact sensed" 0 "No impact sensed" ;
VAL_ 2364700414 HVILStatus 3 "Not Available" 2 "Error" 1 "HVIL Open" 0 "HVIL Closed" ;
VAL_ 2364700414 HVBusPassiveIsolTestStatus 15 "Not available" 14 "Error" 13 "Reserved" 12 "Reserved" 11 "Reserved" 10 "Reserved" 9 "Reserved" 8 "Reserved" 7 "Reserved" 6 "Reserved" 5 "Test complete,  isolation fault" 4 "Test complete,  isolation marginal" 3 "Test complete,  isolation acceptable" 2 "Test in process" 1 "Test requested but not yet in process" 0 "No test requested / No test in process" ;
VAL_ 2364700414 HVBusActiveIsolTestStatus 15 "Not available" 14 "Error" 13 "Reserved" 12 "Reserved" 11 "Reserved" 10 "Reserved" 9 "Reserved" 8 "Reserved" 7 "Reserved" 6 "Reserved" 5 "Test complete,  isolation fault" 4 "Test complete,  isolation marginal" 3 "Test complete,  isolation acceptable" 2 "Test in process" 1 "Test requested but not yet in process" 0 "No test requested / No test in process" ;
VAL_ 2364700414 CenterOfPackContactorSt 3 "Not Available" 2 "Error" 1 "Contactor Closed" 0 "Contactor Open" ;
VAL_ 2364700414 HVBusPreChargeRelaySt 3 "Not Available" 2 "Error" 1 "Relay Closed" 0 "Relay Open" ;
VAL_ 2364700414 HVBusDisconnectForewarning 15 "Not Available" 14 "Error" 13 "Disconnect imminent" 12 "Reserved" 11 "Reserved" 10 "Reserved" 9 "Reserved" 8 "Reserved" 7 "Disconnect imminent due to battery pack current approaching maximum acceptable level" 6 "Disconnect imminent due to cell voltage approaching maximum acceptable level" 5 "Disconnect imminent due to cell voltage approaching minimum acceptable level" 4 "Disconnect imminent due to module voltage approaching maximum acceptable level" 3 "Disconnect imminent due to module voltage approaching minimum acceptable level" 2 "Disconnect imminent due to battery pack voltage approaching maximum acceptable level" 1 "Disconnect imminent due to battery pack voltage approaching minimum acceptable level" 0 "Disconnect not pending" ;
VAL_ 2364700414 HVBusContactorSt15602 3 "Not Available" 2 "Error" 1 "Contactor Closed" 0 "Contactor Open" ;
VAL_ 2364700414 HVBusContactorSt 3 "Not Available" 2 "Error" 1 "Contactor Closed" 0 "Contactor Open" ;
VAL_ 2364699390 CellTempDiffStatus 3 "Not Available" 2 "Error" 1 "Cell-to-cell temperature differential exceeds acceptable limits" 0 "Cell-to-cell temperature differential is within acceptable limits" ;
VAL_ 2364699134 CellVDiffStatus 15 "Not Available" 14 "Error" 13 "Reserved" 12 "Reserved" 11 "Reserved" 10 "Reserved" 9 "Reserved" 8 "Reserved" 7 "Reserved" 6 "Reserved" 5 "Reserved" 4 "Exceeds limits and it is not known whether balancing can restore performance" 3 "Exceeds limits and external maintenance balancing cannot restore performance" 2 "Exceeds limits and external maintenance balancing is required" 1 "Exceeds limits and can be corrected via auto-balancing" 0 "Is within acceptable limits" ;
VAL_ 2364698622 ChargePLDueToAnUndefinedCause 3 "Not Available" 2 "Error" 1 "Power limited for this reason" 0 "No power limit for this reason" ;
VAL_ 2364698622 ChargePLDueToBatCur 3 "Not Available" 2 "Error" 1 "Power limited for this reason" 0 "No power limit for this reason" ;
VAL_ 2364698622 ChargePLDueToBatOrCellV 3 "Not Available" 2 "Error" 1 "Power limited for this reason" 0 "No power limit for this reason" ;
VAL_ 2364698622 ChargePLDueToBatDiagCondition 3 "Not Available" 2 "Error" 1 "Power limited for this reason" 0 "No power limit for this reason" ;
VAL_ 2364698622 ChargePLDueToBatTemp 3 "Not Available" 2 "Error" 1 "Power limited for this reason" 0 "No power limit for this reason" ;
VAL_ 2364698622 ChargePLDueToStOfCharge 3 "Not Available" 2 "Error" 1 "Power limited for this reason" 0 "No power limit for this reason" ;
VAL_ 2364698622 DisPLDueToAnUndefinedCause 3 "Not Available" 2 "Error" 1 "Power limited for this reason" 0 "No power limit for this reason" ;
VAL_ 2364698622 DisPLDueToBatCur 3 "Not Available" 2 "Error" 1 "Power limited for this reason" 0 "No power limit for this reason" ;
VAL_ 2364698622 DisPLDueToBatOrCellV 3 "Not Available" 2 "Error" 1 "Power limited for this reason" 0 "No power limit for this reason" ;
VAL_ 2364698622 DisPLDueToBatDiagCondition 3 "Not Available" 2 "Error" 1 "Power limited for this reason" 0 "No power limit for this reason" ;
VAL_ 2364698622 DisPLDueToBatTemp 3 "Not Available" 2 "Error" 1 "Power limited for this reason" 0 "No power limit for this reason" ;
VAL_ 2364698622 DisPLDueToStOfCharge 3 "Not Available" 2 "Error" 1 "Power limited for this reason" 0 "No power limit for this reason" ;
VAL_ 2364697854 Data9EmbeddedIntegritySupport 3 "CRC and Counter are not supported by the sender" 2 "Reserved" 1 "Protection is supported using J1939-76 SHM" 0 "Embedded CRC and Counter are supported by the sender" ;
VAL_ 2364697854 HVESS12ThermalEventDetected 3 "Not available" 2 "Error" 1 "Thermal Event Detected" 0 "No Thermal Event Detected" ;
VAL_ 2364697342 TMSCoolantLvl 3 "Not Available" 2 "Error" 1 "Coolant Level is sufficient" 0 "Coolant Level is not sufficient" ;
VAL_ 2364697342 TMSMode 15 "Not Available" 14 "Faulted" 13 "Reserved" 12 "Reserved" 11 "Reserved" 10 "Reserved" 9 "Reserved" 8 "Reserved" 7 "Reserved" 6 "Reserved" 5 "Maintaining" 4 "Drying" 3 "Heating" 2 "Cooling" 1 "Circulating" 0 "Off" ;
VAL_ 2364697342 TMSHVILStatus 3 "Not Available" 2 "Error" 1 "HVIL Open" 0 "HVIL Closed" ;
VAL_ 2364697342 TMSHtrStatus 3 "Not Available" 2 "Error" 1 "Heater On" 0 "Heater Off" ;
VAL_ 2364697086 Module32OperationalStatus 3 "Not Available" 2 "Error" 1 "Operational" 0 "Not Operational" ;
VAL_ 2364697086 Module31OperationalStatus 3 "Not Available" 2 "Error" 1 "Operational" 0 "Not Operational" ;
VAL_ 2364697086 Module30OperationalStatus 3 "Not Available" 2 "Error" 1 "Operational" 0 "Not Operational" ;
VAL_ 2364697086 Module29OperationalStatus 3 "Not Available" 2 "Error" 1 "Operational" 0 "Not Operational" ;
VAL_ 2364697086 Module28OperationalStatus 3 "Not Available" 2 "Error" 1 "Operational" 0 "Not Operational" ;
VAL_ 2364697086 Module27OperationalStatus 3 "Not Available" 2 "Error" 1 "Operational" 0 "Not Operational" ;
VAL_ 2364697086 Module26OperationalStatus 3 "Not Available" 2 "Error" 1 "Operational" 0 "Not Operational" ;
VAL_ 2364697086 Module25OperationalStatus 3 "Not Available" 2 "Error" 1 "Operational" 0 "Not Operational" ;
VAL_ 2364697086 Module24OperationalStatus 3 "Not Available" 2 "Error" 1 "Operational" 0 "Not Operational" ;
VAL_ 2364697086 Module23OperationalStatus 3 "Not Available" 2 "Error" 1 "Operational" 0 "Not Operational" ;
VAL_ 2364697086 Module22OperationalStatus 3 "Not Available" 2 "Error" 1 "Operational" 0 "Not Operational" ;
VAL_ 2364697086 Module21OperationalStatus 3 "Not Available" 2 "Error" 1 "Operational" 0 "Not Operational" ;
VAL_ 2364697086 Module20OperationalStatus 3 "Not Available" 2 "Error" 1 "Operational" 0 "Not Operational" ;
VAL_ 2364697086 Module19OperationalStatus 3 "Not Available" 2 "Error" 1 "Operational" 0 "Not Operational" ;
VAL_ 2364697086 Module18OperationalStatus 3 "Not Available" 2 "Error" 1 "Operational" 0 "Not Operational" ;
VAL_ 2364697086 Module17OperationalStatus 3 "Not Available" 2 "Error" 1 "Operational" 0 "Not Operational" ;
VAL_ 2364697086 Module16OperationalStatus 3 "Not Available" 2 "Error" 1 "Operational" 0 "Not Operational" ;
VAL_ 2364697086 Module15OperationalStatus 3 "Not Available" 2 "Error" 1 "Operational" 0 "Not Operational" ;
VAL_ 2364697086 Module14OperationalStatus 3 "Not Available" 2 "Error" 1 "Operational" 0 "Not Operational" ;
VAL_ 2364697086 Module13OperationalStatus 3 "Not Available" 2 "Error" 1 "Operational" 0 "Not Operational" ;
VAL_ 2364697086 Module12OperationalStatus 3 "Not Available" 2 "Error" 1 "Operational" 0 "Not Operational" ;
VAL_ 2364697086 Module11OperationalStatus 3 "Not Available" 2 "Error" 1 "Operational" 0 "Not Operational" ;
VAL_ 2364697086 Module10OperationalStatus 3 "Not Available" 2 "Error" 1 "Operational" 0 "Not Operational" ;
VAL_ 2364697086 Module9OperationalStatus 3 "Not Available" 2 "Error" 1 "Operational" 0 "Not Operational" ;
VAL_ 2364697086 Module8OperationalStatus 3 "Not Available" 2 "Error" 1 "Operational" 0 "Not Operational" ;
VAL_ 2364697086 Module7OperationalStatus 3 "Not Available" 2 "Error" 1 "Operational" 0 "Not Operational" ;
VAL_ 2364697086 Module6OperationalStatus 3 "Not Available" 2 "Error" 1 "Operational" 0 "Not Operational" ;
VAL_ 2364697086 Module5OperationalStatus 3 "Not Available" 2 "Error" 1 "Operational" 0 "Not Operational" ;
VAL_ 2364697086 Module4OperationalStatus 3 "Not Available" 2 "Error" 1 "Operational" 0 "Not Operational" ;
VAL_ 2364697086 Module3OperationalStatus 3 "Not Available" 2 "Error" 1 "Operational" 0 "Not Operational" ;
VAL_ 2364697086 Module2OperationalStatus 3 "Not Available" 2 "Error" 1 "Operational" 0 "Not Operational" ;
VAL_ 2364697086 Module1OperationalStatus 3 "Not Available" 2 "Error" 1 "Operational" 0 "Not Operational" ;
VAL_ 2364696574 OperationalStatus 15 "Not Available" 14 "Error" 13 "Reserved" 12 "Reserved" 11 "Reserved" 10 "Reserved" 9 "Reserved" 8 "Reserved" 7 "Reserved" 6 "Disabled by internal decision of HVES controller" 5 "Disabled by external command" 4 "Emergency Power-Down In Process" 3 "Normal Power-Down in Process" 2 "Operational." 1 "Initialization Complete" 0 "Initialization in process" ;
VAL_ 2364696574 HVBusConnectionStatus 15 "Not Available" 14 "Error" 13 "Reserved" 12 "Reserved" 11 "Reserved" 10 "Reserved" 9 "Reserved" 8 "Reserved" 7 "Reserved" 6 "Reserved" 5 "Reserved" 4 "Disconnected,  Precharge Failed" 3 "Disconnection in Process" 2 "Connection in Process" 1 "Connected" 0 "Disconnected, One or more contactors are open" ;
VAL_ 2364696574 InternalChargerStatus 3 "Not Available" 2 "Error" 1 "Charging on" 0 "Charging off" ;
VAL_ 2364696574 CellBalancingActive 3 "Not Available" 2 "Error" 1 "Cell balancing is active" 0 "Cell balancing is not active" ;
VAL_ 2364696574 CellBalanceStatus 3 "Not Available" 2 "Error" 1 "Cells are unbalanced" 0 "Cells are balanced" ;
VAL_ 2364696574 StOfChargeStatus 15 "Not  Available" 14 "Error" 13 "Reserved" 12 "Reserved" 11 "Reserved" 10 "Reserved" 9 "Reserved" 8 "Reserved" 7 "Reserved" 6 "SOC is above its recommended upper limit" 5 "SOC is at its recommended upper limit" 4 "SOC is approaching its recommended upper limit" 3 "SOC is below its recommended lower limit" 2 "SOC is at its recommended lower limit" 1 "SOC is approaching its recommended lower limit" 0 "SOC level is acceptable" ;
VAL_ 2364696574 InertiaSwStatus 3 "Not Available" 2 "Error" 1 "Impact sensed" 0 "No impact sensed" ;
VAL_ 2364696574 HVILStatus 3 "Not Available" 2 "Error" 1 "HVIL Open" 0 "HVIL Closed" ;
VAL_ 2364696574 HVBusPassiveIsolTestStatus 15 "Not available" 14 "Error" 13 "Reserved" 12 "Reserved" 11 "Reserved" 10 "Reserved" 9 "Reserved" 8 "Reserved" 7 "Reserved" 6 "Reserved" 5 "Test complete,  isolation fault" 4 "Test complete,  isolation marginal" 3 "Test complete,  isolation acceptable" 2 "Test in process" 1 "Test requested but not yet in process" 0 "No test requested / No test in process" ;
VAL_ 2364696574 HVBusActiveIsolTestStatus 15 "Not available" 14 "Error" 13 "Reserved" 12 "Reserved" 11 "Reserved" 10 "Reserved" 9 "Reserved" 8 "Reserved" 7 "Reserved" 6 "Reserved" 5 "Test complete,  isolation fault" 4 "Test complete,  isolation marginal" 3 "Test complete,  isolation acceptable" 2 "Test in process" 1 "Test requested but not yet in process" 0 "No test requested / No test in process" ;
VAL_ 2364696574 CenterOfPackContactorSt 3 "Not Available" 2 "Error" 1 "Contactor Closed" 0 "Contactor Open" ;
VAL_ 2364696574 HVBusPreChargeRelaySt 3 "Not Available" 2 "Error" 1 "Relay Closed" 0 "Relay Open" ;
VAL_ 2364696574 HVBusDisconnectForewarning 15 "Not Available" 14 "Error" 13 "Disconnect imminent" 12 "Reserved" 11 "Reserved" 10 "Reserved" 9 "Reserved" 8 "Reserved" 7 "Disconnect imminent due to battery pack current approaching maximum acceptable level" 6 "Disconnect imminent due to cell voltage approaching maximum acceptable level" 5 "Disconnect imminent due to cell voltage approaching minimum acceptable level" 4 "Disconnect imminent due to module voltage approaching maximum acceptable level" 3 "Disconnect imminent due to module voltage approaching minimum acceptable level" 2 "Disconnect imminent due to battery pack voltage approaching maximum acceptable level" 1 "Disconnect imminent due to battery pack voltage approaching minimum acceptable level" 0 "Disconnect not pending" ;
VAL_ 2364696574 HVBusContactorSt15460 3 "Not Available" 2 "Error" 1 "Contactor Closed" 0 "Contactor Open" ;
VAL_ 2364696574 HVBusContactorSt 3 "Not Available" 2 "Error" 1 "Contactor Closed" 0 "Contactor Open" ;
VAL_ 2364695550 CellTempDiffStatus 3 "Not Available" 2 "Error" 1 "Cell-to-cell temperature differential exceeds acceptable limits" 0 "Cell-to-cell temperature differential is within acceptable limits" ;
VAL_ 2364695294 CellVDiffStatus 15 "Not Available" 14 "Error" 13 "Reserved" 12 "Reserved" 11 "Reserved" 10 "Reserved" 9 "Reserved" 8 "Reserved" 7 "Reserved" 6 "Reserved" 5 "Reserved" 4 "Exceeds limits and it is not known whether balancing can restore performance" 3 "Exceeds limits and external maintenance balancing cannot restore performance" 2 "Exceeds limits and external maintenance balancing is required" 1 "Exceeds limits and can be corrected via auto-balancing" 0 "Is within acceptable limits" ;
VAL_ 2364694782 ChargePLDueToAnUndefinedCause 3 "Not Available" 2 "Error" 1 "Power limited for this reason" 0 "No power limit for this reason" ;
VAL_ 2364694782 ChargePLDueToBatCur 3 "Not Available" 2 "Error" 1 "Power limited for this reason" 0 "No power limit for this reason" ;
VAL_ 2364694782 ChargePLDueToBatOrCellV 3 "Not Available" 2 "Error" 1 "Power limited for this reason" 0 "No power limit for this reason" ;
VAL_ 2364694782 ChargePLDueToBatDiagCondition 3 "Not Available" 2 "Error" 1 "Power limited for this reason" 0 "No power limit for this reason" ;
VAL_ 2364694782 ChargePLDueToBatTemp 3 "Not Available" 2 "Error" 1 "Power limited for this reason" 0 "No power limit for this reason" ;
VAL_ 2364694782 ChargePLDueToStOfCharge 3 "Not Available" 2 "Error" 1 "Power limited for this reason" 0 "No power limit for this reason" ;
VAL_ 2364694782 DisPLDueToAnUndefinedCause 3 "Not Available" 2 "Error" 1 "Power limited for this reason" 0 "No power limit for this reason" ;
VAL_ 2364694782 DisPLDueToBatCur 3 "Not Available" 2 "Error" 1 "Power limited for this reason" 0 "No power limit for this reason" ;
VAL_ 2364694782 DisPLDueToBatOrCellV 3 "Not Available" 2 "Error" 1 "Power limited for this reason" 0 "No power limit for this reason" ;
VAL_ 2364694782 DisPLDueToBatDiagCondition 3 "Not Available" 2 "Error" 1 "Power limited for this reason" 0 "No power limit for this reason" ;
VAL_ 2364694782 DisPLDueToBatTemp 3 "Not Available" 2 "Error" 1 "Power limited for this reason" 0 "No power limit for this reason" ;
VAL_ 2364694782 DisPLDueToStOfCharge 3 "Not Available" 2 "Error" 1 "Power limited for this reason" 0 "No power limit for this reason" ;
VAL_ 2364694014 Data9EmbeddedIntegritySupport 3 "CRC and Counter are not supported by the sender" 2 "Reserved" 1 "Protection is supported using J1939-76 SHM" 0 "Embedded CRC and Counter are supported by the sender" ;
VAL_ 2364694014 HVESS11ThermalEventDetected 3 "Not available" 2 "Error" 1 "Thermal Event Detected" 0 "No Thermal Event Detected" ;
VAL_ 2364693502 TMSCoolantLvl 3 "Not Available" 2 "Error" 1 "Coolant Level is sufficient" 0 "Coolant Level is not sufficient" ;
VAL_ 2364693502 TMSMode 15 "Not Available" 14 "Faulted" 13 "Reserved" 12 "Reserved" 11 "Reserved" 10 "Reserved" 9 "Reserved" 8 "Reserved" 7 "Reserved" 6 "Reserved" 5 "Maintaining" 4 "Drying" 3 "Heating" 2 "Cooling" 1 "Circulating" 0 "Off" ;
VAL_ 2364693502 TMSHVILStatus 3 "Not Available" 2 "Error" 1 "HVIL Open" 0 "HVIL Closed" ;
VAL_ 2364693502 TMSHtrStatus 3 "Not Available" 2 "Error" 1 "Heater On" 0 "Heater Off" ;
VAL_ 2364693246 Module32OperationalStatus 3 "Not Available" 2 "Error" 1 "Operational" 0 "Not Operational" ;
VAL_ 2364693246 Module31OperationalStatus 3 "Not Available" 2 "Error" 1 "Operational" 0 "Not Operational" ;
VAL_ 2364693246 Module30OperationalStatus 3 "Not Available" 2 "Error" 1 "Operational" 0 "Not Operational" ;
VAL_ 2364693246 Module29OperationalStatus 3 "Not Available" 2 "Error" 1 "Operational" 0 "Not Operational" ;
VAL_ 2364693246 Module28OperationalStatus 3 "Not Available" 2 "Error" 1 "Operational" 0 "Not Operational" ;
VAL_ 2364693246 Module27OperationalStatus 3 "Not Available" 2 "Error" 1 "Operational" 0 "Not Operational" ;
VAL_ 2364693246 Module26OperationalStatus 3 "Not Available" 2 "Error" 1 "Operational" 0 "Not Operational" ;
VAL_ 2364693246 Module25OperationalStatus 3 "Not Available" 2 "Error" 1 "Operational" 0 "Not Operational" ;
VAL_ 2364693246 Module24OperationalStatus 3 "Not Available" 2 "Error" 1 "Operational" 0 "Not Operational" ;
VAL_ 2364693246 Module23OperationalStatus 3 "Not Available" 2 "Error" 1 "Operational" 0 "Not Operational" ;
VAL_ 2364693246 Module22OperationalStatus 3 "Not Available" 2 "Error" 1 "Operational" 0 "Not Operational" ;
VAL_ 2364693246 Module21OperationalStatus 3 "Not Available" 2 "Error" 1 "Operational" 0 "Not Operational" ;
VAL_ 2364693246 Module20OperationalStatus 3 "Not Available" 2 "Error" 1 "Operational" 0 "Not Operational" ;
VAL_ 2364693246 Module19OperationalStatus 3 "Not Available" 2 "Error" 1 "Operational" 0 "Not Operational" ;
VAL_ 2364693246 Module18OperationalStatus 3 "Not Available" 2 "Error" 1 "Operational" 0 "Not Operational" ;
VAL_ 2364693246 Module17OperationalStatus 3 "Not Available" 2 "Error" 1 "Operational" 0 "Not Operational" ;
VAL_ 2364693246 Module16OperationalStatus 3 "Not Available" 2 "Error" 1 "Operational" 0 "Not Operational" ;
VAL_ 2364693246 Module15OperationalStatus 3 "Not Available" 2 "Error" 1 "Operational" 0 "Not Operational" ;
VAL_ 2364693246 Module14OperationalStatus 3 "Not Available" 2 "Error" 1 "Operational" 0 "Not Operational" ;
VAL_ 2364693246 Module13OperationalStatus 3 "Not Available" 2 "Error" 1 "Operational" 0 "Not Operational" ;
VAL_ 2364693246 Module12OperationalStatus 3 "Not Available" 2 "Error" 1 "Operational" 0 "Not Operational" ;
VAL_ 2364693246 Module11OperationalStatus 3 "Not Available" 2 "Error" 1 "Operational" 0 "Not Operational" ;
VAL_ 2364693246 Module10OperationalStatus 3 "Not Available" 2 "Error" 1 "Operational" 0 "Not Operational" ;
VAL_ 2364693246 Module9OperationalStatus 3 "Not Available" 2 "Error" 1 "Operational" 0 "Not Operational" ;
VAL_ 2364693246 Module8OperationalStatus 3 "Not Available" 2 "Error" 1 "Operational" 0 "Not Operational" ;
VAL_ 2364693246 Module7OperationalStatus 3 "Not Available" 2 "Error" 1 "Operational" 0 "Not Operational" ;
VAL_ 2364693246 Module6OperationalStatus 3 "Not Available" 2 "Error" 1 "Operational" 0 "Not Operational" ;
VAL_ 2364693246 Module5OperationalStatus 3 "Not Available" 2 "Error" 1 "Operational" 0 "Not Operational" ;
VAL_ 2364693246 Module4OperationalStatus 3 "Not Available" 2 "Error" 1 "Operational" 0 "Not Operational" ;
VAL_ 2364693246 Module3OperationalStatus 3 "Not Available" 2 "Error" 1 "Operational" 0 "Not Operational" ;
VAL_ 2364693246 Module2OperationalStatus 3 "Not Available" 2 "Error" 1 "Operational" 0 "Not Operational" ;
VAL_ 2364693246 Module1OperationalStatus 3 "Not Available" 2 "Error" 1 "Operational" 0 "Not Operational" ;
VAL_ 2364692734 OperationalStatus 15 "Not Available" 14 "Error" 13 "Reserved" 12 "Reserved" 11 "Reserved" 10 "Reserved" 9 "Reserved" 8 "Reserved" 7 "Reserved" 6 "Disabled by internal decision of HVES controller" 5 "Disabled by external command" 4 "Emergency Power-Down In Process" 3 "Normal Power-Down in Process" 2 "Operational." 1 "Initialization Complete" 0 "Initialization in process" ;
VAL_ 2364692734 HVBusConnectionStatus 15 "Not Available" 14 "Error" 13 "Reserved" 12 "Reserved" 11 "Reserved" 10 "Reserved" 9 "Reserved" 8 "Reserved" 7 "Reserved" 6 "Reserved" 5 "Reserved" 4 "Disconnected,  Precharge Failed" 3 "Disconnection in Process" 2 "Connection in Process" 1 "Connected" 0 "Disconnected, One or more contactors are open" ;
VAL_ 2364692734 InternalChargerStatus 3 "Not Available" 2 "Error" 1 "Charging on" 0 "Charging off" ;
VAL_ 2364692734 CellBalancingActive 3 "Not Available" 2 "Error" 1 "Cell balancing is active" 0 "Cell balancing is not active" ;
VAL_ 2364692734 CellBalanceStatus 3 "Not Available" 2 "Error" 1 "Cells are unbalanced" 0 "Cells are balanced" ;
VAL_ 2364692734 StOfChargeStatus 15 "Not  Available" 14 "Error" 13 "Reserved" 12 "Reserved" 11 "Reserved" 10 "Reserved" 9 "Reserved" 8 "Reserved" 7 "Reserved" 6 "SOC is above its recommended upper limit" 5 "SOC is at its recommended upper limit" 4 "SOC is approaching its recommended upper limit" 3 "SOC is below its recommended lower limit" 2 "SOC is at its recommended lower limit" 1 "SOC is approaching its recommended lower limit" 0 "SOC level is acceptable" ;
VAL_ 2364692734 InertiaSwStatus 3 "Not Available" 2 "Error" 1 "Impact sensed" 0 "No impact sensed" ;
VAL_ 2364692734 HVILStatus 3 "Not Available" 2 "Error" 1 "HVIL Open" 0 "HVIL Closed" ;
VAL_ 2364692734 HVBusPassiveIsolTestStatus 15 "Not available" 14 "Error" 13 "Reserved" 12 "Reserved" 11 "Reserved" 10 "Reserved" 9 "Reserved" 8 "Reserved" 7 "Reserved" 6 "Reserved" 5 "Test complete,  isolation fault" 4 "Test complete,  isolation marginal" 3 "Test complete,  isolation acceptable" 2 "Test in process" 1 "Test requested but not yet in process" 0 "No test requested / No test in process" ;
VAL_ 2364692734 HVBusActiveIsolTestStatus 15 "Not available" 14 "Error" 13 "Reserved" 12 "Reserved" 11 "Reserved" 10 "Reserved" 9 "Reserved" 8 "Reserved" 7 "Reserved" 6 "Reserved" 5 "Test complete,  isolation fault" 4 "Test complete,  isolation marginal" 3 "Test complete,  isolation acceptable" 2 "Test in process" 1 "Test requested but not yet in process" 0 "No test requested / No test in process" ;
VAL_ 2364692734 CenterOfPackContactorSt 3 "Not Available" 2 "Error" 1 "Contactor Closed" 0 "Contactor Open" ;
VAL_ 2364692734 HVBusPreChargeRelaySt 3 "Not Available" 2 "Error" 1 "Relay Closed" 0 "Relay Open" ;
VAL_ 2364692734 HVBusDisconnectForewarning 15 "Not Available" 14 "Error" 13 "Disconnect imminent" 12 "Reserved" 11 "Reserved" 10 "Reserved" 9 "Reserved" 8 "Reserved" 7 "Disconnect imminent due to battery pack current approaching maximum acceptable level" 6 "Disconnect imminent due to cell voltage approaching maximum acceptable level" 5 "Disconnect imminent due to cell voltage approaching minimum acceptable level" 4 "Disconnect imminent due to module voltage approaching maximum acceptable level" 3 "Disconnect imminent due to module voltage approaching minimum acceptable level" 2 "Disconnect imminent due to battery pack voltage approaching maximum acceptable level" 1 "Disconnect imminent due to battery pack voltage approaching minimum acceptable level" 0 "Disconnect not pending" ;
VAL_ 2364692734 HVBusContactorSt15318 3 "Not Available" 2 "Error" 1 "Contactor Closed" 0 "Contactor Open" ;
VAL_ 2364692734 HVBusContactorSt 3 "Not Available" 2 "Error" 1 "Contactor Closed" 0 "Contactor Open" ;
